VERSION "xyz"

NS_ :

BS_:

BU_: CabDisplay2 SafetyRestraintSystem AftertreatmentSystemGasOutlet AftertreatmentSystemGasIntake Turbocharger OnBoardDataLogger OffBoardDiagnosticTool2 OffBoardDiagnosticTool1 FileServer ParkingBrakeController SeatControl2 FanDriveController SteeringColumnUnit CommunicationUnitRadio CommunicationUnitSatellite CommunicationUnitCellular PropulsionBatteryCharger ChassisController2 ChassisController1 EngineValveControl AuxiliaryHeater2 AuxiliaryHeater1 ClutchUnit RampControl InformationSystem1 SuspensionSystemController2 OilSensor VehicleDynamicStability ExhaustEmissionController TransmissionDisplay2 TransmissionDisplay1 ClimateControl2 WaterPumpController RearAxleSteeringController LightingOperatorControl SeatController1 IgnitionController2 IgnitionController1 TirePressureController CabController2 CabController1 PneumaticSystemController SuspensionSystemController1 HydraulicPumpController EnduranceBrakingSystem RetarderExhaustEngine2 OnBoardDiagnosticUnit HeadwayController RetarderExhaustEngine1 CabDisplay1 ManagementComputer VirtualTerminal OffVehicleGateway PowerTakeOffFront HitchControl AuxiliaryValveControl BodyController TractorTrailerBridge1 StarterSystem ElectricalSystem VehicleSecurity VehicleNavigation AerodynamicControl ElectricalChargingSystem ClimateControl1 TripRecorder InstrumentCluster SuspensionDriveAxle2 SuspensionDriveAxle1 SuspensionSteerAxle SteeringController FuelSystem CruiseControl RetarderDriveline RetarderEngine BrakesDriveAxle2 BrakesDriveAxle1 BrakesSystemController BrakesSteerAxle AxleDrive2 AxleDrive1 AxleSteering PowerTakeOff ShiftConsoleSecondary ShiftConsolePrimary Transmission2 Transmission1 Engine2 Engine1

BO_ 2563833598 CL: 8 Vector__XXX
 SG_ IlluminationBrightnessPercent : 0|8@1+ (0.4,0) [0|100] "%" Vector__XXX

BO_ 2566843390 CI: 8 Vector__XXX

BO_ 2566844926 CCVS: 8 Vector__XXX
 SG_ ParkBrakeReleaseInhibitRq : 6|2@1+ (1,0) [0|3] "" Vector__XXX
 SG_ EngShutdownOverrideSwitch : 62|2@1+ (1,0) [0|3] "" Vector__XXX
 SG_ EngTestModeSwitch : 60|2@1+ (1,0) [0|3] "" Vector__XXX
 SG_ EngIdleDecrementSwitch : 58|2@1+ (1,0) [0|3] "" Vector__XXX
 SG_ EngIdleIncrementSwitch : 56|2@1+ (1,0) [0|3] "" Vector__XXX
 SG_ CruiseCtrlStates : 53|3@1+ (1,0) [0|7] "" Vector__XXX
 SG_ PTOState : 48|5@1+ (1,0) [0|31] "" Vector__XXX
 SG_ CruiseCtrlSetSpeed : 40|8@1+ (1,0) [0|250] "km/h" Vector__XXX
 SG_ CruiseCtrlAccelerateSwitch : 38|2@1+ (1,0) [0|3] "" Vector__XXX
 SG_ CruiseCtrlResumeSwitch : 36|2@1+ (1,0) [0|3] "" Vector__XXX
 SG_ CruiseCtrlCoastSwitch : 34|2@1+ (1,0) [0|3] "" Vector__XXX
 SG_ CruiseCtrlSetSwitch : 32|2@1+ (1,0) [0|3] "" Vector__XXX
 SG_ ClutchSwitch : 30|2@1+ (1,0) [0|3] "" Vector__XXX
 SG_ BrakeSwitch : 28|2@1+ (1,0) [0|3] "" Vector__XXX
 SG_ CruiseCtrlEnableSwitch : 26|2@1+ (1,0) [0|3] "" Vector__XXX
 SG_ CruiseCtrlActive : 24|2@1+ (1,0) [0|3] "" Vector__XXX
 SG_ WheelBasedVehicleSpeed : 8|16@1+ (0.00390625,0) [0|250.996] "km/h" Vector__XXX
 SG_ CruiseCtrlPauseSwitch : 4|2@1+ (1,0) [0|3] "" Vector__XXX
 SG_ ParkingBrakeSwitch : 2|2@1+ (1,0) [0|3] "" Vector__XXX
 SG_ TwoSpeedAxleSwitch : 0|2@1+ (1,0) [0|3] "" Vector__XXX

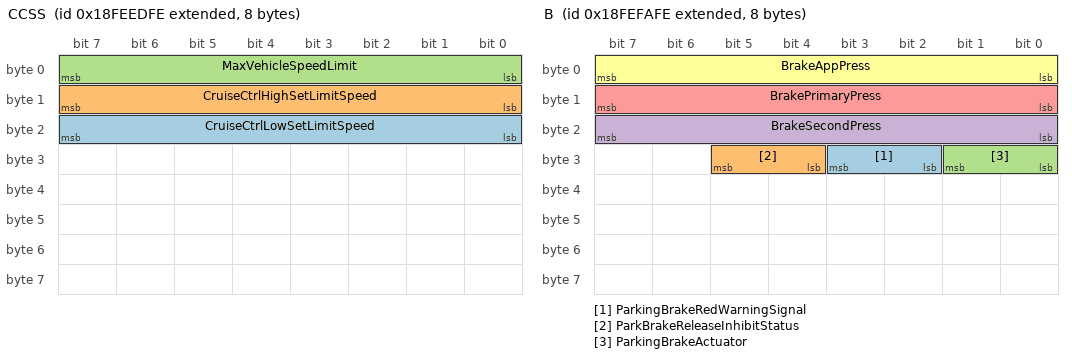
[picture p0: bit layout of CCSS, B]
BO_ 2566843902 CCSS: 8 Vector__XXX
 SG_ CruiseCtrlLowSetLimitSpeed : 16|8@1+ (1,0) [0|250] "km/h" Vector__XXX
 SG_ CruiseCtrlHighSetLimitSpeed : 8|8@1+ (1,0) [0|250] "km/h" Vector__XXX
 SG_ MaxVehicleSpeedLimit : 0|8@1+ (1,0) [0|250] "km/h" Vector__XXX

BO_ 2566809598 CCC: 8 Vector__XXX
 SG_ AuxHeaterMaxOutputPower : 0|16@1+ (2,0) [0|128510] "W" Vector__XXX

BO_ 2633940222 CBI: 16 Vector__XXX
 SG_ TripServiceBrakeApps : 96|32@1+ (1,0) [0|4227858431] "" Vector__XXX
 SG_ TripServiceBrakeDistance : 64|32@1+ (0.125,0) [0|526385151.9] "km" Vector__XXX
 SG_ TripCompressionBrakeDistance : 32|32@1+ (0.125,0) [0|526385151.9] "km" Vector__XXX
 SG_ TotalCompressionBrakeDistance : 0|32@1+ (0.125,0) [0|526385151.9] "km" Vector__XXX

BO_ 2566775294 CACI: 8 Vector__XXX
 SG_ CbA_CRfrgrntCmprssorOutletPress : 0|8@1+ (16,0) [0|4000] "kPa" Vector__XXX

BO_ 2566803710 BT1: 8 Vector__XXX
 SG_ Battery2Temp : 8|8@1+ (1,-40) [-40|210] "deg" Vector__XXX
 SG_ Battery1Temp : 0|8@1+ (1,-40) [-40|210] "deg" Vector__XXX

BO_ 2566809342 BM: 8 Vector__XXX
 SG_ BatteryMainSwitchHoldState : 0|2@1+ (1,0) [0|3] "" Vector__XXX

BO_ 2365446910 BJM3: 8 Vector__XXX
 SG_ Joystick3XAxisDetentPosStatus : 38|2@1+ (1,0) [0|3] "" Vector__XXX
 SG_ Joystick3Button9PressedStatus : 62|2@1+ (1,0) [0|3] "" Vector__XXX
 SG_ Joystick3Button10PressedStatus : 60|2@1+ (1,0) [0|3] "" Vector__XXX
 SG_ Joystick3Button11PressedStatus : 58|2@1+ (1,0) [0|3] "" Vector__XXX
 SG_ Joystick3Button12PressedStatus : 56|2@1+ (1,0) [0|3] "" Vector__XXX
 SG_ Joystick3YAxisDetentPosStatus : 36|2@1+ (1,0) [0|3] "" Vector__XXX
 SG_ Joystick3YAxisPos : 22|10@1+ (0.1,0) [0|102] "%" Vector__XXX
 SG_ Jystck3YAxsLvrFrwrdPstvPsStatus : 20|2@1+ (1,0) [0|3] "" Vector__XXX
 SG_ Jystck3YAxsLvrBckNgtvePosStatus : 18|2@1+ (1,0) [0|3] "" Vector__XXX
 SG_ Joystick3YAxisNeutralPosStatus : 16|2@1+ (1,0) [0|3] "" Vector__XXX
 SG_ Joystick3XAxisPos : 6|10@1+ (0.1,0) [0|102] "%" Vector__XXX
 SG_ Jystck3XAxsLvrRghtPstvPosStatus : 4|2@1+ (1,0) [0|3] "" Vector__XXX
 SG_ Jystck3XAxsLvrLftNgtvePosStatus : 2|2@1+ (1,0) [0|3] "" Vector__XXX
 SG_ Joystick3XAxisNeutralPosStatus : 0|2@1+ (1,0) [0|3] "" Vector__XXX
 SG_ Joystick3Button5PressedStatus : 54|2@1+ (1,0) [0|3] "" Vector__XXX
 SG_ Joystick3Button6PressedStatus : 52|2@1+ (1,0) [0|3] "" Vector__XXX
 SG_ Joystick3Button7PressedStatus : 50|2@1+ (1,0) [0|3] "" Vector__XXX
 SG_ Joystick3Button8PressedStatus : 48|2@1+ (1,0) [0|3] "" Vector__XXX
 SG_ Joystick3Button1PressedStatus : 46|2@1+ (1,0) [0|3] "" Vector__XXX
 SG_ Joystick3Button2PressedStatus : 44|2@1+ (1,0) [0|3] "" Vector__XXX
 SG_ Joystick3Button3PressedStatus : 42|2@1+ (1,0) [0|3] "" Vector__XXX
 SG_ Joystick3Button4PressedStatus : 40|2@1+ (1,0) [0|3] "" Vector__XXX

BO_ 2365446398 BJM2: 8 Vector__XXX
 SG_ Joystick2XAxisDetentPosStatus : 38|2@1+ (1,0) [0|3] "" Vector__XXX
 SG_ Joystick2YAxisDetentPosStatus : 36|2@1+ (1,0) [0|3] "" Vector__XXX
 SG_ Joystick2YAxisPos : 22|10@1+ (0.1,0) [0|102] "%" Vector__XXX
 SG_ Jystck2YAxsLvrFrwrdPstvPsStatus : 20|2@1+ (1,0) [0|3] "" Vector__XXX
 SG_ Jystck2YAxsLvrBckNgtvePosStatus : 18|2@1+ (1,0) [0|3] "" Vector__XXX
 SG_ Joystick2YAxisNeutralPosStatus : 16|2@1+ (1,0) [0|3] "" Vector__XXX
 SG_ Joystick2XAxisPos : 6|10@1+ (0.1,0) [0|102] "%" Vector__XXX
 SG_ Jystck2XAxsLvrRghtPstvPosStatus : 4|2@1+ (1,0) [0|3] "" Vector__XXX
 SG_ Jystck2XAxsLvrLftNgtvePosStatus : 2|2@1+ (1,0) [0|3] "" Vector__XXX
 SG_ Joystick2XAxisNeutralPosStatus : 0|2@1+ (1,0) [0|3] "" Vector__XXX
 SG_ Joystick2Button9PressedStatus : 62|2@1+ (1,0) [0|3] "" Vector__XXX
 SG_ Joystick2Button10PressedStatus : 60|2@1+ (1,0) [0|3] "" Vector__XXX
 SG_ Joystick2Button11PressedStatus : 58|2@1+ (1,0) [0|3] "" Vector__XXX
 SG_ Joystick2Button12PressedStatus : 56|2@1+ (1,0) [0|3] "" Vector__XXX
 SG_ Joystick2Button5PressedStatus : 54|2@1+ (1,0) [0|3] "" Vector__XXX
 SG_ Joystick2Button6PressedStatus : 52|2@1+ (1,0) [0|3] "" Vector__XXX
 SG_ Joystick2Button7PressedStatus : 50|2@1+ (1,0) [0|3] "" Vector__XXX
 SG_ Joystick2Button8PressedStatus : 48|2@1+ (1,0) [0|3] "" Vector__XXX
 SG_ Joystick2Button1PressedStatus : 46|2@1+ (1,0) [0|3] "" Vector__XXX
 SG_ Joystick2Button2PressedStatus : 44|2@1+ (1,0) [0|3] "" Vector__XXX
 SG_ Joystick2Button3PressedStatus : 42|2@1+ (1,0) [0|3] "" Vector__XXX
 SG_ Joystick2Button4PressedStatus : 40|2@1+ (1,0) [0|3] "" Vector__XXX

BO_ 2365445886 BJM1: 8 Vector__XXX
 SG_ Joystick1XAxisDetentPosStatus : 38|2@1+ (1,0) [0|3] "" Vector__XXX
 SG_ Joystick1YAxisDetentPosStatus : 36|2@1+ (1,0) [0|3] "" Vector__XXX
 SG_ Joystick1YAxisPos : 22|10@1+ (0.1,0) [0|102] "%" Vector__XXX
 SG_ Jystck1YAxsLvrFrwrdPstvPsStatus : 20|2@1+ (1,0) [0|3] "" Vector__XXX
 SG_ Jystck1YAxsLvrBckNgtvePosStatus : 18|2@1+ (1,0) [0|3] "" Vector__XXX
 SG_ Joystick1YAxisNeutralPosStatus : 16|2@1+ (1,0) [0|3] "" Vector__XXX
 SG_ Joystick1XAxisPos : 6|10@1+ (0.1,0) [0|102] "%" Vector__XXX
 SG_ Joystick1Button9PressedStatus : 62|2@1+ (1,0) [0|3] "" Vector__XXX
 SG_ Joystick1Button10PressedStatus : 60|2@1+ (1,0) [0|3] "" Vector__XXX
 SG_ Joystick1Button11PressedStatus : 58|2@1+ (1,0) [0|3] "" Vector__XXX
 SG_ Joystick1Button12PressedStatus : 56|2@1+ (1,0) [0|3] "" Vector__XXX
 SG_ Joystick1Button5PressedStatus : 54|2@1+ (1,0) [0|3] "" Vector__XXX
 SG_ Joystick1Button6PressedStatus : 52|2@1+ (1,0) [0|3] "" Vector__XXX
 SG_ Joystick1Button7PressedStatus : 50|2@1+ (1,0) [0|3] "" Vector__XXX
 SG_ Joystick1Button8PressedStatus : 48|2@1+ (1,0) [0|3] "" Vector__XXX
 SG_ Joystick1Button1PressedStatus : 46|2@1+ (1,0) [0|3] "" Vector__XXX
 SG_ Joystick1Button2PressedStatus : 44|2@1+ (1,0) [0|3] "" Vector__XXX
 SG_ Joystick1Button3PressedStatus : 42|2@1+ (1,0) [0|3] "" Vector__XXX
 SG_ Joystick1Button4PressedStatus : 40|2@1+ (1,0) [0|3] "" Vector__XXX
 SG_ Jystck1XAxsLvrRghtPstvPosStatus : 4|2@1+ (1,0) [0|3] "" Vector__XXX
 SG_ Jystck1XAxsLvrLftNgtvePosStatus : 2|2@1+ (1,0) [0|3] "" Vector__XXX
 SG_ Joystick1XAxisNeutralPosStatus : 0|2@1+ (1,0) [0|3] "" Vector__XXX

BO_ 2566847230 B: 8 Vector__XXX
 SG_ ParkingBrakeRedWarningSignal : 26|2@1+ (1,0) [0|3] "" Vector__XXX
 SG_ ParkBrakeReleaseInhibitStatus : 28|2@1+ (1,0) [0|3] "" Vector__XXX
 SG_ ParkingBrakeActuator : 24|2@1+ (1,0) [0|3] "" Vector__XXX
 SG_ BrakeSecondPress : 16|8@1+ (4,0) [0|1000] "kPa" Vector__XXX
 SG_ BrakePrimaryPress : 8|8@1+ (4,0) [0|1000] "kPa" Vector__XXX
 SG_ BrakeAppPress : 0|8@1+ (4,0) [0|1000] "kPa" Vector__XXX

BO_ 2566848254 AWPP: 8 Vector__XXX
 SG_ AuxPumpPress : 0|8@1+ (16,0) [0|4000] "kPa" Vector__XXX

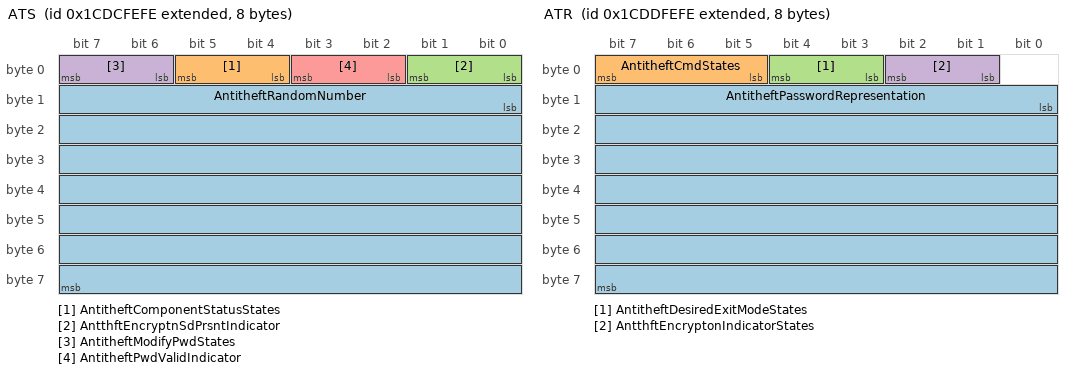
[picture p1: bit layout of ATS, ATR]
BO_ 2631728894 ATS: 8 Vector__XXX
 SG_ AntitheftRandomNumber : 8|56@1+ (1,0) [0|255] "" Vector__XXX
 SG_ AntitheftComponentStatusStates : 4|2@1+ (1,0) [0|3] "" Vector__XXX
 SG_ AntthftEncryptnSdPrsntIndicator : 0|2@1+ (1,0) [0|3] "" Vector__XXX
 SG_ AntitheftModifyPwdStates : 6|2@1+ (1,0) [0|3] "" Vector__XXX
 SG_ AntitheftPwdValidIndicator : 2|2@1+ (1,0) [0|3] "" Vector__XXX

BO_ 2631794430 ATR: 8 Vector__XXX
 SG_ AntitheftPasswordRepresentation : 8|56@1+ (1,0) [0|255] "" Vector__XXX
 SG_ AntitheftCmdStates : 5|3@1+ (1,0) [0|7] "" Vector__XXX
 SG_ AntitheftDesiredExitModeStates : 3|2@1+ (1,0) [0|3] "" Vector__XXX
 SG_ AntthftEncryptonIndicatorStates : 1|2@1+ (1,0) [0|3] "" Vector__XXX

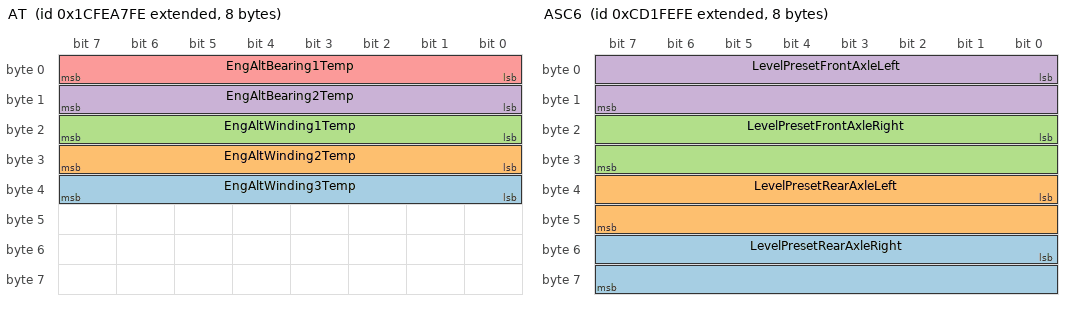
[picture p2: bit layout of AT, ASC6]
BO_ 2633934846 AT: 8 Vector__XXX
 SG_ EngAltWinding3Temp : 32|8@1+ (1,-40) [-40|210] "deg" Vector__XXX
 SG_ EngAltWinding2Temp : 24|8@1+ (1,-40) [-40|210] "deg" Vector__XXX
 SG_ EngAltWinding1Temp : 16|8@1+ (1,-40) [-40|210] "deg" Vector__XXX
 SG_ EngAltBearing2Temp : 8|8@1+ (1,-40) [-40|210] "deg" Vector__XXX
 SG_ EngAltBearing1Temp : 0|8@1+ (1,-40) [-40|210] "deg" Vector__XXX

BO_ 2362572542 ASC6: 8 Vector__XXX
 SG_ LevelPresetRearAxleRight : 48|16@1+ (0.1,-3200) [-3200|3225.5] "mm" Vector__XXX
 SG_ LevelPresetRearAxleLeft : 32|16@1+ (0.1,-3200) [-3200|3225.5] "mm" Vector__XXX
 SG_ LevelPresetFrontAxleRight : 16|16@1+ (0.1,-3200) [-3200|3225.5] "mm" Vector__XXX
 SG_ LevelPresetFrontAxleLeft : 0|16@1+ (0.1,-3200) [-3200|3225.5] "mm" Vector__XXX

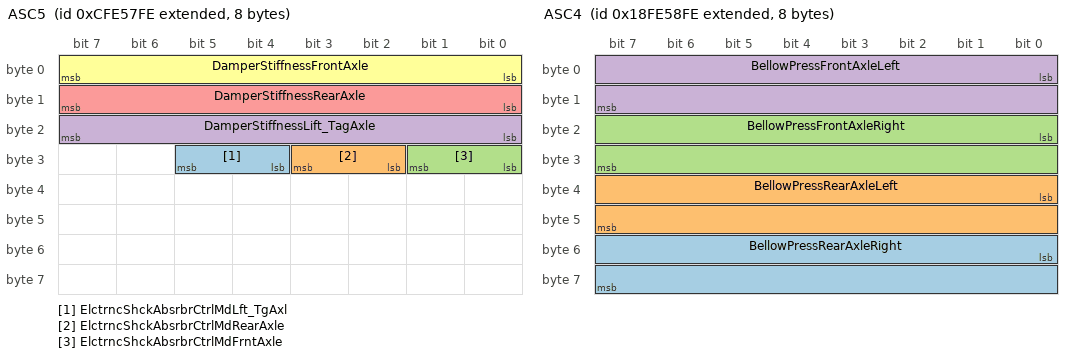
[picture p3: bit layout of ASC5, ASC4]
BO_ 2365478910 ASC5: 8 Vector__XXX
 SG_ ElctrncShckAbsrbrCtrlMdLft_TgAxl : 28|2@1+ (1,0) [0|3] "" Vector__XXX
 SG_ ElctrncShckAbsrbrCtrlMdRearAxle : 26|2@1+ (1,0) [0|3] "" Vector__XXX
 SG_ ElctrncShckAbsrbrCtrlMdFrntAxle : 24|2@1+ (1,0) [0|3] "" Vector__XXX
 SG_ DamperStiffnessLift_TagAxle : 16|8@1+ (0.4,0) [0|100] "%" Vector__XXX
 SG_ DamperStiffnessRearAxle : 8|8@1+ (0.4,0) [0|100] "%" Vector__XXX
 SG_ DamperStiffnessFrontAxle : 0|8@1+ (0.4,0) [0|100] "%" Vector__XXX

BO_ 2566805758 ASC4: 8 Vector__XXX
 SG_ BellowPressRearAxleRight : 48|16@1+ (0.1,0) [0|6425.5] "kPa" Vector__XXX
 SG_ BellowPressRearAxleLeft : 32|16@1+ (0.1,0) [0|6425.5] "kPa" Vector__XXX
 SG_ BellowPressFrontAxleRight : 16|16@1+ (0.1,0) [0|6425.5] "kPa" Vector__XXX
 SG_ BellowPressFrontAxleLeft : 0|16@1+ (0.1,0) [0|6425.5] "kPa" Vector__XXX

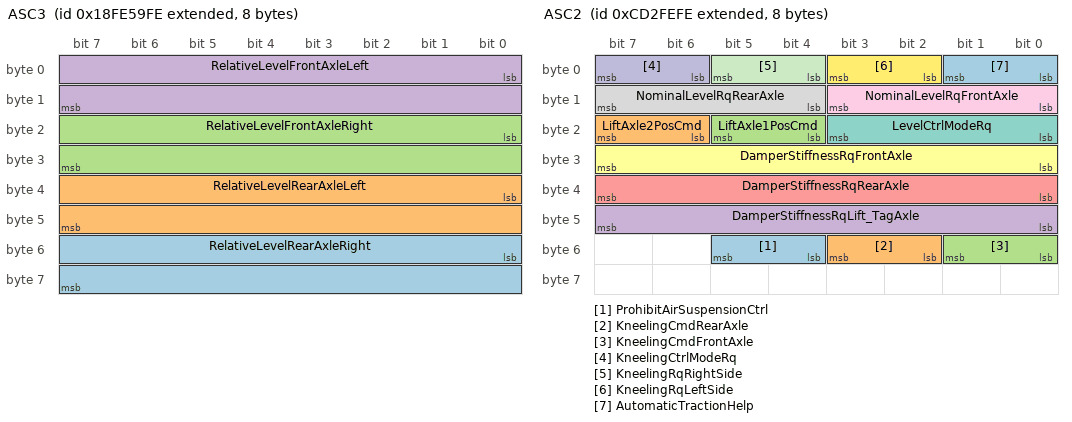
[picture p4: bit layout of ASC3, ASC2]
BO_ 2566806014 ASC3: 8 Vector__XXX
 SG_ RelativeLevelRearAxleRight : 48|16@1+ (0.1,-3200) [-3200|3225.5] "mm" Vector__XXX
 SG_ RelativeLevelRearAxleLeft : 32|16@1+ (0.1,-3200) [-3200|3225.5] "mm" Vector__XXX
 SG_ RelativeLevelFrontAxleRight : 16|16@1+ (0.1,-3200) [-3200|3225.5] "mm" Vector__XXX
 SG_ RelativeLevelFrontAxleLeft : 0|16@1+ (0.1,-3200) [-3200|3225.5] "mm" Vector__XXX

BO_ 2362638078 ASC2: 8 Vector__XXX
 SG_ ProhibitAirSuspensionCtrl : 52|2@1+ (1,0) [0|3] "" Vector__XXX
 SG_ KneelingCmdRearAxle : 50|2@1+ (1,0) [0|3] "" Vector__XXX
 SG_ KneelingCmdFrontAxle : 48|2@1+ (1,0) [0|3] "" Vector__XXX
 SG_ DamperStiffnessRqLift_TagAxle : 40|8@1+ (0.4,0) [0|100] "%" Vector__XXX
 SG_ DamperStiffnessRqRearAxle : 32|8@1+ (0.4,0) [0|100] "%" Vector__XXX
 SG_ DamperStiffnessRqFrontAxle : 24|8@1+ (0.4,0) [0|100] "%" Vector__XXX
 SG_ LevelCtrlModeRq : 16|4@1+ (1,0) [0|15] "" Vector__XXX
 SG_ NominalLevelRqRearAxle : 12|4@1+ (1,0) [0|15] "" Vector__XXX
 SG_ NominalLevelRqFrontAxle : 8|4@1+ (1,0) [0|15] "" Vector__XXX
 SG_ KneelingCtrlModeRq : 6|2@1+ (1,0) [0|3] "" Vector__XXX
 SG_ KneelingRqRightSide : 4|2@1+ (1,0) [0|3] "" Vector__XXX
 SG_ KneelingRqLeftSide : 2|2@1+ (1,0) [0|3] "" Vector__XXX
 SG_ AutomaticTractionHelp : 0|2@1+ (1,0) [0|3] "" Vector__XXX
 SG_ LiftAxle2PosCmd : 22|2@1+ (1,0) [0|3] "" Vector__XXX
 SG_ LiftAxle1PosCmd : 20|2@1+ (1,0) [0|3] "" Vector__XXX

BO_ 2365479678 ASC1: 8 Vector__XXX
 SG_ SspensionCtrlRefusalInformation : 56|4@1+ (1,0) [0|15] "" Vector__XXX
 SG_ SuspensionRemoteCtrl2 : 50|2@1+ (1,0) [0|3] "" Vector__XXX
 SG_ SuspensionRemoteCtrl1 : 48|2@1+ (1,0) [0|3] "" Vector__XXX
 SG_ RearAxleInBumperRange : 42|2@1+ (1,0) [0|3] "" Vector__XXX
 SG_ FrontAxleInBumperRange : 40|2@1+ (1,0) [0|3] "" Vector__XXX
 SG_ DoorRelease : 36|2@1+ (1,0) [0|3] "" Vector__XXX
 SG_ VehicleMotionInhibit : 34|2@1+ (1,0) [0|3] "" Vector__XXX
 SG_ SecurityDevice : 32|2@1+ (1,0) [0|3] "" Vector__XXX
 SG_ LevelCtrlMode : 28|4@1+ (1,0) [0|15] "" Vector__XXX
 SG_ KneelingInformation : 24|4@1+ (1,0) [0|15] "" Vector__XXX
 SG_ LiftingCtrlModeRearAxle : 22|2@1+ (1,0) [0|3] "" Vector__XXX
 SG_ LiftingCtrlModeFrontAxle : 20|2@1+ (1,0) [0|3] "" Vector__XXX
 SG_ LoweringCtrlModeRearAxle : 18|2@1+ (1,0) [0|3] "" Vector__XXX
 SG_ LoweringCtrlModeFrontAxle : 16|2@1+ (1,0) [0|3] "" Vector__XXX
 SG_ AboveNominalLevelRearAxle : 14|2@1+ (1,0) [0|3] "" Vector__XXX
 SG_ AboveNominalLevelFrontAxle : 12|2@1+ (1,0) [0|3] "" Vector__XXX
 SG_ BelowNominalLevelRearAxle : 10|2@1+ (1,0) [0|3] "" Vector__XXX
 SG_ BelowNominalLevelFrontAxle : 8|2@1+ (1,0) [0|3] "" Vector__XXX
 SG_ NominalLevelRearAxle : 4|4@1+ (1,0) [0|15] "" Vector__XXX
 SG_ NominalLevelFrontAxle : 0|4@1+ (1,0) [0|15] "" Vector__XXX
 SG_ LiftAxle2Pos : 46|2@1+ (1,0) [0|3] "" Vector__XXX
 SG_ LiftAxle1Pos : 38|2@1+ (1,0) [0|3] "" Vector__XXX

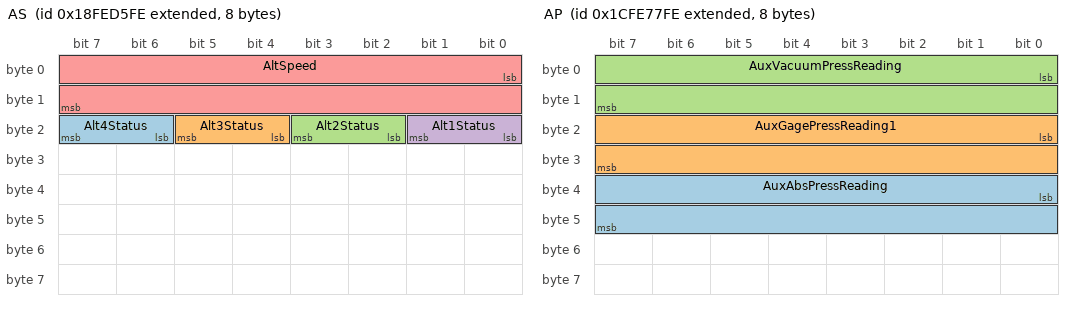
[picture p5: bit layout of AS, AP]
BO_ 2566837758 AS: 8 Vector__XXX
 SG_ Alt4Status : 22|2@1+ (1,0) [0|3] "" Vector__XXX
 SG_ Alt3Status : 20|2@1+ (1,0) [0|3] "" Vector__XXX
 SG_ Alt2Status : 18|2@1+ (1,0) [0|3] "" Vector__XXX
 SG_ Alt1Status : 16|2@1+ (1,0) [0|3] "" Vector__XXX
 SG_ AltSpeed : 0|16@1+ (0.5,0) [0|32127.5] "rpm" Vector__XXX

BO_ 2633922558 AP: 8 Vector__XXX
 SG_ AuxAbsPressReading : 32|16@1+ (0.5,0) [0|32127.5] "kPa" Vector__XXX
 SG_ AuxGagePressReading1 : 16|16@1+ (0.5,0) [0|32127.5] "kPa" Vector__XXX
 SG_ AuxVacuumPressReading : 0|16@1+ (0.5,0) [0|32127.5] "kPa" Vector__XXX

BO_ 2566775038 AMB2: 8 Vector__XXX
 SG_ SolarSensorMax : 8|8@1+ (0.4,0) [0|100] "mW/cm�" Vector__XXX
 SG_ SolarIntensityPercent : 0|8@1+ (0.4,0) [0|100] "%" Vector__XXX

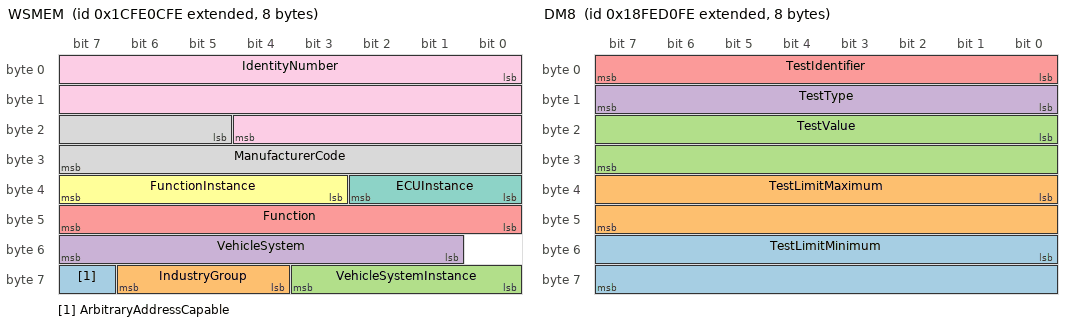
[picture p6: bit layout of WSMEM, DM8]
BO_ 2633895166 WSMEM: 8 Vector__XXX
 SG_ ArbitraryAddressCapable : 63|1@1+ (1,0) [0|1] "" Vector__XXX
 SG_ IndustryGroup : 60|3@1+ (1,0) [0|7] "" Vector__XXX
 SG_ VehicleSystemInstance : 56|4@1+ (1,0) [0|15] "" Vector__XXX
 SG_ VehicleSystem : 49|7@1+ (1,0) [0|127] "" Vector__XXX
 SG_ Function : 40|8@1+ (1,0) [0|255] "" Vector__XXX
 SG_ FunctionInstance : 35|5@1+ (1,0) [0|31] "" Vector__XXX
 SG_ ECUInstance : 32|3@1+ (1,0) [0|7] "" Vector__XXX
 SG_ ManufacturerCode : 21|11@1+ (1,0) [0|2047] "" Vector__XXX
 SG_ IdentityNumber : 0|21@1+ (1,0) [0|2097152] "" Vector__XXX

BO_ 2566836478 DM8: 8 Vector__XXX
 SG_ TestLimitMinimum : 48|16@1+ (1,0) [0|64255] "" Vector__XXX
 SG_ TestLimitMaximum : 32|16@1+ (1,0) [0|64255] "" Vector__XXX
 SG_ TestValue : 16|16@1+ (1,0) [0|64255] "" Vector__XXX
 SG_ TestType : 8|8@1+ (1,0) [1|64] "" Vector__XXX
 SG_ TestIdentifier : 0|8@1+ (1,0) [1|64] "" Vector__XXX

BO_ 2565078782 DM7: 8 Vector__XXX
 SG_ TestIdentifier : 0|8@1+ (1,0) [1|64] "" Vector__XXX

BO_ 2566836222 DM6: 22 Vector__XXX
 SG_ SPN5 : 144|16@1+ (1,0) [0|65536] "" Vector__XXX
 SG_ SPN4 : 112|16@1+ (1,0) [0|65536] "" Vector__XXX
 SG_ SPN3 : 80|16@1+ (1,0) [0|65536] "" Vector__XXX
 SG_ SPN2 : 48|16@1+ (1,0) [0|65536] "" Vector__XXX
 SG_ FailureModeIdentifier5 : 160|5@1+ (1,0) [0|0] "" Vector__XXX
 SG_ FailureModeIdentifier4 : 128|5@1+ (1,0) [0|0] "" Vector__XXX
 SG_ FlashRedStopLamp : 12|2@1+ (1,0) [0|3] "" Vector__XXX
 SG_ FlashProtectLamp : 8|2@1+ (1,0) [0|3] "" Vector__XXX
 SG_ FlashMalfuncIndicatorLamp : 14|2@1+ (1,0) [0|3] "" Vector__XXX
 SG_ FlashAmberWarningLamp : 10|2@1+ (1,0) [0|3] "" Vector__XXX
 SG_ FailureModeIdentifier3 : 96|5@1+ (1,0) [0|0] "" Vector__XXX
 SG_ FailureModeIdentifier2 : 64|5@1+ (1,0) [0|0] "" Vector__XXX
 SG_ SPNConversionMethod5 : 175|1@1+ (1,0) [0|1] "" Vector__XXX
 SG_ SPNConversionMethod4 : 143|1@1+ (1,0) [0|1] "" Vector__XXX
 SG_ SPNConversionMethod3 : 111|1@1+ (1,0) [0|1] "" Vector__XXX
 SG_ SPNConversionMethod2 : 79|1@1+ (1,0) [0|1] "" Vector__XXX
 SG_ OccurenceCount5 : 168|7@1+ (1,0) [0|126] "" Vector__XXX
 SG_ OccurenceCount4 : 136|7@1+ (1,0) [0|126] "" Vector__XXX
 SG_ OccurenceCount3 : 104|7@1+ (1,0) [0|126] "" Vector__XXX
 SG_ OccurenceCount2 : 72|7@1+ (1,0) [0|126] "" Vector__XXX
 SG_ OccurenceCount1 : 40|7@1+ (1,0) [0|126] "" Vector__XXX
 SG_ SPNConversionMethod1 : 47|1@1+ (1,0) [0|1] "" Vector__XXX
 SG_ FailureModeIdentifier1 : 32|5@1+ (1,0) [0|0] "" Vector__XXX
 SG_ SPN1 : 16|16@1+ (1,0) [0|65536] "" Vector__XXX
 SG_ MalfunctionIndicatorLampStatus : 6|2@1+ (1,0) [0|3] "" Vector__XXX
 SG_ RedStopLampState : 4|2@1+ (1,0) [0|3] "" Vector__XXX
 SG_ AmberWarningLampStatus : 2|2@1+ (1,0) [0|3] "" Vector__XXX
 SG_ ProtectLampStatus : 0|2@1+ (1,0) [0|3] "" Vector__XXX
 SG_ SPN5High : 165|3@1+ (1,0) [0|7] "" Vector__XXX
 SG_ SPN4High : 133|3@1+ (1,0) [0|7] "" Vector__XXX
 SG_ SPN3High : 101|3@1+ (1,0) [0|7] "" Vector__XXX
 SG_ SPN2High : 69|3@1+ (1,0) [0|7] "" Vector__XXX
 SG_ SPN1High : 37|3@1+ (1,0) [0|7] "" Vector__XXX

BO_ 2566835966 DM5: 8 Vector__XXX
 SG_ MisfireMonitoringSupport : 24|1@1+ (1,0) [0|0] "" Vector__XXX
 SG_ OBDCompliance : 16|8@1+ (1,0) [0|240] "" Vector__XXX
 SG_ PreviouslyActiveTroubleCodes : 8|8@1+ (1,0) [0|240] "" Vector__XXX
 SG_ ActiveTroubleCodes : 0|8@1+ (1,0) [0|240] "" Vector__XXX
 SG_ SecondAirSystemMonStatus : 51|1@1+ (1,0) [0|1] "" Vector__XXX
 SG_ EvaporativeSystemMonStatus : 50|1@1+ (1,0) [0|1] "" Vector__XXX
 SG_ ACSystemRefrigerantMonStatus : 52|1@1+ (1,0) [0|1] "" Vector__XXX
 SG_ OxygenSensorHeaterMonStatus : 54|1@1+ (1,0) [0|1] "" Vector__XXX
 SG_ OxygenSensorMonStatus : 53|1@1+ (1,0) [0|1] "" Vector__XXX
 SG_ EGRSystemMonitoringStatus : 55|1@1+ (1,0) [0|1] "" Vector__XXX
 SG_ CatalystMonStatus : 48|1@1+ (1,0) [0|1] "" Vector__XXX
 SG_ ColdStartAidSystemMonStatus : 56|1@1+ (1,0) [0|1] "" Vector__XXX
 SG_ HeatedCatalystMonStatus : 49|1@1+ (1,0) [0|0] "" Vector__XXX
 SG_ CatalystMonSupp : 32|1@1+ (1,0) [0|1] "" Vector__XXX
 SG_ ColdStartAidSystemMonSupp : 40|1@1+ (1,0) [0|1] "" Vector__XXX
 SG_ HeatedCatalystMonSupp : 33|1@1+ (1,0) [0|0] "" Vector__XXX
 SG_ EvaporativeSystemMonSupp : 34|1@1+ (1,0) [0|1] "" Vector__XXX
 SG_ SecondAirSystemMonSupp : 35|1@1+ (1,0) [0|1] "" Vector__XXX
 SG_ ACSystemRefrigerantMonSupp : 36|1@1+ (1,0) [0|1] "" Vector__XXX
 SG_ OxygenSensorMonSupp : 37|1@1+ (1,0) [0|1] "" Vector__XXX
 SG_ OxygenSensorHeaterMonSupp : 38|1@1+ (1,0) [0|1] "" Vector__XXX
 SG_ EGRSystemMonitoringSupp : 39|1@1+ (1,0) [0|1] "" Vector__XXX
 SG_ MisfireMonitoringStatus : 28|1@1+ (1,0) [0|0] "" Vector__XXX
 SG_ ComprehensiveCompMonStatus : 30|1@1+ (1,0) [0|1] "" Vector__XXX
 SG_ FuelSystemMonitoringStatus : 29|1@1+ (1,0) [0|1] "" Vector__XXX
 SG_ ComprehensiveComponentMonSupp : 26|1@1+ (1,0) [0|0] "" Vector__XXX
 SG_ FuelSystemMonitoringSupport : 25|1@1+ (1,0) [0|1] "" Vector__XXX

BO_ 2566835710 DM4: 13 Vector__XXX
 SG_ OccurenceCount1 : 32|7@1+ (1,0) [0|126] "" Vector__XXX
 SG_ SPNConversionMethod1 : 39|1@1+ (1,0) [0|1] "" Vector__XXX
 SG_ FailureModeIdentifier1 : 24|5@1+ (1,0) [0|0] "" Vector__XXX
 SG_ SPN1 : 8|16@1+ (1,0) [0|65536] "" Vector__XXX
 SG_ FreezeFrameLength : 0|8@1+ (1,0) [0|255] "byte" Vector__XXX
 SG_ EngSpeed : 56|16@1+ (0.125,0) [0|8031.875] "rpm" Vector__XXX
 SG_ EngTorqueMode : 40|4@1+ (1,0) [0|15] "" Vector__XXX
 SG_ EngTurboBoostPress : 48|8@1+ (2,0) [0|500] "kPa" Vector__XXX
 SG_ WheelBasedVehicleSpeed : 88|16@1+ (0.00390625,0) [0|250.996] "km/h" Vector__XXX
 SG_ EngPercentLoadAtCurrentSpeed : 72|8@1+ (1,0) [0|250] "%" Vector__XXX
 SG_ EngineCoolantTemperature : 80|8@1+ (1,-40) [-40|210] "�C" Vector__XXX
 SG_ SPN1High : 29|3@1+ (1,0) [0|7] "" Vector__XXX

BO_ 2566835454 DM3: 0 Vector__XXX

BO_ 2566764542 DM25: 13 Vector__XXX
 SG_ OccurenceCount1 : 32|7@1+ (1,0) [0|126] "" Vector__XXX
 SG_ SPNConversionMethod1 : 39|1@1+ (1,0) [0|1] "" Vector__XXX
 SG_ FailureModeIdentifier1 : 24|5@1+ (1,0) [0|0] "" Vector__XXX
 SG_ SPN1 : 8|16@1+ (1,0) [0|65536] "" Vector__XXX
 SG_ ExpandedFreezeFrameLength : 0|8@1+ (1,0) [0|255] "byte" Vector__XXX
 SG_ SPN1High : 29|3@1+ (1,0) [0|7] "" Vector__XXX

BO_ 2566764286 DM24: 12 Vector__XXX
 SG_ SPNSupported1High : 21|3@1+ (1,0) [0|7] "" Vector__XXX
 SG_ SPNSupportTypeSTR3 : 82|1@1+ (1,0) [0|1] "" Vector__XXX
 SG_ SPNSupportTypeSTR2 : 81|1@1+ (1,0) [0|1] "" Vector__XXX
 SG_ SPNSupportTypeEFF3 : 80|1@1+ (1,0) [0|1] "" Vector__XXX
 SG_ SPNSupportTypeEFF2 : 48|1@1+ (1,0) [0|1] "" Vector__XXX
 SG_ SPNSupportTypeDS3 : 50|1@1+ (1,0) [0|1] "" Vector__XXX
 SG_ SPNSupportTypeDS2 : 49|1@1+ (1,0) [0|1] "" Vector__XXX
 SG_ SPNSupported3High : 85|3@1+ (1,0) [0|7] "" Vector__XXX
 SG_ SPNSupported2High : 53|3@1+ (1,0) [0|7] "" Vector__XXX
 SG_ SPNSupported3 : 64|16@1+ (1,0) [0|65535] "" Vector__XXX
 SG_ SPNSupported2 : 32|16@1+ (1,0) [0|65535] "" Vector__XXX
 SG_ SPNDataLength3 : 88|8@1+ (1,0) [0|240] "" Vector__XXX
 SG_ SPNSupportTypeSTR1 : 18|1@1+ (1,0) [0|1] "" Vector__XXX
 SG_ SPNSupportTypeDS1 : 17|1@1+ (1,0) [0|1] "" Vector__XXX
 SG_ SPNSupportTypeEFF1 : 16|1@1+ (1,0) [0|1] "" Vector__XXX
 SG_ SPNDataLength2 : 56|8@1+ (1,0) [0|240] "" Vector__XXX
 SG_ SPNDataLength1 : 24|8@1+ (1,0) [0|240] "" Vector__XXX
 SG_ SPNSupported1 : 0|16@1+ (1,0) [0|65535] "" Vector__XXX

BO_ 2555576062 DM23: 22 Vector__XXX
 SG_ FlashRedStopLamp : 12|2@1+ (1,0) [0|3] "" Vector__XXX
 SG_ FlashProtectLamp : 8|2@1+ (1,0) [0|3] "" Vector__XXX
 SG_ FlashMalfuncIndicatorLamp : 14|2@1+ (1,0) [0|3] "" Vector__XXX
 SG_ SPN5 : 144|16@1+ (1,0) [0|65536] "" Vector__XXX
 SG_ SPN4 : 112|16@1+ (1,0) [0|65536] "" Vector__XXX
 SG_ SPN3 : 80|16@1+ (1,0) [0|65536] "" Vector__XXX
 SG_ SPN2 : 48|16@1+ (1,0) [0|65536] "" Vector__XXX
 SG_ FlashAmberWarningLamp : 10|2@1+ (1,0) [0|3] "" Vector__XXX
 SG_ FailureModeIdentifier5 : 160|5@1+ (1,0) [0|0] "" Vector__XXX
 SG_ FailureModeIdentifier4 : 128|5@1+ (1,0) [0|0] "" Vector__XXX
 SG_ OccurenceCount1 : 40|7@1+ (1,0) [0|126] "" Vector__XXX
 SG_ SPNConversionMethod1 : 47|1@1+ (1,0) [0|1] "" Vector__XXX
 SG_ FailureModeIdentifier1 : 32|5@1+ (1,0) [0|0] "" Vector__XXX
 SG_ SPN1 : 16|16@1+ (1,0) [0|65536] "" Vector__XXX
 SG_ MalfunctionIndicatorLampStatus : 6|2@1+ (1,0) [0|3] "" Vector__XXX
 SG_ RedStopLampState : 4|2@1+ (1,0) [0|3] "" Vector__XXX
 SG_ AmberWarningLampStatus : 2|2@1+ (1,0) [0|3] "" Vector__XXX
 SG_ ProtectLampStatus : 0|2@1+ (1,0) [0|3] "" Vector__XXX
 SG_ FailureModeIdentifier3 : 96|5@1+ (1,0) [0|0] "" Vector__XXX
 SG_ FailureModeIdentifier2 : 64|5@1+ (1,0) [0|0] "" Vector__XXX
 SG_ SPNConversionMethod5 : 175|1@1+ (1,0) [0|1] "" Vector__XXX
 SG_ SPNConversionMethod4 : 143|1@1+ (1,0) [0|1] "" Vector__XXX
 SG_ SPNConversionMethod3 : 111|1@1+ (1,0) [0|1] "" Vector__XXX
 SG_ SPNConversionMethod2 : 79|1@1+ (1,0) [0|1] "" Vector__XXX
 SG_ OccurenceCount5 : 168|7@1+ (1,0) [0|126] "" Vector__XXX
 SG_ OccurenceCount4 : 136|7@1+ (1,0) [0|126] "" Vector__XXX
 SG_ OccurenceCount3 : 104|7@1+ (1,0) [0|126] "" Vector__XXX
 SG_ OccurenceCount2 : 72|7@1+ (1,0) [0|126] "" Vector__XXX
 SG_ SPN5High : 165|3@1+ (1,0) [0|7] "" Vector__XXX
 SG_ SPN4High : 133|3@1+ (1,0) [0|7] "" Vector__XXX
 SG_ SPN3High : 101|3@1+ (1,0) [0|7] "" Vector__XXX
 SG_ SPN2High : 69|3@1+ (1,0) [0|7] "" Vector__XXX
 SG_ SPN1High : 37|3@1+ (1,0) [0|7] "" Vector__XXX

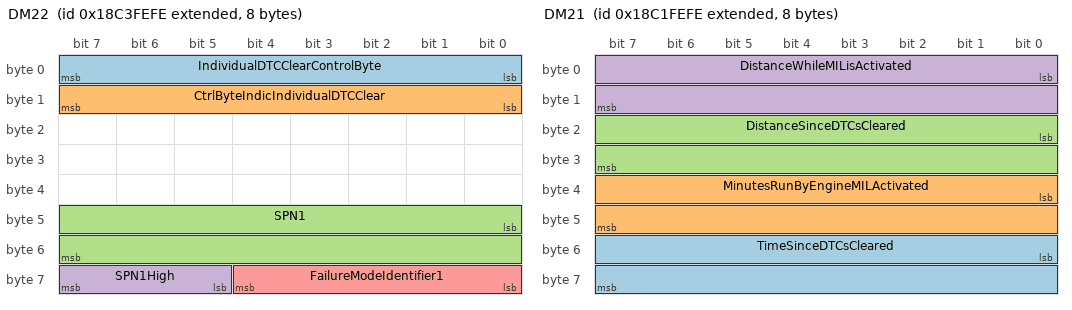
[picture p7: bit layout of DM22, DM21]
BO_ 2562981630 DM22: 8 Vector__XXX
 SG_ IndividualDTCClearControlByte : 0|8@1+ (1,0) [0|255] "" Vector__XXX
 SG_ CtrlByteIndicIndividualDTCClear : 8|8@1+ (1,0) [0|255] "" Vector__XXX
 SG_ SPN1 : 40|16@1+ (1,0) [0|65536] "" Vector__XXX
 SG_ SPN1High : 61|3@1+ (1,0) [0|7] "" Vector__XXX
 SG_ FailureModeIdentifier1 : 56|5@1+ (1,0) [0|0] "" Vector__XXX

BO_ 2562850558 DM21: 8 Vector__XXX
 SG_ TimeSinceDTCsCleared : 48|16@1+ (1,0) [0|64255] "min" Vector__XXX
 SG_ MinutesRunByEngineMILActivated : 32|16@1+ (1,0) [0|64255] "min" Vector__XXX
 SG_ DistanceSinceDTCsCleared : 16|16@1+ (1,0) [0|64255] "km" Vector__XXX
 SG_ DistanceWhileMILisActivated : 0|16@1+ (1,0) [0|64255] "km" Vector__XXX

BO_ 2562916094 DM20: 11 Vector__XXX
 SG_ ApplSysMonitorDenominator : 72|16@1+ (1,0) [0|65535] "" Vector__XXX
 SG_ ApplSysMonitorNumerator : 56|16@1+ (1,0) [0|65535] "" Vector__XXX
 SG_ SPNofApplSysMonitor : 32|24@1+ (1,0) [0|524287] "" Vector__XXX
 SG_ OBDMonitoringCondEncountered : 16|16@1+ (1,0) [0|65535] "" Vector__XXX
 SG_ IgnitionCycleCounter : 0|16@1+ (1,0) [0|65535] "" Vector__XXX

BO_ 2566835198 DM2: 22 Vector__XXX
 SG_ SPN5 : 144|16@1+ (1,0) [0|65536] "" Vector__XXX
 SG_ SPN4 : 112|16@1+ (1,0) [0|65536] "" Vector__XXX
 SG_ SPN3 : 80|16@1+ (1,0) [0|65536] "" Vector__XXX
 SG_ SPN2 : 48|16@1+ (1,0) [0|65536] "" Vector__XXX
 SG_ FailureModeIdentifier5 : 160|5@1+ (1,0) [0|0] "" Vector__XXX
 SG_ FailureModeIdentifier4 : 128|5@1+ (1,0) [0|0] "" Vector__XXX
 SG_ OccurenceCount1 : 40|7@1+ (1,0) [0|126] "" Vector__XXX
 SG_ SPNConversionMethod1 : 47|1@1+ (1,0) [0|1] "" Vector__XXX
 SG_ FailureModeIdentifier1 : 32|5@1+ (1,0) [0|0] "" Vector__XXX
 SG_ SPN1 : 16|16@1+ (1,0) [0|65536] "" Vector__XXX
 SG_ MalfunctionIndicatorLampStatus : 6|2@1+ (1,0) [0|3] "" Vector__XXX
 SG_ RedStopLampState : 4|2@1+ (1,0) [0|3] "" Vector__XXX
 SG_ AmberWarningLampStatus : 2|2@1+ (1,0) [0|3] "" Vector__XXX
 SG_ ProtectLampStatus : 0|2@1+ (1,0) [0|3] "" Vector__XXX
 SG_ FailureModeIdentifier3 : 96|5@1+ (1,0) [0|0] "" Vector__XXX
 SG_ FlashRedStopLamp : 12|2@1+ (1,0) [0|3] "" Vector__XXX
 SG_ FlashProtectLamp : 8|2@1+ (1,0) [0|3] "" Vector__XXX
 SG_ FlashMalfuncIndicatorLamp : 14|2@1+ (1,0) [0|3] "" Vector__XXX
 SG_ FlashAmberWarningLamp : 10|2@1+ (1,0) [0|3] "" Vector__XXX
 SG_ FailureModeIdentifier2 : 64|5@1+ (1,0) [0|0] "" Vector__XXX
 SG_ SPNConversionMethod5 : 175|1@1+ (1,0) [0|1] "" Vector__XXX
 SG_ SPNConversionMethod4 : 143|1@1+ (1,0) [0|1] "" Vector__XXX
 SG_ SPNConversionMethod3 : 111|1@1+ (1,0) [0|1] "" Vector__XXX
 SG_ SPNConversionMethod2 : 79|1@1+ (1,0) [0|1] "" Vector__XXX
 SG_ OccurenceCount5 : 168|7@1+ (1,0) [0|126] "" Vector__XXX
 SG_ OccurenceCount4 : 136|7@1+ (1,0) [0|126] "" Vector__XXX
 SG_ OccurenceCount3 : 104|7@1+ (1,0) [0|126] "" Vector__XXX
 SG_ OccurenceCount2 : 72|7@1+ (1,0) [0|126] "" Vector__XXX
 SG_ SPN5High : 165|3@1+ (1,0) [0|7] "" Vector__XXX
 SG_ SPN4High : 133|3@1+ (1,0) [0|7] "" Vector__XXX
 SG_ SPN3High : 101|3@1+ (1,0) [0|7] "" Vector__XXX
 SG_ SPN2High : 69|3@1+ (1,0) [0|7] "" Vector__XXX
 SG_ SPN1High : 37|3@1+ (1,0) [0|7] "" Vector__XXX

BO_ 2564030206 DM19: 20 Vector__XXX
 SG_ CalibrationID4 : 128|32@1+ (1,0) [0|4294967295] "" Vector__XXX
 SG_ CalibrationID3 : 96|32@1+ (1,0) [0|4294967295] "" Vector__XXX
 SG_ CalibrationID2 : 64|32@1+ (1,0) [0|4294967295] "" Vector__XXX
 SG_ CalibrationID1 : 32|32@1+ (1,0) [0|4294967295] "" Vector__XXX
 SG_ CalibrationVerificationNumber : 0|32@1+ (1,0) [0|4294967295] "" Vector__XXX

BO_ 2564226814 DM17: 8 Vector__XXX

BO_ 2564292350 DM16: 8 Vector__XXX
 SG_ NumberOfOccurance : 0|8@1+ (1,0) [0|0] "" Vector__XXX

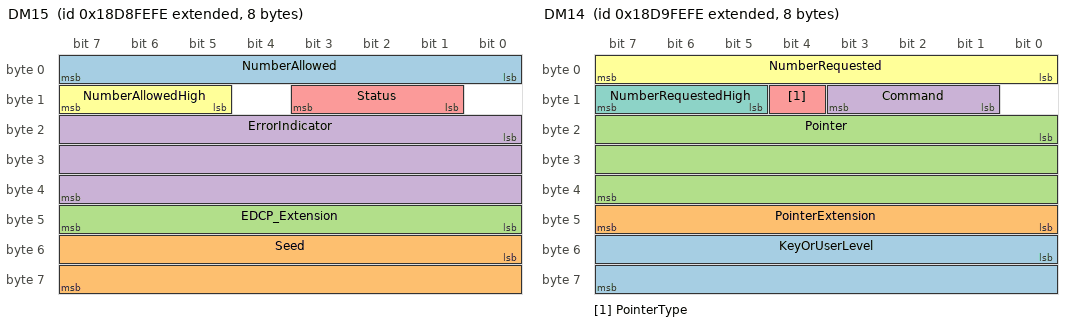
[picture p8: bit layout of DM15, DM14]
BO_ 2564357886 DM15: 8 Vector__XXX
 SG_ NumberAllowed : 0|8@1+ (1,0) [0|2047] "" Vector__XXX
 SG_ Seed : 48|16@1+ (1,0) [0|65535] "" Vector__XXX
 SG_ EDCP_Extension : 40|8@1+ (1,0) [0|255] "" Vector__XXX
 SG_ ErrorIndicator : 16|24@1+ (1,0) [0|16777215] "" Vector__XXX
 SG_ Status : 9|3@1+ (1,0) [0|7] "" Vector__XXX
 SG_ NumberAllowedHigh : 13|3@1+ (1,0) [0|7] "" Vector__XXX

BO_ 2564423422 DM14: 8 Vector__XXX
 SG_ KeyOrUserLevel : 48|16@1+ (1,0) [0|65535] "" Vector__XXX
 SG_ PointerExtension : 40|8@1+ (1,0) [0|255] "" Vector__XXX
 SG_ Pointer : 16|24@1+ (1,0) [0|16777215] "" Vector__XXX
 SG_ Command : 9|3@1+ (1,0) [0|7] "" Vector__XXX
 SG_ PointerType : 12|1@1+ (1,0) [0|1] "" Vector__XXX
 SG_ NumberRequested : 0|8@1+ (1,0) [0|2047] "" Vector__XXX
 SG_ NumberRequestedHigh : 13|3@1+ (1,0) [0|7] "" Vector__XXX

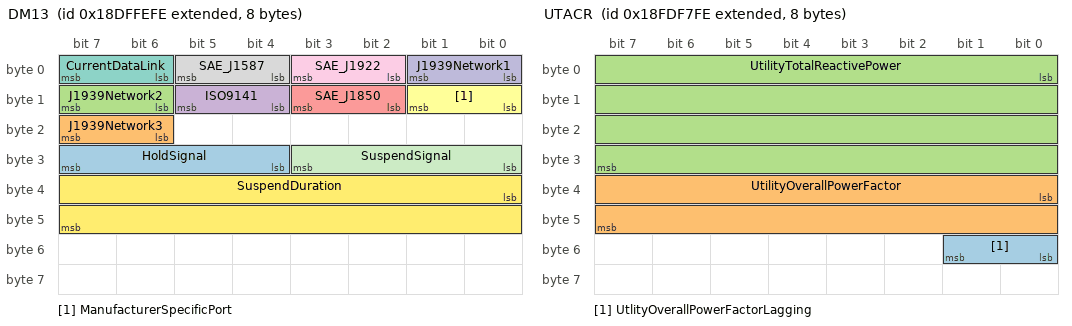
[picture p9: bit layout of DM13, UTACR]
BO_ 2564816638 DM13: 8 Vector__XXX
 SG_ HoldSignal : 28|4@1+ (1,0) [0|15] "" Vector__XXX
 SG_ J1939Network3 : 22|2@1+ (1,0) [0|3] "" Vector__XXX
 SG_ J1939Network2 : 14|2@1+ (1,0) [0|3] "" Vector__XXX
 SG_ ISO9141 : 12|2@1+ (1,0) [0|3] "" Vector__XXX
 SG_ SAE_J1850 : 10|2@1+ (1,0) [0|3] "" Vector__XXX
 SG_ ManufacturerSpecificPort : 8|2@1+ (1,0) [0|3] "" Vector__XXX
 SG_ CurrentDataLink : 6|2@1+ (1,0) [0|3] "" Vector__XXX
 SG_ SAE_J1587 : 4|2@1+ (1,0) [0|3] "" Vector__XXX
 SG_ SAE_J1922 : 2|2@1+ (1,0) [0|3] "" Vector__XXX
 SG_ J1939Network1 : 0|2@1+ (1,0) [0|3] "" Vector__XXX
 SG_ SuspendSignal : 24|4@1+ (1,0) [0|15] "" Vector__XXX
 SG_ SuspendDuration : 32|16@1+ (1,0) [0|64255] "seconds" Vector__XXX

BO_ 2566837502 DM12: 22 Vector__XXX
 SG_ SPN5 : 144|16@1+ (1,0) [0|65536] "" Vector__XXX
 SG_ SPN4 : 112|16@1+ (1,0) [0|65536] "" Vector__XXX
 SG_ SPN3 : 80|16@1+ (1,0) [0|65536] "" Vector__XXX
 SG_ SPN2 : 48|16@1+ (1,0) [0|65536] "" Vector__XXX
 SG_ FlashRedStopLamp : 12|2@1+ (1,0) [0|3] "" Vector__XXX
 SG_ FlashProtectLamp : 8|2@1+ (1,0) [0|3] "" Vector__XXX
 SG_ FailureModeIdentifier5 : 160|5@1+ (1,0) [0|0] "" Vector__XXX
 SG_ FailureModeIdentifier4 : 128|5@1+ (1,0) [0|0] "" Vector__XXX
 SG_ FailureModeIdentifier3 : 96|5@1+ (1,0) [0|0] "" Vector__XXX
 SG_ OccurenceCount1 : 40|7@1+ (1,0) [0|126] "" Vector__XXX
 SG_ SPNConversionMethod1 : 47|1@1+ (1,0) [0|1] "" Vector__XXX
 SG_ FailureModeIdentifier1 : 32|5@1+ (1,0) [0|0] "" Vector__XXX
 SG_ SPN1 : 16|16@1+ (1,0) [0|65536] "" Vector__XXX
 SG_ MalfunctionIndicatorLampStatus : 6|2@1+ (1,0) [0|3] "" Vector__XXX
 SG_ RedStopLampState : 4|2@1+ (1,0) [0|3] "" Vector__XXX
 SG_ AmberWarningLampStatus : 2|2@1+ (1,0) [0|3] "" Vector__XXX
 SG_ ProtectLampStatus : 0|2@1+ (1,0) [0|3] "" Vector__XXX
 SG_ FlashMalfuncIndicatorLamp : 14|2@1+ (1,0) [0|3] "" Vector__XXX
 SG_ FlashAmberWarningLamp : 10|2@1+ (1,0) [0|3] "" Vector__XXX
 SG_ FailureModeIdentifier2 : 64|5@1+ (1,0) [0|0] "" Vector__XXX
 SG_ SPNConversionMethod5 : 175|1@1+ (1,0) [0|1] "" Vector__XXX
 SG_ SPNConversionMethod4 : 143|1@1+ (1,0) [0|1] "" Vector__XXX
 SG_ SPNConversionMethod3 : 111|1@1+ (1,0) [0|1] "" Vector__XXX
 SG_ SPNConversionMethod2 : 79|1@1+ (1,0) [0|1] "" Vector__XXX
 SG_ OccurenceCount5 : 168|7@1+ (1,0) [0|126] "" Vector__XXX
 SG_ OccurenceCount4 : 136|7@1+ (1,0) [0|126] "" Vector__XXX
 SG_ OccurenceCount3 : 104|7@1+ (1,0) [0|126] "" Vector__XXX
 SG_ OccurenceCount2 : 72|7@1+ (1,0) [0|126] "" Vector__XXX
 SG_ SPN5High : 165|3@1+ (1,0) [0|7] "" Vector__XXX
 SG_ SPN4High : 133|3@1+ (1,0) [0|7] "" Vector__XXX
 SG_ SPN3High : 101|3@1+ (1,0) [0|7] "" Vector__XXX
 SG_ SPN2High : 69|3@1+ (1,0) [0|7] "" Vector__XXX
 SG_ SPN1High : 37|3@1+ (1,0) [0|7] "" Vector__XXX

BO_ 2566837246 DM11: 0 Vector__XXX

BO_ 2566836990 DM10: 8 Vector__XXX
 SG_ TestIdentifierSupported : 0|64@1+ (1,0) [1|1.8446744074E+019] "" Vector__XXX

BO_ 2566834942 DM1: 22 Vector__XXX
 SG_ SPN5 : 144|16@1+ (1,0) [0|65536] "" Vector__XXX
 SG_ SPN4 : 112|16@1+ (1,0) [0|65536] "" Vector__XXX
 SG_ SPN3 : 80|16@1+ (1,0) [0|65536] "" Vector__XXX
 SG_ SPN2 : 48|16@1+ (1,0) [0|65536] "" Vector__XXX
 SG_ FailureModeIdentifier5 : 160|5@1+ (1,0) [0|0] "" Vector__XXX
 SG_ FailureModeIdentifier4 : 128|5@1+ (1,0) [0|0] "" Vector__XXX
 SG_ FailureModeIdentifier3 : 96|5@1+ (1,0) [0|0] "" Vector__XXX
 SG_ FlashRedStopLamp : 12|2@1+ (1,0) [0|3] "" Vector__XXX
 SG_ FlashProtectLamp : 8|2@1+ (1,0) [0|3] "" Vector__XXX
 SG_ FlashMalfuncIndicatorLamp : 14|2@1+ (1,0) [0|3] "" Vector__XXX
 SG_ FlashAmberWarningLamp : 10|2@1+ (1,0) [0|3] "" Vector__XXX
 SG_ MalfunctionIndicatorLampStatus : 6|2@1+ (1,0) [0|3] "" Vector__XXX
 SG_ AmberWarningLampStatus : 2|2@1+ (1,0) [0|3] "" Vector__XXX
 SG_ OccurenceCount1 : 40|7@1+ (1,0) [0|126] "" Vector__XXX
 SG_ SPNConversionMethod1 : 47|1@1+ (1,0) [0|1] "" Vector__XXX
 SG_ FailureModeIdentifier1 : 32|5@1+ (1,0) [0|0] "" Vector__XXX
 SG_ SPN1 : 16|16@1+ (1,0) [0|65536] "" Vector__XXX
 SG_ RedStopLampState : 4|2@1+ (1,0) [0|3] "" Vector__XXX
 SG_ ProtectLampStatus : 0|2@1+ (1,0) [0|3] "" Vector__XXX
 SG_ FailureModeIdentifier2 : 64|5@1+ (1,0) [0|0] "" Vector__XXX
 SG_ SPNConversionMethod5 : 175|1@1+ (1,0) [0|1] "" Vector__XXX
 SG_ SPNConversionMethod4 : 143|1@1+ (1,0) [0|1] "" Vector__XXX
 SG_ SPNConversionMethod3 : 111|1@1+ (1,0) [0|1] "" Vector__XXX
 SG_ SPNConversionMethod2 : 79|1@1+ (1,0) [0|1] "" Vector__XXX
 SG_ OccurenceCount5 : 168|7@1+ (1,0) [0|126] "" Vector__XXX
 SG_ OccurenceCount4 : 136|7@1+ (1,0) [0|126] "" Vector__XXX
 SG_ OccurenceCount3 : 104|7@1+ (1,0) [0|126] "" Vector__XXX
 SG_ OccurenceCount2 : 72|7@1+ (1,0) [0|126] "" Vector__XXX
 SG_ SPN5High : 165|3@1+ (1,0) [0|7] "" Vector__XXX
 SG_ SPN4High : 133|3@1+ (1,0) [0|7] "" Vector__XXX
 SG_ SPN3High : 101|3@1+ (1,0) [0|7] "" Vector__XXX
 SG_ SPN2High : 69|3@1+ (1,0) [0|7] "" Vector__XXX
 SG_ SPN1High : 37|3@1+ (1,0) [0|7] "" Vector__XXX

BO_ 2566780926 UTACR: 8 Vector__XXX
 SG_ UtlityOverallPowerFactorLagging : 48|2@1+ (1,0) [0|3] "" Vector__XXX
 SG_ UtilityOverallPowerFactor : 32|16@1+ (1,-1) [-1|2.92181] "" Vector__XXX
 SG_ UtilityTotalReactivePower : 0|32@1+ (1,-2000000000) [-2000000000|2211081215] "VA" Vector__XXX

BO_ 2566781182 UTACP: 8 Vector__XXX
 SG_ UtilityTotalApparentPower : 32|32@1+ (1,-2000000000) [-2000000000|2211081215] "VA" Vector__XXX
 SG_ UtilityTotalRealPower : 0|32@1+ (1,-2000000000) [-2000000000|2211081215] "VA" Vector__XXX

BO_ 2566778366 UTACE: 8 Vector__XXX
 SG_ UtilityTotalKWHoursImport : 32|32@1+ (1,0) [0|4211081215] "kWh" Vector__XXX
 SG_ UtilityTotalKWHoursExport : 0|32@1+ (1,0) [0|4211081215] "kWh" Vector__XXX

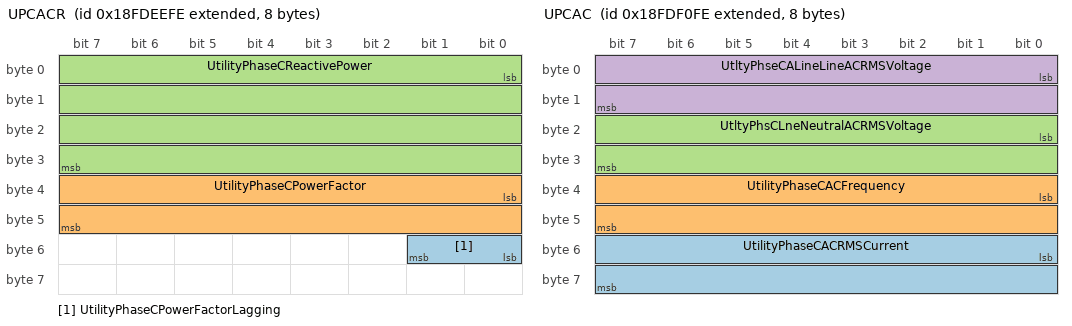
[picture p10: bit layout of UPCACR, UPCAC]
BO_ 2566778622 UPCACR: 8 Vector__XXX
 SG_ UtilityPhaseCPowerFactorLagging : 48|2@1+ (1,0) [0|3] "" Vector__XXX
 SG_ UtilityPhaseCPowerFactor : 32|16@1+ (1,-1) [-1|2.92181] "" Vector__XXX
 SG_ UtilityPhaseCReactivePower : 0|32@1+ (1,-2000000000) [-2000000000|2211081215] "VA" Vector__XXX

BO_ 2566778878 UPCACP: 8 Vector__XXX
 SG_ UtilityPhaseCApparentPower : 32|32@1+ (1,-2000000000) [-2000000000|2211081215] "VA" Vector__XXX
 SG_ UtilityPhaseCRealPower : 0|32@1+ (1,-2000000000) [-2000000000|2211081215] "VA" Vector__XXX

BO_ 2566779134 UPCAC: 8 Vector__XXX
 SG_ UtilityPhaseCACRMSCurrent : 48|16@1+ (1,0) [0|64255] "A" Vector__XXX
 SG_ UtilityPhaseCACFrequency : 32|16@1+ (1,0) [0|501.9921875] "Hz" Vector__XXX
 SG_ UtltyPhsCLneNeutralACRMSVoltage : 16|16@1+ (1,0) [0|64255] "V" Vector__XXX
 SG_ UtltyPhseCALineLineACRMSVoltage : 0|16@1+ (1,0) [0|64255] "V" Vector__XXX

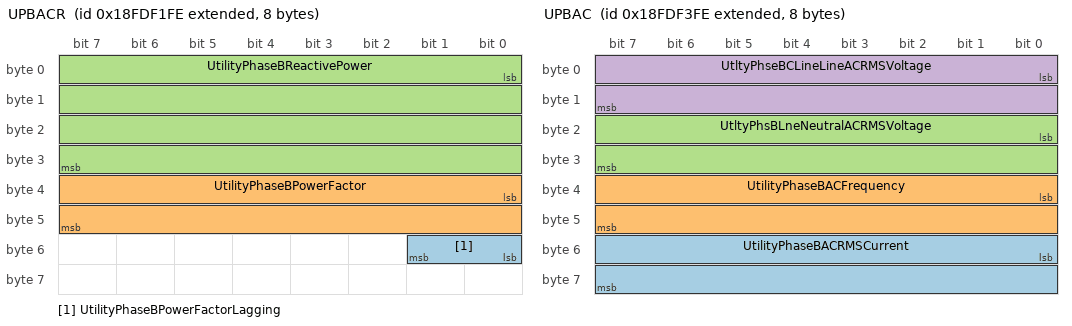
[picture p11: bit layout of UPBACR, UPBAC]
BO_ 2566779390 UPBACR: 8 Vector__XXX
 SG_ UtilityPhaseBPowerFactorLagging : 48|2@1+ (1,0) [0|3] "" Vector__XXX
 SG_ UtilityPhaseBPowerFactor : 32|16@1+ (1,-1) [-1|2.92181] "" Vector__XXX
 SG_ UtilityPhaseBReactivePower : 0|32@1+ (1,-2000000000) [-2000000000|2211081215] "VA" Vector__XXX

BO_ 2566779646 UPBACP: 8 Vector__XXX
 SG_ UtilityPhaseBApparentPower : 32|32@1+ (1,-2000000000) [-2000000000|2211081215] "VA" Vector__XXX
 SG_ UtilityPhaseBRealPower : 0|32@1+ (1,-2000000000) [-2000000000|2211081215] "VA" Vector__XXX

BO_ 2566779902 UPBAC: 8 Vector__XXX
 SG_ UtilityPhaseBACRMSCurrent : 48|16@1+ (1,0) [0|64255] "A" Vector__XXX
 SG_ UtilityPhaseBACFrequency : 32|16@1+ (1,0) [0|501.9921875] "Hz" Vector__XXX
 SG_ UtltyPhsBLneNeutralACRMSVoltage : 16|16@1+ (1,0) [0|64255] "V" Vector__XXX
 SG_ UtltyPhseBCLineLineACRMSVoltage : 0|16@1+ (1,0) [0|64255] "V" Vector__XXX

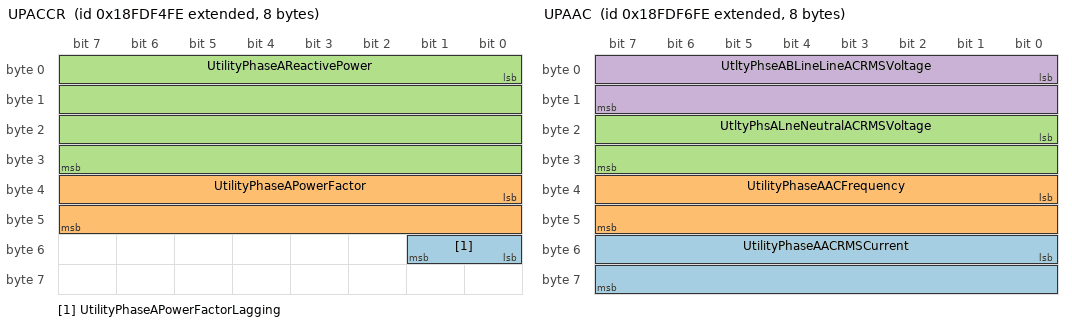
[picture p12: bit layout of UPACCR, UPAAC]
BO_ 2566780158 UPACCR: 8 Vector__XXX
 SG_ UtilityPhaseAPowerFactorLagging : 48|2@1+ (1,0) [0|3] "" Vector__XXX
 SG_ UtilityPhaseAPowerFactor : 32|16@1+ (1,-1) [-1|2.92181] "" Vector__XXX
 SG_ UtilityPhaseAReactivePower : 0|32@1+ (1,-2000000000) [-2000000000|2211081215] "VA" Vector__XXX

BO_ 2566780414 UPAACP: 8 Vector__XXX
 SG_ UtilityPhaseAApparentPower : 32|32@1+ (1,-2000000000) [-2000000000|2211081215] "VA" Vector__XXX
 SG_ UtilityPhaseARealPower : 0|32@1+ (1,-2000000000) [-2000000000|2211081215] "VA" Vector__XXX

BO_ 2566780670 UPAAC: 8 Vector__XXX
 SG_ UtilityPhaseAACRMSCurrent : 48|16@1+ (1,0) [0|64255] "A" Vector__XXX
 SG_ UtilityPhaseAACFrequency : 32|16@1+ (1,0) [0|501.9921875] "Hz" Vector__XXX
 SG_ UtltyPhsALneNeutralACRMSVoltage : 16|16@1+ (1,0) [0|64255] "V" Vector__XXX
 SG_ UtltyPhseABLineLineACRMSVoltage : 0|16@1+ (1,0) [0|64255] "V" Vector__XXX

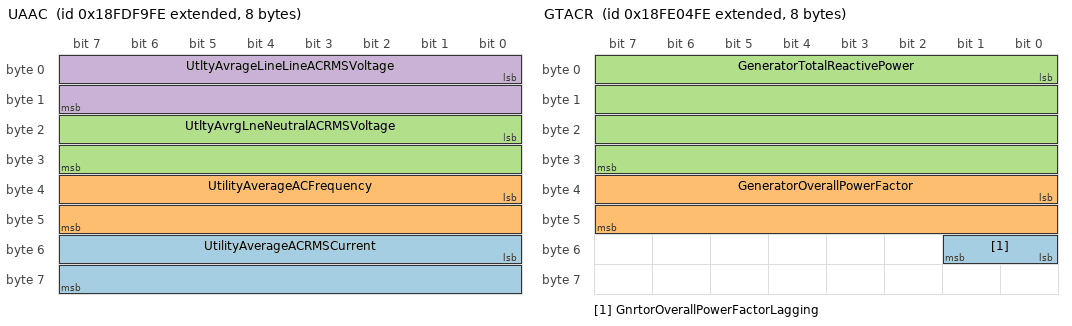
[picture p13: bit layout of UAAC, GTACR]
BO_ 2566781438 UAAC: 8 Vector__XXX
 SG_ UtilityAverageACRMSCurrent : 48|16@1+ (1,0) [0|64255] "A" Vector__XXX
 SG_ UtilityAverageACFrequency : 32|16@1+ (1,0) [0|501.9921875] "Hz" Vector__XXX
 SG_ UtltyAvrgLneNeutralACRMSVoltage : 16|16@1+ (1,0) [0|64255] "V" Vector__XXX
 SG_ UtltyAvrageLineLineACRMSVoltage : 0|16@1+ (1,0) [0|64255] "V" Vector__XXX

BO_ 2566784254 GTACR: 8 Vector__XXX
 SG_ GnrtorOverallPowerFactorLagging : 48|2@1+ (1,0) [0|3] "" Vector__XXX
 SG_ GeneratorOverallPowerFactor : 32|16@1+ (1,-1) [-1|2.92181] "" Vector__XXX
 SG_ GeneratorTotalReactivePower : 0|32@1+ (1,-2000000000) [-2000000000|2211081215] "VA" Vector__XXX

BO_ 2566784510 GTACP: 8 Vector__XXX
 SG_ GeneratorTotalApparentPower : 32|32@1+ (1,-2000000000) [-2000000000|2211081215] "VA" Vector__XXX
 SG_ GeneratorTotalRealPower : 0|32@1+ (1,-2000000000) [-2000000000|2211081215] "VA" Vector__XXX

CM_ BO_ 2563833598 "Cab Illumination Message";
CM_ BO_ 2566843390 "Component Identification";
CM_ BO_ 2566844926 "Cruise Control/Vehicle Speed";
CM_ SG_ 2566844926 EngShutdownOverrideSwitch "Switch signal which indicates the position of the engine shutdown override switch.";
CM_ SG_ 2566844926 EngTestModeSwitch "Switch signal which indicates the position of the engine test mode switch.";
CM_ SG_ 2566844926 EngIdleDecrementSwitch "Switch signal which indicates the position of the idle decrement switch.";
CM_ SG_ 2566844926 EngIdleIncrementSwitch "Switch signal which indicates the position of the idle increment switch.";
CM_ SG_ 2566844926 CruiseCtrlStates "This parameter is used to indicate the current state, or mode, of operation by the cruise control device.";
CM_ SG_ 2566844926 PTOState "This parameter is used to indicate the current state or mode of operation by the power takeoff (PTO) device.";
CM_ SG_ 2566844926 CruiseCtrlSetSpeed "Value of set (chosen) velocity of velocity control system.";
CM_ SG_ 2566844926 CruiseCtrlAccelerateSwitch "Switch signal of the cruise control activator which indicates that the activator is in the position �accelerate.";
CM_ SG_ 2566844926 CruiseCtrlResumeSwitch "Switch signal of the cruise control activator which indicates that the activator is in the position �resume.";
CM_ SG_ 2566844926 CruiseCtrlCoastSwitch "Switch signal of the cruise control activator which indicates that the activator is in the position �coast (decelerate).";
CM_ SG_ 2566844926 CruiseCtrlSetSwitch "Switch signal of the cruise control activator which indicates that the activator is in the position �set.";
CM_ SG_ 2566844926 ClutchSwitch "Switch signal which indicates that the clutch pedal is being pressed.";
CM_ SG_ 2566844926 BrakeSwitch "Switch signal which indicates that the driver operated brake foot pedal is being pressed.";
CM_ SG_ 2566844926 CruiseCtrlEnableSwitch "Switch signal which indicates that it is possible to manage the cruise control function.";
CM_ SG_ 2566844926 CruiseCtrlActive "Cruise control is switched on.";
CM_ SG_ 2566844926 WheelBasedVehicleSpeed "Speed of the vehicle as calculated from wheel or tailshaft speed.";
CM_ SG_ 2566844926 CruiseCtrlPauseSwitch "Switch signal which indicates the position of the Cruise Control Pause Switch used on Remote Cruise Control applications.";
CM_ SG_ 2566844926 ParkingBrakeSwitch "Switch signal which indicates when the parking brake is set.";
CM_ SG_ 2566844926 TwoSpeedAxleSwitch "Switch signal which indicates the current axle range.";
CM_ BO_ 2566843902 "Cruise Control/Vehicle Speed Setup";
CM_ SG_ 2566843902 CruiseCtrlHighSetLimitSpeed "Maximum vehicle velocity at which cruise can be set.";
CM_ SG_ 2566843902 MaxVehicleSpeedLimit "Maximum vehicle velocity allowed.";
CM_ BO_ 2566809598 "Climate Control Configuration";
CM_ SG_ 2566809598 AuxHeaterMaxOutputPower "The maximum output power of the auxiliary heater.";
CM_ BO_ 2633940222 "Compression/Service Brake Information";
CM_ SG_ 2633940222 TripServiceBrakeApps "Total number of times the service brakes have been activated since the last trip reset.";
CM_ SG_ 2633940222 TripServiceBrakeDistance "Total distance over which the service brakes have been active since the last trip reset.";
CM_ SG_ 2633940222 TripCompressionBrakeDistance "Total distance over which the compression brakes have been active since the last trip reset.";
CM_ SG_ 2633940222 TotalCompressionBrakeDistance "Total distance over which the compression brakes have been active for the life of the engine.";
CM_ BO_ 2566775294 "Cab A/C Climate System Information";
CM_ SG_ 2566775294 CbA_CRfrgrntCmprssorOutletPress "This is the gage pressure at the compressor outlet in the cab air conditioning system.";
CM_ BO_ 2566803710 "Battery Temperature";
CM_ SG_ 2566803710 Battery2Temp "Temperature of the battery 2.";
CM_ SG_ 2566803710 Battery1Temp "Temperature of the battery 1.";
CM_ BO_ 2566809342 "Battery Main Switch Information";
CM_ SG_ 2566809342 BatteryMainSwitchHoldState "Parameter indicating whether the battery main switch is held due to an external request or not.";
CM_ BO_ 2365446910 "Basic Joystick Message 3";
CM_ SG_ 2365446910 Joystick3XAxisDetentPosStatus "Reports when the current joystick position is in the detent position for that axis of travel.";
CM_ SG_ 2365446910 Joystick3Button9PressedStatus "Reports when the joystick button has been pressed.";
CM_ SG_ 2365446910 Joystick3Button10PressedStatus "Reports when the joystick button has been pressed.";
CM_ SG_ 2365446910 Joystick3Button11PressedStatus "Reports when the joystick button has been pressed.";
CM_ SG_ 2365446910 Joystick3Button12PressedStatus "Reports when the joystick button has been pressed.";
CM_ SG_ 2365446910 Joystick3YAxisDetentPosStatus "Reports when the current joystick position is in the detent position for that axis of travel.";
CM_ SG_ 2365446910 Joystick3YAxisPos "The position of the joystick in the relative motion of travel from the neutral position.";
CM_ SG_ 2365446910 Joystick3YAxisNeutralPosStatus "Reports when the current joystick position is in the neutral position for that axis of travel.";
CM_ SG_ 2365446910 Joystick3XAxisPos "The position of the joystick in the relative motion of travel from the neutral position.";
CM_ SG_ 2365446910 Joystick3XAxisNeutralPosStatus "Reports when the current joystick position is in the neutral position for that axis of travel.";
CM_ SG_ 2365446910 Joystick3Button5PressedStatus "Reports when the joystick button has been pressed.";
CM_ SG_ 2365446910 Joystick3Button6PressedStatus "Reports when the joystick button has been pressed.";
CM_ SG_ 2365446910 Joystick3Button7PressedStatus "Reports when the joystick button has been pressed.";
CM_ SG_ 2365446910 Joystick3Button8PressedStatus "Reports when the joystick button has been pressed.";
CM_ SG_ 2365446910 Joystick3Button1PressedStatus "Reports when the joystick button has been pressed.";
CM_ SG_ 2365446910 Joystick3Button2PressedStatus "Reports when the joystick button has been pressed.";
CM_ SG_ 2365446910 Joystick3Button3PressedStatus "Reports when the joystick button has been pressed.";
CM_ SG_ 2365446910 Joystick3Button4PressedStatus "Reports when the joystick button has been pressed.";
CM_ BO_ 2365446398 "Basic Joystick Message 2";
CM_ SG_ 2365446398 Joystick2XAxisDetentPosStatus "Reports when the current joystick position is in the detent position for that axis of travel.";
CM_ SG_ 2365446398 Joystick2YAxisDetentPosStatus "Reports when the current joystick position is in the detent position for that axis of travel.";
CM_ SG_ 2365446398 Joystick2YAxisPos "The position of the joystick in the relative motion of travel from the neutral position.";
CM_ SG_ 2365446398 Joystick2YAxisNeutralPosStatus "Reports when the current joystick position is in the neutral position for that axis of travel.";
CM_ SG_ 2365446398 Joystick2XAxisPos "The position of the joystick in the relative motion of travel from the neutral position.";
CM_ SG_ 2365446398 Joystick2XAxisNeutralPosStatus "Reports when the current joystick position is in the neutral position for that axis of travel.";
CM_ SG_ 2365446398 Joystick2Button9PressedStatus "Reports when the joystick button has been pressed.";
CM_ SG_ 2365446398 Joystick2Button10PressedStatus "Reports when the joystick button has been pressed.";
CM_ SG_ 2365446398 Joystick2Button11PressedStatus "Reports when the joystick button has been pressed.";
CM_ SG_ 2365446398 Joystick2Button12PressedStatus "Reports when the joystick button has been pressed.";
CM_ SG_ 2365446398 Joystick2Button5PressedStatus "Reports when the joystick button has been pressed.";
CM_ SG_ 2365446398 Joystick2Button6PressedStatus "Reports when the joystick button has been pressed.";
CM_ SG_ 2365446398 Joystick2Button7PressedStatus "Reports when the joystick button has been pressed.";
CM_ SG_ 2365446398 Joystick2Button8PressedStatus "Reports when the joystick button has been pressed.";
CM_ SG_ 2365446398 Joystick2Button1PressedStatus "Reports when the joystick button has been pressed.";
CM_ SG_ 2365446398 Joystick2Button2PressedStatus "Reports when the joystick button has been pressed.";
CM_ SG_ 2365446398 Joystick2Button3PressedStatus "Reports when the joystick button has been pressed.";
CM_ SG_ 2365446398 Joystick2Button4PressedStatus "Reports when the joystick button has been pressed.";
CM_ BO_ 2365445886 "Basic Joystick Message 1";
CM_ SG_ 2365445886 Joystick1XAxisDetentPosStatus "Reports when the current joystick position is in the detent position for that axis of travel.";
CM_ SG_ 2365445886 Joystick1YAxisDetentPosStatus "Reports when the current joystick position is in the detent position for that axis of travel.";
CM_ SG_ 2365445886 Joystick1YAxisPos "The position of the joystick in the relative motion of travel from the neutral position.";
CM_ SG_ 2365445886 Joystick1YAxisNeutralPosStatus "Reports when the current joystick position is in the neutral position for that axis of travel.";
CM_ SG_ 2365445886 Joystick1XAxisPos "The position of the joystick in the relative motion of travel from the neutral position.";
CM_ SG_ 2365445886 Joystick1Button9PressedStatus "Reports when the joystick button has been pressed.";
CM_ SG_ 2365445886 Joystick1Button10PressedStatus "Reports when the joystick button has been pressed.";
CM_ SG_ 2365445886 Joystick1Button11PressedStatus "Reports when the joystick button has been pressed.";
CM_ SG_ 2365445886 Joystick1Button12PressedStatus "Reports when the joystick button has been pressed.";
CM_ SG_ 2365445886 Joystick1Button5PressedStatus "Reports when the joystick button has been pressed.";
CM_ SG_ 2365445886 Joystick1Button6PressedStatus "Reports when the joystick button has been pressed.";
CM_ SG_ 2365445886 Joystick1Button7PressedStatus "Reports when the joystick button has been pressed.";
CM_ SG_ 2365445886 Joystick1Button8PressedStatus "Reports when the joystick button has been pressed.";
CM_ SG_ 2365445886 Joystick1Button1PressedStatus "Reports when the joystick button has been pressed.";
CM_ SG_ 2365445886 Joystick1Button2PressedStatus "Reports when the joystick button has been pressed.";
CM_ SG_ 2365445886 Joystick1Button3PressedStatus "Reports when the joystick button has been pressed.";
CM_ SG_ 2365445886 Joystick1Button4PressedStatus "Reports when the joystick button has been pressed.";
CM_ SG_ 2365445886 Joystick1XAxisNeutralPosStatus "Reports when the current joystick position is in the neutral position for that axis of travel.";
CM_ BO_ 2566847230 "Brakes";
CM_ SG_ 2566847230 ParkingBrakeRedWarningSignal "This parameter commands the Parking Brake red optical warning signal.";
CM_ SG_ 2566847230 ParkBrakeReleaseInhibitStatus "This parameter provides reports on the status of the Park Brake Release Inhibit function.";
CM_ SG_ 2566847230 ParkingBrakeActuator "Signal which indicates the current state of the actuator(s) that control the parking brake (see also SPN 70).";
CM_ SG_ 2566847230 BrakeSecondPress "Gage pressure of air in the secondary, or service side, of the air brake system.";
CM_ SG_ 2566847230 BrakePrimaryPress "Gage pressure of air in the primary, or supply side, of the air brake system.";
CM_ BO_ 2566848254 "Auxiliary Water Pump Pressure";
CM_ SG_ 2566848254 AuxPumpPress "Gage pressure of auxiliary water pump driven as a PTO device.";
CM_ BO_ 2631728894 "Anti-theft Status";
CM_ SG_ 2631728894 AntitheftRandomNumber "A seven byte random numeric code provided by the component in response to an anti-theft request.";
CM_ SG_ 2631728894 AntitheftComponentStatusStates "Indicates whether or not the component can be started.";
CM_ SG_ 2631728894 AntthftEncryptnSdPrsntIndicator "Indicates the presence of the encryption seed random number.";
CM_ SG_ 2631728894 AntitheftPwdValidIndicator "Indicates the presence of a validated password.";
CM_ BO_ 2631794430 "Anti-theft Request";
CM_ SG_ 2631794430 AntitheftPasswordRepresentation "This parameter is the seven byte numeric code (i.";
CM_ SG_ 2631794430 AntitheftCmdStates "This parameter is used to identify the specific requests being sent to the component.";
CM_ BO_ 2633934846 "Alternator Temperature";
CM_ SG_ 2633934846 EngAltWinding3Temp "Temperature of the windings inside the alternator.";
CM_ SG_ 2633934846 EngAltWinding2Temp "Temperature of the windings inside the alternator.";
CM_ SG_ 2633934846 EngAltWinding1Temp "Temperature of the windings inside the alternator.";
CM_ SG_ 2633934846 EngAltBearing2Temp "Temperature of the bearing inside the alternator.";
CM_ SG_ 2633934846 EngAltBearing1Temp "Temperature of the bearing inside the alternator.";
CM_ BO_ 2362572542 "Air Suspension Control 6";
CM_ SG_ 2362572542 LevelPresetRearAxleRight "Set value for nominal level 'preset level' at the right side of the rear axle.";
CM_ SG_ 2362572542 LevelPresetRearAxleLeft "Set value for nominal level 'preset level' at the left side of the rear axle.";
CM_ SG_ 2362572542 LevelPresetFrontAxleRight "Set value for nominal level 'preset level' at the right side of the front axle.";
CM_ SG_ 2362572542 LevelPresetFrontAxleLeft "Set value for nominal level 'preset level' at the left side of the front axle.";
CM_ BO_ 2365478910 "Air Suspension Control 5";
CM_ SG_ 2365478910 ElctrncShckAbsrbrCtrlMdLft_TgAxl "Signal which indicates the current mode of operation of the electronic shock absorber control at the lift/tag axle.";
CM_ SG_ 2365478910 ElctrncShckAbsrbrCtrlMdRearAxle "Signal which indicates the current mode of operation of the electronic shock absorber control at the rear axle.";
CM_ SG_ 2365478910 ElctrncShckAbsrbrCtrlMdFrntAxle "Signal which indicates the current mode of operation of the electronic shock absorber control at the front axle.";
CM_ BO_ 2566805758 "Air Suspension Control 4";
CM_ BO_ 2566806014 "Air Suspension Control 3";
CM_ SG_ 2566806014 RelativeLevelRearAxleRight "Information of the height at the left side of the rear axle referred to normal level 1.";
CM_ SG_ 2566806014 RelativeLevelRearAxleLeft "Information of the height at the left side of the rear axle referred to normal level 1.";
CM_ SG_ 2566806014 RelativeLevelFrontAxleRight "Information of the height at the right side of the front axle referred to normal level 1.";
CM_ SG_ 2566806014 RelativeLevelFrontAxleLeft "Information of the height at the left side of the front axle referred to normal level 1.";
CM_ BO_ 2362638078 "Air Suspension Control 2";
CM_ SG_ 2362638078 ProhibitAirSuspensionCtrl "This parameter contains an external request to prohibit all air suspension control.";
CM_ SG_ 2362638078 KneelingCmdRearAxle "Command signal to activate the kneeling functionality at the rear axle of the vehicle.";
CM_ SG_ 2362638078 DamperStiffnessRqRearAxle "Demand value for the shock absorber control at the rear axle.";
CM_ SG_ 2362638078 DamperStiffnessRqFrontAxle "Demand value for the shock absorber control at the front axle.";
CM_ SG_ 2362638078 NominalLevelRqRearAxle "Command signal to activate a level of the rear axle programmed and/or memorised in the ECU.";
CM_ SG_ 2362638078 LiftAxle2PosCmd "Signal to command the position / load condition of lift / tag axle #2.";
CM_ SG_ 2362638078 LiftAxle1PosCmd "Signal to command the position/load condition of lift/tag axle #1.";
CM_ BO_ 2365479678 "Air Suspension Control 1";
CM_ SG_ 2365479678 SspensionCtrlRefusalInformation "Signal which indicates that the air suspension control cannot perform a request due to the operating conditions.";
CM_ SG_ 2365479678 SuspensionRemoteCtrl2 "Signal which indicates that the suspension system is controlled by remote control #2.";
CM_ SG_ 2365479678 SuspensionRemoteCtrl1 "Signal which indicates that the suspension system is controlled by remote control #1.";
CM_ SG_ 2365479678 RearAxleInBumperRange "Signal which indicates that the vehicle height at the rear axle (SPNs 1723 and 1724) is within the bumper range.";
CM_ SG_ 2365479678 FrontAxleInBumperRange "Signal which indicates that the vehicle height at the front axle (SPNs 1721 and 1722) is within the bumper range.";
CM_ SG_ 2365479678 DoorRelease "Signal which indicates that the doors may be opened.";
CM_ SG_ 2365479678 VehicleMotionInhibit "Signal which indicates whether vehicle motion is inhibited.";
CM_ SG_ 2365479678 SecurityDevice "The signal which indicates the status of the security device.";
CM_ SG_ 2365479678 AboveNominalLevelRearAxle "Signal which indicates whether the actual height of the rear axle is above the nominal (desired) level of the rear axle.";
CM_ SG_ 2365479678 AboveNominalLevelFrontAxle "Signal which indicates whether the actual height of the front axle is above the nominal (desired) level of the front axle.";
CM_ SG_ 2365479678 BelowNominalLevelRearAxle "Signal which indicates whether the actual height of the rear axle is below the nominal (desired) level for the rear axle.";
CM_ SG_ 2365479678 BelowNominalLevelFrontAxle "Signal which indicates whether the actual height of the front axle is below the nominal (desired) level for the front axle.";
CM_ SG_ 2365479678 NominalLevelRearAxle "Signal which indicates the nominal (desired) height of the rear axle to be controlled by the suspension system.";
CM_ SG_ 2365479678 NominalLevelFrontAxle "Signal which indicates the nominal (desired) height of the front axle to be controlled by the suspension system.";
CM_ SG_ 2365479678 LiftAxle2Pos "Signal which indicates the position / load condition of lift axle / tag axle #2.";
CM_ SG_ 2365479678 LiftAxle1Pos "Signal which indicates the position / load condition of lift axle / tag axle #1.";
CM_ BO_ 2566837758 "Alternator Information";
CM_ SG_ 2566837758 Alt4Status "Alternator 4 operating status.";
CM_ SG_ 2566837758 Alt3Status "Alternator 3 operating status.";
CM_ SG_ 2566837758 Alt2Status "Alternator 2 operating status.";
CM_ SG_ 2566837758 Alt1Status "Alternator 1 operating status.";
CM_ SG_ 2566837758 AltSpeed "Actual rotation speed of the alternator.";
CM_ BO_ 2633922558 "Auxiliary Pressures";
CM_ SG_ 2633922558 AuxAbsPressReading "Identifies the current absolute pressure (relative to 0 pressure) that is configured uniquely per application.";
CM_ SG_ 2633922558 AuxGagePressReading1 "Identifies the current gage pressure (relative to atmosphere) that is configured uniquely per application.";
CM_ SG_ 2633922558 AuxVacuumPressReading "Identifies the current vacuum pressure (relative to atmosphere) that is configured uniquely per application.";
CM_ BO_ 2566775038 "Ambient Conditions 2";
CM_ SG_ 2566775038 SolarSensorMax "This is the maximum value which can be reported by the sensor for the solar intensity.";
CM_ SG_ 2566775038 SolarIntensityPercent "This is the solar radiation (power density) falling on the vehicle in percent of the maximum sensor value (SPN 2611).";
CM_ BO_ 2633895166 "Working Set Member";
CM_ SG_ 2633895166 IndustryGroup "0 = Global; 
   1  = On-Highway; 
   2  = Agricultural and Forestry; 
   3  = Construction; 
   4  = Marine;
   5  = Industrial - Process
          Control - Stationary (Gen-Sets)
   6  = Reserve for SAE
   7  = Reserve for SAE";
CM_ SG_ 2633895166 ManufacturerCode "Assigned by NMEA 2000 Committee";
CM_ BO_ 2566836478 "Test results for non-continously monitored systems.";
CM_ SG_ 2566836478 TestLimitMinimum "The threshold which the test value must be above to pass the test.";
CM_ SG_ 2566836478 TestLimitMaximum "The threshold which the test value must be below to pass the test.";
CM_ SG_ 2566836478 TestValue "The test value collected during the test.";
CM_ SG_ 2566836478 TestType "Identifies the non-continously monitored component identifier that was tested.";
CM_ SG_ 2566836478 TestIdentifier "Designates the test to be run.";
CM_ BO_ 2565078782 "Command non-continously monitored test";
CM_ SG_ 2565078782 TestIdentifier "Designates the test to be run.";
CM_ BO_ 2566836222 "Pending DTCs";
CM_ SG_ 2566836222 SPN5 "SPN #5 (Conversion Version 4)";
CM_ SG_ 2566836222 SPN4 "SPN #4 (Conversion Version 4)";
CM_ SG_ 2566836222 SPN3 "SPN #3 (Conversion Version 4)";
CM_ SG_ 2566836222 SPN2 "SPN #2 (Conversion Version 4)";
CM_ SG_ 2566836222 FailureModeIdentifier5 "The FMI defines the type of failure detected in the subsystem identified by an SPN.";
CM_ SG_ 2566836222 FailureModeIdentifier4 "The FMI defines the type of failure detected in the subsystem identified by an SPN.";
CM_ SG_ 2566836222 FlashRedStopLamp "This parameter provides the capability to flash the RSL (SPN 3039).";
CM_ SG_ 2566836222 FlashProtectLamp "This parameter provides the capability to flash the engine protect lamp (SPN 3041).";
CM_ SG_ 2566836222 FlashMalfuncIndicatorLamp "This parameter provides the capability to flash the MIL (SPN 3038).";
CM_ SG_ 2566836222 FlashAmberWarningLamp "This parameter provides the capability to flash the AWL (SPN 3040). ";
CM_ SG_ 2566836222 FailureModeIdentifier3 "The FMI defines the type of failure detected in the subsystem identified by an SPN.";
CM_ SG_ 2566836222 FailureModeIdentifier2 "The FMI defines the type of failure detected in the subsystem identified by an SPN.";
CM_ SG_ 2566836222 OccurenceCount5 "The 7 bit occurence count field contains the number of times a fault has gone from active to previously active.";
CM_ SG_ 2566836222 OccurenceCount4 "The 7 bit occurence count field contains the number of times a fault has gone from active to previously active.";
CM_ SG_ 2566836222 OccurenceCount3 "The 7 bit occurence count field contains the number of times a fault has gone from active to previously active.";
CM_ SG_ 2566836222 OccurenceCount2 "The 7 bit occurence count field contains the number of times a fault has gone from active to previously active.";
CM_ SG_ 2566836222 OccurenceCount1 "The 7 bit occurence count field contains the number of times a fault has gone from active to previously active.";
CM_ SG_ 2566836222 FailureModeIdentifier1 "The FMI defines the type of failure detected in the subsystem identified by an SPN.";
CM_ SG_ 2566836222 SPN1 "SPN #1 (Conversion Version 4)";
CM_ SG_ 2566836222 MalfunctionIndicatorLampStatus "A lamp used to relay only emissions-related trouble code information.";
CM_ SG_ 2566836222 RedStopLampState "This lamp is uesed to relay trouble code information that is of a severe enought condition that it warrants stopping the vehicle.";
CM_ SG_ 2566836222 AmberWarningLampStatus "This lamp is used to relay trouble code information that is reporting a problem with the vehicle system but the vehicle need
not be immediately stopped.";
CM_ SG_ 2566836222 ProtectLampStatus "This lamp is used to relay trouble code informatio that is reporting a problem with a vehicle system that is most
probably not electronic subsystem related.";
CM_ SG_ 2566836222 SPN5High "SPN #5 (Conversion Version 4)";
CM_ SG_ 2566836222 SPN4High "SPN #4 (Conversion Version 4)";
CM_ SG_ 2566836222 SPN3High "SPN #3 (Conversion Version 4)";
CM_ SG_ 2566836222 SPN2High "SPN #2 (Conversion Version 4)";
CM_ SG_ 2566836222 SPN1High "SPN #1 (Conversion Version 4)";
CM_ BO_ 2566835966 "Diagnostic readiness 1";
CM_ SG_ 2566835966 OBDCompliance "Identifies the OBD compliance capabilityof the responding controller.";
CM_ SG_ 2566835966 PreviouslyActiveTroubleCodes "Identifies the number of previously active trouble codes that are present in a specific controller.";
CM_ SG_ 2566835966 ActiveTroubleCodes "Identifies the number of active trouble codes that are present in a specific controller.";
CM_ BO_ 2566835710 "Freeze frame parameters";
CM_ SG_ 2566835710 OccurenceCount1 "The 7 bit occurence count field contains the number of times a fault has gone from active to previously active.";
CM_ SG_ 2566835710 FailureModeIdentifier1 "The FMI defines the type of failure detected in the subsystem identified by an SPN.";
CM_ SG_ 2566835710 SPN1 "SPN #1 (Conversion Version 4)";
CM_ SG_ 2566835710 FreezeFrameLength "The freeze frame length shall be equal to the number of bytes in the required parameters plus the number of bytes in the
manufacturer specific parameters.";
CM_ SG_ 2566835710 EngSpeed "Actual engine speed which is calculated over a minimum crankshaft angle of 720 degrees divided by the number of cylinders.";
CM_ SG_ 2566835710 EngTorqueMode "State signal which indicates which engine torque mode is currently generating, limiting, or controlling the torque.";
CM_ SG_ 2566835710 EngTurboBoostPress "Gage pressure of air measured downstream on the compressor discharge side of the turbocharger.";
CM_ SG_ 2566835710 WheelBasedVehicleSpeed "Speed of the vehicle as calculated from wheel or tailshaft speed.";
CM_ SG_ 2566835710 SPN1High "SPN #1 (Conversion Version 4)";
CM_ BO_ 2566835454 "Diagnostic data clear/reset of previously active DTCs.";
CM_ BO_ 2566764542 "Expanded freeze frame.";
CM_ SG_ 2566764542 OccurenceCount1 "The 7 bit occurence count field contains the number of times a fault has gone from active to previously active.";
CM_ SG_ 2566764542 FailureModeIdentifier1 "The FMI defines the type of failure detected in the subsystem identified by an SPN.";
CM_ SG_ 2566764542 SPN1 "SPN #1 (Conversion Version 4)";
CM_ SG_ 2566764542 ExpandedFreezeFrameLength "The freeze frame length shall be equal to the number of bytes in the required parameters plus the number of bytes in the
manufacturer specific parameters.";
CM_ SG_ 2566764542 SPN1High "SPN #1 (Conversion Version 4)";
CM_ BO_ 2566764286 "SPN Support. This message is used to identify those SPNs supported by the product for freeze frames and data stream messages.";
CM_ SG_ 2566764286 SPNSupported1High "This parameter defines the SPN(s) that is/are supported for the freeze frame and/or data stream information.";
CM_ SG_ 2566764286 SPNSupportTypeSTR3 "This parameter defines whether the applicable parameter (that is the SPN) is supported in the freeze frame, the data stream or both the freeze frame and data stream.";
CM_ SG_ 2566764286 SPNSupportTypeSTR2 "This parameter defines whether the applicable parameter (that is the SPN) is supported in the freeze frame, the data stream or both the freeze frame and data stream.";
CM_ SG_ 2566764286 SPNSupportTypeEFF3 "This parameter defines whether the applicable parameter (that is the SPN) is supported in the freeze frame, the data stream or both the freeze frame and data stream.";
CM_ SG_ 2566764286 SPNSupportTypeEFF2 "This parameter defines whether the applicable parameter (that is the SPN) is supported in the freeze frame, the data stream or both the freeze frame and data stream.";
CM_ SG_ 2566764286 SPNSupportTypeDS3 "This parameter defines whether the applicable parameter (that is the SPN) is supported in the freeze frame, the data stream or both the freeze frame and data stream.";
CM_ SG_ 2566764286 SPNSupportTypeDS2 "This parameter defines whether the applicable parameter (that is the SPN) is supported in the freeze frame, the data stream or both the freeze frame and data stream.";
CM_ SG_ 2566764286 SPNSupported3High "This parameter defines the SPN(s) that is/are supported for the freeze frame and/or data stream information.";
CM_ SG_ 2566764286 SPNSupported2High "This parameter defines the SPN(s) that is/are supported for the freeze frame and/or data stream information.";
CM_ SG_ 2566764286 SPNSupported3 "This parameter defines the SPN(s) that is/are supported for the freeze frame and/or data stream information.";
CM_ SG_ 2566764286 SPNSupported2 "This parameter defines the SPN(s) that is/are supported for the freeze frame and/or data stream information.";
CM_ SG_ 2566764286 SPNDataLength3 "The number of data bytes associated with the SPN in the Freeze Frame.";
CM_ SG_ 2566764286 SPNSupportTypeSTR1 "This parameter defines whether the applicable parameter (that is the SPN) is supported in the freeze frame, the data stream or both the freeze frame and data stream.";
CM_ SG_ 2566764286 SPNSupportTypeDS1 "This parameter defines whether the applicable parameter (that is the SPN) is supported in the freeze frame, the data stream or both the freeze frame and data stream.";
CM_ SG_ 2566764286 SPNSupportTypeEFF1 "This parameter defines whether the applicable parameter (that is the SPN) is supported in the freeze frame, the data stream or both the freeze frame and data stream.";
CM_ SG_ 2566764286 SPNDataLength2 "The number of data bytes associated with the SPN in the Freeze Frame.";
CM_ SG_ 2566764286 SPNDataLength1 "The number of data bytes associated with the SPN in the Freeze Frame.";
CM_ SG_ 2566764286 SPNSupported1 "This parameter defines the SPN(s) that is/are supported for the freeze frame and/or data stream information.";
CM_ BO_ 2555576062 "Previously active emission related faults.";
CM_ SG_ 2555576062 FlashRedStopLamp "This parameter provides the capability to flash the RSL (SPN 3039).";
CM_ SG_ 2555576062 FlashProtectLamp "This parameter provides the capability to flash the engine protect lamp (SPN 3041).";
CM_ SG_ 2555576062 FlashMalfuncIndicatorLamp "This parameter provides the capability to flash the MIL (SPN 3038).";
CM_ SG_ 2555576062 SPN5 "SPN #5 (Conversion Version 4)";
CM_ SG_ 2555576062 SPN4 "SPN #4 (Conversion Version 4)";
CM_ SG_ 2555576062 SPN3 "SPN #3 (Conversion Version 4)";
CM_ SG_ 2555576062 SPN2 "SPN #2 (Conversion Version 4)";
CM_ SG_ 2555576062 FlashAmberWarningLamp "This parameter provides the capability to flash the AWL (SPN 3040). ";
CM_ SG_ 2555576062 FailureModeIdentifier5 "The FMI defines the type of failure detected in the subsystem identified by an SPN.";
CM_ SG_ 2555576062 FailureModeIdentifier4 "The FMI defines the type of failure detected in the subsystem identified by an SPN.";
CM_ SG_ 2555576062 OccurenceCount1 "The 7 bit occurence count field contains the number of times a fault has gone from active to previously active.";
CM_ SG_ 2555576062 FailureModeIdentifier1 "The FMI defines the type of failure detected in the subsystem identified by an SPN.";
CM_ SG_ 2555576062 SPN1 "SPN #1 (Conversion Version 4)";
CM_ SG_ 2555576062 MalfunctionIndicatorLampStatus "A lamp used to relay only emissions-related trouble code information.";
CM_ SG_ 2555576062 RedStopLampState "This lamp is uesed to relay trouble code information that is of a severe enought condition that it warrants stopping the vehicle.";
CM_ SG_ 2555576062 AmberWarningLampStatus "This lamp is used to relay trouble code information that is reporting a problem with the vehicle system but the vehicle need
not be immediately stopped.";
CM_ SG_ 2555576062 ProtectLampStatus "This lamp is used to relay trouble code informatio that is reporting a problem with a vehicle system that is most
probably not electronic subsystem related.";
CM_ SG_ 2555576062 FailureModeIdentifier3 "The FMI defines the type of failure detected in the subsystem identified by an SPN.";
CM_ SG_ 2555576062 FailureModeIdentifier2 "The FMI defines the type of failure detected in the subsystem identified by an SPN.";
CM_ SG_ 2555576062 OccurenceCount5 "The 7 bit occurence count field contains the number of times a fault has gone from active to previously active.";
CM_ SG_ 2555576062 OccurenceCount4 "The 7 bit occurence count field contains the number of times a fault has gone from active to previously active.";
CM_ SG_ 2555576062 OccurenceCount3 "The 7 bit occurence count field contains the number of times a fault has gone from active to previously active.";
CM_ SG_ 2555576062 OccurenceCount2 "The 7 bit occurence count field contains the number of times a fault has gone from active to previously active.";
CM_ SG_ 2555576062 SPN5High "SPN #5 (Conversion Version 4)";
CM_ SG_ 2555576062 SPN4High "SPN #4 (Conversion Version 4)";
CM_ SG_ 2555576062 SPN3High "SPN #3 (Conversion Version 4)";
CM_ SG_ 2555576062 SPN2High "SPN #2 (Conversion Version 4)";
CM_ SG_ 2555576062 SPN1High "SPN #1 (Conversion Version 4)";
CM_ BO_ 2562981630 "Individual Clear/Reset of active and previously active DTC.";
CM_ SG_ 2562981630 SPN1 "SPN #1 (Conversion Version 4)";
CM_ SG_ 2562981630 SPN1High "SPN #1 (Conversion Version 4)";
CM_ SG_ 2562981630 FailureModeIdentifier1 "The FMI defines the type of failure detected in the subsystem identified by an SPN.";
CM_ BO_ 2562850558 "Diagnostic readiness 2";
CM_ SG_ 2562850558 TimeSinceDTCsCleared "Time accumulated since DTCs were cleared (via an external test equipment or possibly, a battery disconnect) (SPN=?).";
CM_ SG_ 2562850558 MinutesRunByEngineMILActivated "Accumulated count (in minutes) while the MIL is activated (on) (SPN=?).";
CM_ SG_ 2562850558 DistanceSinceDTCsCleared "Distance accumulated since DTCs were cleared (SPN=?).";
CM_ SG_ 2562850558 DistanceWhileMILisActivated "The kilometers accumulated while the MIL is activated (SPN 3060).";
CM_ BO_ 2562916094 "Monitor Performance Ratio";
CM_ SG_ 2562916094 ApplSysMonitorDenominator "The number of times a vehicle has been operated that constitutes a driving cycle where this Applicable System Monitor could be operated per regulatory requirements (SPN 3068).";
CM_ SG_ 2562916094 ApplSysMonitorNumerator "The number of times a vehicle has been operated such that all conditions necessary for the Applicable System Monitor to detect a malfunction have been encountered (SPN 3067).";
CM_ SG_ 2562916094 SPNofApplSysMonitor "Contain the SPN of the system monitor for which Monitor ratio is being reported (SPN 3066).";
CM_ SG_ 2562916094 OBDMonitoringCondEncountered "Displays the number of times that the vehicle has been operated in the specified OBD monitoring conditions (SPN 3049).";
CM_ SG_ 2562916094 IgnitionCycleCounter "A single counter that defines the number of ignition cycles (SPN 3048).";
CM_ BO_ 2566835198 "Previously active diagnostic trouble codes";
CM_ SG_ 2566835198 SPN5 "SPN #5 (Conversion Version 4)";
CM_ SG_ 2566835198 SPN4 "SPN #4 (Conversion Version 4)";
CM_ SG_ 2566835198 SPN3 "SPN #3 (Conversion Version 4)";
CM_ SG_ 2566835198 SPN2 "SPN #2 (Conversion Version 4)";
CM_ SG_ 2566835198 FailureModeIdentifier5 "The FMI defines the type of failure detected in the subsystem identified by an SPN.";
CM_ SG_ 2566835198 FailureModeIdentifier4 "The FMI defines the type of failure detected in the subsystem identified by an SPN.";
CM_ SG_ 2566835198 OccurenceCount1 "The 7 bit occurence count field contains the number of times a fault has gone from active to previously active.";
CM_ SG_ 2566835198 FailureModeIdentifier1 "The FMI defines the type of failure detected in the subsystem identified by an SPN.";
CM_ SG_ 2566835198 SPN1 "SPN #1 (Conversion Version 4)";
CM_ SG_ 2566835198 MalfunctionIndicatorLampStatus "A lamp used to relay only emissions-related trouble code information.";
CM_ SG_ 2566835198 RedStopLampState "This lamp is uesed to relay trouble code information that is of a severe enought condition that it warrants stopping the vehicle.";
CM_ SG_ 2566835198 AmberWarningLampStatus "This lamp is used to relay trouble code information that is reporting a problem with the vehicle system but the vehicle need
not be immediately stopped.";
CM_ SG_ 2566835198 ProtectLampStatus "This lamp is used to relay trouble code informatio that is reporting a problem with a vehicle system that is most
probably not electronic subsystem related.";
CM_ SG_ 2566835198 FailureModeIdentifier3 "The FMI defines the type of failure detected in the subsystem identified by an SPN.";
CM_ SG_ 2566835198 FlashRedStopLamp "This parameter provides the capability to flash the RSL (SPN 3039).";
CM_ SG_ 2566835198 FlashProtectLamp "This parameter provides the capability to flash the engine protect lamp (SPN 3041).";
CM_ SG_ 2566835198 FlashMalfuncIndicatorLamp "This parameter provides the capability to flash the MIL (SPN 3038).";
CM_ SG_ 2566835198 FlashAmberWarningLamp "This parameter provides the capability to flash the AWL (SPN 3040). ";
CM_ SG_ 2566835198 FailureModeIdentifier2 "The FMI defines the type of failure detected in the subsystem identified by an SPN.";
CM_ SG_ 2566835198 OccurenceCount5 "The 7 bit occurence count field contains the number of times a fault has gone from active to previously active.";
CM_ SG_ 2566835198 OccurenceCount4 "The 7 bit occurence count field contains the number of times a fault has gone from active to previously active.";
CM_ SG_ 2566835198 OccurenceCount3 "The 7 bit occurence count field contains the number of times a fault has gone from active to previously active.";
CM_ SG_ 2566835198 OccurenceCount2 "The 7 bit occurence count field contains the number of times a fault has gone from active to previously active.";
CM_ SG_ 2566835198 SPN5High "SPN #5 (Conversion Version 4)";
CM_ SG_ 2566835198 SPN4High "SPN #4 (Conversion Version 4)";
CM_ SG_ 2566835198 SPN3High "SPN #3 (Conversion Version 4)";
CM_ SG_ 2566835198 SPN2High "SPN #2 (Conversion Version 4)";
CM_ SG_ 2566835198 SPN1High "SPN #1 (Conversion Version 4)";
CM_ BO_ 2564030206 "Calibration Information";
CM_ BO_ 2564226814 "Boot Load Data";
CM_ BO_ 2564292350 "Binary Data Transfer";
CM_ SG_ 2564292350 NumberOfOccurance "Number of occurance of raw binary data";
CM_ BO_ 2564357886 "Memory Access Response";
CM_ SG_ 2564357886 ErrorIndicator "Error Indicator/EDC Parameter";
CM_ BO_ 2564423422 "Memory Access Request";
CM_ SG_ 2564423422 KeyOrUserLevel "Key/User Level";
CM_ SG_ 2564423422 NumberRequested "Length/Number Requested";
CM_ SG_ 2564423422 NumberRequestedHigh "Length/Number Requested";
CM_ BO_ 2564816638 "Stop start broadcast";
CM_ SG_ 2564816638 HoldSignal "Indicator to all nodes that the communication ports that have been acted upon by the 'Stop start broadcast'
PGN are remaining in the modified state.";
CM_ SG_ 2564816638 J1939Network3 "Identifies the action to be performed on the SAE J1939 Network #3.";
CM_ SG_ 2564816638 J1939Network2 "Identifies the action to be performed on the SAE J1939 Network #2.";
CM_ SG_ 2564816638 ISO9141 "Identifies the action to be performed on the ISO9141 communications port.";
CM_ SG_ 2564816638 SAE_J1850 "Identifies the action to be performed on the SAE J1850 communications port.";
CM_ SG_ 2564816638 ManufacturerSpecificPort "Identifies the action to be performed on 'Other, manufacturer specific port' communications port.";
CM_ SG_ 2564816638 CurrentDataLink "Identifies the action to be performed on the communications port that this parameter was received.";
CM_ SG_ 2564816638 SAE_J1587 "Identifies the action to be performed on the SAE J1587 communications port.";
CM_ SG_ 2564816638 SAE_J1922 "Identifies the action to be performed on the SAE J1922 communications port.";
CM_ SG_ 2564816638 J1939Network1 "Identifies the action to be performed on the SAE J1939 Network #1, Primary vehicle communications port.";
CM_ BO_ 2566837502 "Emissions-related active diagnostic trouble codes.";
CM_ SG_ 2566837502 SPN5 "SPN #5 (Conversion Version 4)";
CM_ SG_ 2566837502 SPN4 "SPN #4 (Conversion Version 4)";
CM_ SG_ 2566837502 SPN3 "SPN #3 (Conversion Version 4)";
CM_ SG_ 2566837502 SPN2 "SPN #2 (Conversion Version 4)";
CM_ SG_ 2566837502 FlashRedStopLamp "This parameter provides the capability to flash the RSL (SPN 3039).";
CM_ SG_ 2566837502 FlashProtectLamp "This parameter provides the capability to flash the engine protect lamp (SPN 3041).";
CM_ SG_ 2566837502 FailureModeIdentifier5 "The FMI defines the type of failure detected in the subsystem identified by an SPN.";
CM_ SG_ 2566837502 FailureModeIdentifier4 "The FMI defines the type of failure detected in the subsystem identified by an SPN.";
CM_ SG_ 2566837502 FailureModeIdentifier3 "The FMI defines the type of failure detected in the subsystem identified by an SPN.";
CM_ SG_ 2566837502 OccurenceCount1 "The 7 bit occurence count field contains the number of times a fault has gone from active to previously active.";
CM_ SG_ 2566837502 FailureModeIdentifier1 "The FMI defines the type of failure detected in the subsystem identified by an SPN.";
CM_ SG_ 2566837502 SPN1 "SPN #1 (Conversion Version 4)";
CM_ SG_ 2566837502 MalfunctionIndicatorLampStatus "A lamp used to relay only emissions-related trouble code information.";
CM_ SG_ 2566837502 RedStopLampState "This lamp is uesed to relay trouble code information that is of a severe enought condition that it warrants stopping the vehicle.";
CM_ SG_ 2566837502 AmberWarningLampStatus "This lamp is used to relay trouble code information that is reporting a problem with the vehicle system but the vehicle need
not be immediately stopped.";
CM_ SG_ 2566837502 ProtectLampStatus "This lamp is used to relay trouble code informatio that is reporting a problem with a vehicle system that is most
probably not electronic subsystem related.";
CM_ SG_ 2566837502 FlashMalfuncIndicatorLamp "This parameter provides the capability to flash the MIL (SPN 3038).";
CM_ SG_ 2566837502 FlashAmberWarningLamp "This parameter provides the capability to flash the AWL (SPN 3040). ";
CM_ SG_ 2566837502 FailureModeIdentifier2 "The FMI defines the type of failure detected in the subsystem identified by an SPN.";
CM_ SG_ 2566837502 OccurenceCount5 "The 7 bit occurence count field contains the number of times a fault has gone from active to previously active.";
CM_ SG_ 2566837502 OccurenceCount4 "The 7 bit occurence count field contains the number of times a fault has gone from active to previously active.";
CM_ SG_ 2566837502 OccurenceCount3 "The 7 bit occurence count field contains the number of times a fault has gone from active to previously active.";
CM_ SG_ 2566837502 OccurenceCount2 "The 7 bit occurence count field contains the number of times a fault has gone from active to previously active.";
CM_ SG_ 2566837502 SPN5High "SPN #5 (Conversion Version 4)";
CM_ SG_ 2566837502 SPN4High "SPN #4 (Conversion Version 4)";
CM_ SG_ 2566837502 SPN3High "SPN #3 (Conversion Version 4)";
CM_ SG_ 2566837502 SPN2High "SPN #2 (Conversion Version 4)";
CM_ SG_ 2566837502 SPN1High "SPN #1 (Conversion Version 4)";
CM_ BO_ 2566837246 "Diagnostic data clear/Reset for active DTCs";
CM_ BO_ 2566836990 "Non-continously monitored systems test identifiers support";
CM_ SG_ 2566836990 TestIdentifierSupported "Indicates the test identifiers that the controller supports.";
CM_ BO_ 2566834942 "Active diagnostic trouble codes";
CM_ SG_ 2566834942 SPN5 "SPN #5 (Conversion Version 4)";
CM_ SG_ 2566834942 SPN4 "SPN #4 (Conversion Version 4)";
CM_ SG_ 2566834942 SPN3 "SPN #3 (Conversion Version 4)";
CM_ SG_ 2566834942 SPN2 "SPN #2 (Conversion Version 4)";
CM_ SG_ 2566834942 FailureModeIdentifier5 "The FMI defines the type of failure detected in the subsystem identified by an SPN.";
CM_ SG_ 2566834942 FailureModeIdentifier4 "The FMI defines the type of failure detected in the subsystem identified by an SPN.";
CM_ SG_ 2566834942 FailureModeIdentifier3 "The FMI defines the type of failure detected in the subsystem identified by an SPN.";
CM_ SG_ 2566834942 FlashRedStopLamp "This parameter provides the capability to flash the RSL (SPN 3039).";
CM_ SG_ 2566834942 FlashProtectLamp "This parameter provides the capability to flash the engine protect lamp (SPN 3041).";
CM_ SG_ 2566834942 FlashMalfuncIndicatorLamp "This parameter provides the capability to flash the MIL (SPN 3038).";
CM_ SG_ 2566834942 FlashAmberWarningLamp "This parameter provides the capability to flash the AWL (SPN 3040). ";
CM_ SG_ 2566834942 MalfunctionIndicatorLampStatus "A lamp used to relay only emissions-related trouble code information.";
CM_ SG_ 2566834942 AmberWarningLampStatus "This lamp is used to relay trouble code information that is reporting a problem with the vehicle system but the vehicle need
not be immediately stopped.";
CM_ SG_ 2566834942 OccurenceCount1 "The 7 bit occurence count field contains the number of times a fault has gone from active to previously active.";
CM_ SG_ 2566834942 FailureModeIdentifier1 "The FMI defines the type of failure detected in the subsystem identified by an SPN.";
CM_ SG_ 2566834942 SPN1 "SPN #1 (Conversion Version 4)";
CM_ SG_ 2566834942 RedStopLampState "This lamp is uesed to relay trouble code information that is of a severe enought condition that it warrants stopping the vehicle.";
CM_ SG_ 2566834942 ProtectLampStatus "This lamp is used to relay trouble code informatio that is reporting a problem with a vehicle system that is most
probably not electronic subsystem related.";
CM_ SG_ 2566834942 FailureModeIdentifier2 "The FMI defines the type of failure detected in the subsystem identified by an SPN.";
CM_ SG_ 2566834942 OccurenceCount5 "The 7 bit occurence count field contains the number of times a fault has gone from active to previously active.";
CM_ SG_ 2566834942 OccurenceCount4 "The 7 bit occurence count field contains the number of times a fault has gone from active to previously active.";
CM_ SG_ 2566834942 OccurenceCount3 "The 7 bit occurence count field contains the number of times a fault has gone from active to previously active.";
CM_ SG_ 2566834942 OccurenceCount2 "The 7 bit occurence count field contains the number of times a fault has gone from active to previously active.";
CM_ SG_ 2566834942 SPN5High "SPN #5 (Conversion Version 4)";
CM_ SG_ 2566834942 SPN4High "SPN #4 (Conversion Version 4)";
CM_ SG_ 2566834942 SPN3High "SPN #3 (Conversion Version 4)";
CM_ SG_ 2566834942 SPN2High "SPN #2 (Conversion Version 4)";
CM_ SG_ 2566834942 SPN1High "SPN #1 (Conversion Version 4)";
CM_ BO_ 2566780926 "Utility Total AC Reactive Power";
CM_ SG_ 2566780926 UtlityOverallPowerFactorLagging "Lead/lag status for utility incomer average power factor.";
CM_ SG_ 2566780926 UtilityOverallPowerFactor "The average power factor of the utility incomer.";
CM_ SG_ 2566780926 UtilityTotalReactivePower "The total reactive power delivered by the utility incomer";
CM_ BO_ 2566781182 "Utility Total AC Power";
CM_ SG_ 2566781182 UtilityTotalApparentPower "The total apparent power delivered by the utility incomer.";
CM_ SG_ 2566781182 UtilityTotalRealPower "Total real power delivered by the utility incomer.";
CM_ BO_ 2566778366 "Utility Total AC Energy";
CM_ SG_ 2566778366 UtilityTotalKWHoursImport "The total kilowatt-hours that have been imported by the utility incomer.";
CM_ SG_ 2566778366 UtilityTotalKWHoursExport "The total kilowatt-hours that have been exported by the utility incomer.";
CM_ BO_ 2566778622 "Utility Phase C AC Reactive Power";
CM_ SG_ 2566778622 UtilityPhaseCPowerFactorLagging "Lead/lag status for utility incomer phase C power factor.";
CM_ SG_ 2566778622 UtilityPhaseCPowerFactor "The power factor of phases C of the utility incomer.";
CM_ SG_ 2566778622 UtilityPhaseCReactivePower "The reactive power delivered by phase C of the utility incomer";
CM_ BO_ 2566778878 "Utility Phase C AC Power";
CM_ SG_ 2566778878 UtilityPhaseCApparentPower "The apparent power delivered by phase C of the utility incomer.";
CM_ SG_ 2566778878 UtilityPhaseCRealPower "The real power delivered by phase C of the utility incomer.";
CM_ BO_ 2566779134 "Utility Phase C AC Basic Quantities";
CM_ SG_ 2566779134 UtilityPhaseCACRMSCurrent "RMS current measured at the utility incomer phase C.";
CM_ SG_ 2566779134 UtilityPhaseCACFrequency "AC frequency measured at the utility incomer phase C.";
CM_ SG_ 2566779134 UtltyPhsCLneNeutralACRMSVoltage "Line to Neutral RMS voltage measured at the utility incomer phase C.";
CM_ SG_ 2566779134 UtltyPhseCALineLineACRMSVoltage "Line to Line RMS voltage measured at the utility incomer phase CA.";
CM_ BO_ 2566779390 "Utility Phase B AC Reactive Power";
CM_ SG_ 2566779390 UtilityPhaseBPowerFactorLagging "Lead/lag status for utility incomer phase B power factor.";
CM_ SG_ 2566779390 UtilityPhaseBPowerFactor "The power factor of phases B of the utility incomer.";
CM_ SG_ 2566779390 UtilityPhaseBReactivePower "The reactive power delivered by phase B of the utility incomer";
CM_ BO_ 2566779646 "Utility Phase B AC Power";
CM_ SG_ 2566779646 UtilityPhaseBApparentPower "The apparent power delivered by phase B of the utility incomer.";
CM_ SG_ 2566779646 UtilityPhaseBRealPower "The real power delivered by phase B of the utility incomer.";
CM_ BO_ 2566779902 "Utility Phase B AC Basic Quantities";
CM_ SG_ 2566779902 UtilityPhaseBACRMSCurrent "RMS current measured at the utility incomer phase B.";
CM_ SG_ 2566779902 UtilityPhaseBACFrequency "AC frequency measured at the utility incomer phase B.";
CM_ SG_ 2566779902 UtltyPhsBLneNeutralACRMSVoltage "Line to Neutral RMS voltage measured at the utility incomer phase B.";
CM_ SG_ 2566779902 UtltyPhseBCLineLineACRMSVoltage "Line to Line RMS voltage measured at the utility incomer phase BC.";
CM_ BO_ 2566780158 "Utility Phase A  AC Reactive Power";
CM_ SG_ 2566780158 UtilityPhaseAPowerFactorLagging "Lead/lag status for utility incomer phase A power factor.";
CM_ SG_ 2566780158 UtilityPhaseAPowerFactor "The power factor of phase A of the utility incomer.";
CM_ SG_ 2566780158 UtilityPhaseAReactivePower "The reactive power delivered by phase A of the utility incomer";
CM_ BO_ 2566780414 "Utility Phase A  AC Power";
CM_ SG_ 2566780414 UtilityPhaseAApparentPower "The apparent power delivered by phase A of the utility incomer.";
CM_ SG_ 2566780414 UtilityPhaseARealPower "The real power delivered by phase A of the utility incomer.";
CM_ BO_ 2566780670 "Utility Phase A Basic AC Quantities";
CM_ SG_ 2566780670 UtilityPhaseAACRMSCurrent "RMS current measured at the utility incomer phase A.";
CM_ SG_ 2566780670 UtilityPhaseAACFrequency "AC frequency measured at the utility incomer phase A.";
CM_ SG_ 2566780670 UtltyPhsALneNeutralACRMSVoltage "Line to Neutral RMS voltage measured at the utility incomer phase A.";
CM_ SG_ 2566780670 UtltyPhseABLineLineACRMSVoltage "Line to Line RMS voltage measured at the utility incomer phase AB.";
CM_ BO_ 2566781438 "Utility Average Basic AC Quantities";
CM_ SG_ 2566781438 UtilityAverageACRMSCurrent "Average RMS current measured at the utility incomer.";
CM_ SG_ 2566781438 UtilityAverageACFrequency "Average AC frequency measured at the utility incomer.";
CM_ SG_ 2566781438 UtltyAvrgLneNeutralACRMSVoltage "The average Line to Neutral AC RMS voltage measured at the utility incomer .";
CM_ SG_ 2566781438 UtltyAvrageLineLineACRMSVoltage "Average Line to Line RMS voltage measured at the utility incomer .";
CM_ BO_ 2566784254 "Generator Total AC Reactive Power";
CM_ SG_ 2566784254 GnrtorOverallPowerFactorLagging "Lead/lag status for generator average power factor.";
CM_ SG_ 2566784254 GeneratorOverallPowerFactor "The average power factor of the generator.";
CM_ SG_ 2566784254 GeneratorTotalReactivePower "The total reactive power delivered by the generator";
CM_ BO_ 2566784510 "Generator Total AC Power";
CM_ SG_ 2566784510 GeneratorTotalApparentPower "The total apparent power delivered by the generator.";
CM_ SG_ 2566784510 GeneratorTotalRealPower "Total real power delivered by the generator.";
BA_DEF_ SG_  "GenSigSendType" ENUM  "Cyclic","OnWrite","reserved","OnChange","reserved","reserved","reserved","NoSigSendType";
BA_DEF_ SG_  "GenSigILSupport" ENUM  "Yes","No";
BA_DEF_ SG_  "GenSigEVName" STRING ;
BA_DEF_ SG_  "SigType" STRING ;
BA_DEF_ SG_  "SPN" INT 0 524287;
BA_DEF_ BO_  "GenMsgILSupport" ENUM  "Yes","No";
BA_DEF_ BO_  "GenMsgRequestable" INT 0 1;
BA_DEF_ BO_  "GenMsgSendType" ENUM  "cyclic","reserved","cyclicIfActive","reserved","reserved","reserved","reserved","reserved","noMsgSendType";
BA_DEF_ BO_  "VFrameFormat" ENUM  "StandardCAN","ExtendedCAN","reserved","J1939PG";
BA_DEF_ BO_  "SingleFrame" INT 0 1;
BA_DEF_ BO_  "GenMsgCycleTime" INT 0 3600000;
BA_DEF_DEF_  "GenSigSendType" "NoSigSendType";
BA_DEF_DEF_  "GenSigILSupport" "Yes";
BA_DEF_DEF_  "GenSigEVName" "Env@Nodename_@Signame";
BA_DEF_DEF_  "SigType" "";
BA_DEF_DEF_  "SPN" 0;
BA_DEF_DEF_  "GenMsgILSupport" "Yes";
BA_DEF_DEF_  "GenMsgRequestable" 1;
BA_DEF_DEF_  "GenMsgSendType" "noMsgSendType";
BA_DEF_DEF_  "VFrameFormat" "J1939PG";
BA_DEF_DEF_  "SingleFrame" 1;
BA_DEF_DEF_  "GenMsgCycleTime" 0;
BA_ "GenMsgCycleTime" BO_ 2566844926 100;
BA_ "GenMsgSendType" BO_ 2566844926 0;
BA_ "GenMsgCycleTime" BO_ 2566775294 1000;
BA_ "GenMsgSendType" BO_ 2566775294 0;
BA_ "GenMsgCycleTime" BO_ 2566803710 1000;
BA_ "GenMsgSendType" BO_ 2566803710 0;
BA_ "GenMsgCycleTime" BO_ 2566809342 1000;
BA_ "GenMsgSendType" BO_ 2566809342 0;
BA_ "GenMsgCycleTime" BO_ 2365446910 100;
BA_ "GenMsgSendType" BO_ 2365446910 0;
BA_ "GenMsgCycleTime" BO_ 2365446398 100;
BA_ "GenMsgSendType" BO_ 2365446398 0;
BA_ "GenMsgCycleTime" BO_ 2365445886 100;
BA_ "GenMsgSendType" BO_ 2365445886 0;
BA_ "GenMsgCycleTime" BO_ 2566847230 1000;
BA_ "GenMsgSendType" BO_ 2566847230 0;
BA_ "GenMsgCycleTime" BO_ 2566848254 1000;
BA_ "GenMsgSendType" BO_ 2566848254 0;
BA_ "GenMsgCycleTime" BO_ 2633934846 1000;
BA_ "GenMsgSendType" BO_ 2633934846 0;
BA_ "GenMsgCycleTime" BO_ 2362572542 100;
BA_ "GenMsgSendType" BO_ 2362572542 2;
BA_ "GenMsgCycleTime" BO_ 2365478910 100;
BA_ "GenMsgSendType" BO_ 2365478910 0;
BA_ "GenMsgCycleTime" BO_ 2566805758 100;
BA_ "GenMsgSendType" BO_ 2566805758 0;
BA_ "GenMsgCycleTime" BO_ 2566806014 100;
BA_ "GenMsgSendType" BO_ 2566806014 0;
BA_ "GenMsgCycleTime" BO_ 2362638078 100;
BA_ "GenMsgSendType" BO_ 2362638078 0;
BA_ "GenMsgCycleTime" BO_ 2365479678 100;
BA_ "GenMsgSendType" BO_ 2365479678 0;
BA_ "GenMsgCycleTime" BO_ 2566837758 1000;
BA_ "GenMsgSendType" BO_ 2566837758 0;
BA_ "GenMsgCycleTime" BO_ 2566775038 1000;
BA_ "GenMsgSendType" BO_ 2566775038 0;
BA_ "SPN" SG_ 2563833598 IlluminationBrightnessPercent 1487;
BA_ "SigType" SG_ 2563833598 IlluminationBrightnessPercent "RANGE";
BA_ "SPN" SG_ 2566844926 ParkBrakeReleaseInhibitRq 3807;
BA_ "SigType" SG_ 2566844926 ParkBrakeReleaseInhibitRq "DISCRETE";
BA_ "SPN" SG_ 2566844926 EngShutdownOverrideSwitch 1237;
BA_ "SigType" SG_ 2566844926 EngShutdownOverrideSwitch "DISCRETE";
BA_ "SPN" SG_ 2566844926 EngTestModeSwitch 966;
BA_ "SigType" SG_ 2566844926 EngTestModeSwitch "DISCRETE";
BA_ "SPN" SG_ 2566844926 EngIdleDecrementSwitch 967;
BA_ "SigType" SG_ 2566844926 EngIdleDecrementSwitch "DISCRETE";
BA_ "SPN" SG_ 2566844926 EngIdleIncrementSwitch 968;
BA_ "SigType" SG_ 2566844926 EngIdleIncrementSwitch "DISCRETE";
BA_ "SPN" SG_ 2566844926 CruiseCtrlStates 527;
BA_ "SigType" SG_ 2566844926 CruiseCtrlStates "DISCRETE";
BA_ "SPN" SG_ 2566844926 PTOState 976;
BA_ "SigType" SG_ 2566844926 PTOState "DISCRETE";
BA_ "SPN" SG_ 2566844926 CruiseCtrlSetSpeed 86;
BA_ "SigType" SG_ 2566844926 CruiseCtrlSetSpeed "RANGE";
BA_ "SPN" SG_ 2566844926 CruiseCtrlAccelerateSwitch 602;
BA_ "SigType" SG_ 2566844926 CruiseCtrlAccelerateSwitch "DISCRETE";
BA_ "SPN" SG_ 2566844926 CruiseCtrlResumeSwitch 601;
BA_ "SigType" SG_ 2566844926 CruiseCtrlResumeSwitch "DISCRETE";
BA_ "SPN" SG_ 2566844926 CruiseCtrlCoastSwitch 600;
BA_ "SigType" SG_ 2566844926 CruiseCtrlCoastSwitch "DISCRETE";
BA_ "SPN" SG_ 2566844926 CruiseCtrlSetSwitch 599;
BA_ "SigType" SG_ 2566844926 CruiseCtrlSetSwitch "DISCRETE";
BA_ "SPN" SG_ 2566844926 ClutchSwitch 598;
BA_ "SigType" SG_ 2566844926 ClutchSwitch "DISCRETE";
BA_ "SPN" SG_ 2566844926 BrakeSwitch 597;
BA_ "SigType" SG_ 2566844926 BrakeSwitch "DISCRETE";
BA_ "SPN" SG_ 2566844926 CruiseCtrlEnableSwitch 596;
BA_ "SigType" SG_ 2566844926 CruiseCtrlEnableSwitch "DISCRETE";
BA_ "SPN" SG_ 2566844926 CruiseCtrlActive 595;
BA_ "SigType" SG_ 2566844926 CruiseCtrlActive "DISCRETE";
BA_ "SPN" SG_ 2566844926 WheelBasedVehicleSpeed 84;
BA_ "SigType" SG_ 2566844926 WheelBasedVehicleSpeed "RANGE";
BA_ "SPN" SG_ 2566844926 CruiseCtrlPauseSwitch 1633;
BA_ "SigType" SG_ 2566844926 CruiseCtrlPauseSwitch "DISCRETE";
BA_ "SPN" SG_ 2566844926 ParkingBrakeSwitch 70;
BA_ "SigType" SG_ 2566844926 ParkingBrakeSwitch "DISCRETE";
BA_ "SPN" SG_ 2566844926 TwoSpeedAxleSwitch 69;
BA_ "SigType" SG_ 2566844926 TwoSpeedAxleSwitch "DISCRETE";
BA_ "SPN" SG_ 2566843902 CruiseCtrlLowSetLimitSpeed 88;
BA_ "SigType" SG_ 2566843902 CruiseCtrlLowSetLimitSpeed "RANGE";
BA_ "SPN" SG_ 2566843902 CruiseCtrlHighSetLimitSpeed 87;
BA_ "SigType" SG_ 2566843902 CruiseCtrlHighSetLimitSpeed "RANGE";
BA_ "SPN" SG_ 2566843902 MaxVehicleSpeedLimit 74;
BA_ "SigType" SG_ 2566843902 MaxVehicleSpeedLimit "RANGE";
BA_ "SPN" SG_ 2566809598 AuxHeaterMaxOutputPower 1690;
BA_ "SigType" SG_ 2566809598 AuxHeaterMaxOutputPower "RANGE";
BA_ "SPN" SG_ 2633940222 TripServiceBrakeApps 993;
BA_ "SigType" SG_ 2633940222 TripServiceBrakeApps "RANGE";
BA_ "SPN" SG_ 2633940222 TripServiceBrakeDistance 992;
BA_ "SigType" SG_ 2633940222 TripServiceBrakeDistance "RANGE";
BA_ "SPN" SG_ 2633940222 TripCompressionBrakeDistance 991;
BA_ "SigType" SG_ 2633940222 TripCompressionBrakeDistance "RANGE";
BA_ "SPN" SG_ 2633940222 TotalCompressionBrakeDistance 990;
BA_ "SigType" SG_ 2633940222 TotalCompressionBrakeDistance "RANGE";
BA_ "SPN" SG_ 2566775294 CbA_CRfrgrntCmprssorOutletPress 2609;
BA_ "SigType" SG_ 2566775294 CbA_CRfrgrntCmprssorOutletPress "RANGE";
BA_ "SPN" SG_ 2566803710 Battery2Temp 1801;
BA_ "SigType" SG_ 2566803710 Battery2Temp "RANGE";
BA_ "SPN" SG_ 2566803710 Battery1Temp 1800;
BA_ "SigType" SG_ 2566803710 Battery1Temp "RANGE";
BA_ "SPN" SG_ 2566809342 BatteryMainSwitchHoldState 1681;
BA_ "SigType" SG_ 2566809342 BatteryMainSwitchHoldState "DISCRETE";
BA_ "SPN" SG_ 2365446910 Joystick3XAxisDetentPosStatus 2754;
BA_ "SigType" SG_ 2365446910 Joystick3XAxisDetentPosStatus "DISCRETE";
BA_ "SPN" SG_ 2365446910 Joystick3Button9PressedStatus 2767;
BA_ "SigType" SG_ 2365446910 Joystick3Button9PressedStatus "DISCRETE";
BA_ "SPN" SG_ 2365446910 Joystick3Button10PressedStatus 2768;
BA_ "SigType" SG_ 2365446910 Joystick3Button10PressedStatus "DISCRETE";
BA_ "SPN" SG_ 2365446910 Joystick3Button11PressedStatus 2769;
BA_ "SigType" SG_ 2365446910 Joystick3Button11PressedStatus "DISCRETE";
BA_ "SPN" SG_ 2365446910 Joystick3Button12PressedStatus 2770;
BA_ "SigType" SG_ 2365446910 Joystick3Button12PressedStatus "DISCRETE";
BA_ "SPN" SG_ 2365446910 Joystick3YAxisDetentPosStatus 2755;
BA_ "SigType" SG_ 2365446910 Joystick3YAxisDetentPosStatus "DISCRETE";
BA_ "SPN" SG_ 2365446910 Joystick3YAxisPos 2735;
BA_ "SigType" SG_ 2365446910 Joystick3YAxisPos "RANGE";
BA_ "SPN" SG_ 2365446910 Jystck3YAxsLvrFrwrdPstvPsStatus 2740;
BA_ "SigType" SG_ 2365446910 Jystck3YAxsLvrFrwrdPstvPsStatus "DISCRETE";
BA_ "SPN" SG_ 2365446910 Jystck3YAxsLvrBckNgtvePosStatus 2745;
BA_ "SigType" SG_ 2365446910 Jystck3YAxsLvrBckNgtvePosStatus "DISCRETE";
BA_ "SPN" SG_ 2365446910 Joystick3YAxisNeutralPosStatus 2750;
BA_ "SigType" SG_ 2365446910 Joystick3YAxisNeutralPosStatus "DISCRETE";
BA_ "SPN" SG_ 2365446910 Joystick3XAxisPos 2734;
BA_ "SigType" SG_ 2365446910 Joystick3XAxisPos "RANGE";
BA_ "SPN" SG_ 2365446910 Jystck3XAxsLvrRghtPstvPosStatus 2739;
BA_ "SigType" SG_ 2365446910 Jystck3XAxsLvrRghtPstvPosStatus "DISCRETE";
BA_ "SPN" SG_ 2365446910 Jystck3XAxsLvrLftNgtvePosStatus 2744;
BA_ "SigType" SG_ 2365446910 Jystck3XAxsLvrLftNgtvePosStatus "DISCRETE";
BA_ "SPN" SG_ 2365446910 Joystick3XAxisNeutralPosStatus 2749;
BA_ "SigType" SG_ 2365446910 Joystick3XAxisNeutralPosStatus "DISCRETE";
BA_ "SPN" SG_ 2365446910 Joystick3Button5PressedStatus 2763;
BA_ "SigType" SG_ 2365446910 Joystick3Button5PressedStatus "DISCRETE";
BA_ "SPN" SG_ 2365446910 Joystick3Button6PressedStatus 2764;
BA_ "SigType" SG_ 2365446910 Joystick3Button6PressedStatus "DISCRETE";
BA_ "SPN" SG_ 2365446910 Joystick3Button7PressedStatus 2765;
BA_ "SigType" SG_ 2365446910 Joystick3Button7PressedStatus "DISCRETE";
BA_ "SPN" SG_ 2365446910 Joystick3Button8PressedStatus 2766;
BA_ "SigType" SG_ 2365446910 Joystick3Button8PressedStatus "DISCRETE";
BA_ "SPN" SG_ 2365446910 Joystick3Button1PressedStatus 2759;
BA_ "SigType" SG_ 2365446910 Joystick3Button1PressedStatus "DISCRETE";
BA_ "SPN" SG_ 2365446910 Joystick3Button2PressedStatus 2760;
BA_ "SigType" SG_ 2365446910 Joystick3Button2PressedStatus "DISCRETE";
BA_ "SPN" SG_ 2365446910 Joystick3Button3PressedStatus 2761;
BA_ "SigType" SG_ 2365446910 Joystick3Button3PressedStatus "DISCRETE";
BA_ "SPN" SG_ 2365446910 Joystick3Button4PressedStatus 2762;
BA_ "SigType" SG_ 2365446910 Joystick3Button4PressedStatus "DISCRETE";
BA_ "SPN" SG_ 2365446398 Joystick2XAxisDetentPosStatus 2717;
BA_ "SigType" SG_ 2365446398 Joystick2XAxisDetentPosStatus "DISCRETE";
BA_ "SPN" SG_ 2365446398 Joystick2YAxisDetentPosStatus 2718;
BA_ "SigType" SG_ 2365446398 Joystick2YAxisDetentPosStatus "DISCRETE";
BA_ "SPN" SG_ 2365446398 Joystick2YAxisPos 2698;
BA_ "SigType" SG_ 2365446398 Joystick2YAxisPos "RANGE";
BA_ "SPN" SG_ 2365446398 Jystck2YAxsLvrFrwrdPstvPsStatus 2703;
BA_ "SigType" SG_ 2365446398 Jystck2YAxsLvrFrwrdPstvPsStatus "DISCRETE";
BA_ "SPN" SG_ 2365446398 Jystck2YAxsLvrBckNgtvePosStatus 2708;
BA_ "SigType" SG_ 2365446398 Jystck2YAxsLvrBckNgtvePosStatus "DISCRETE";
BA_ "SPN" SG_ 2365446398 Joystick2YAxisNeutralPosStatus 2713;
BA_ "SigType" SG_ 2365446398 Joystick2YAxisNeutralPosStatus "DISCRETE";
BA_ "SPN" SG_ 2365446398 Joystick2XAxisPos 2697;
BA_ "SigType" SG_ 2365446398 Joystick2XAxisPos "RANGE";
BA_ "SPN" SG_ 2365446398 Jystck2XAxsLvrRghtPstvPosStatus 2702;
BA_ "SigType" SG_ 2365446398 Jystck2XAxsLvrRghtPstvPosStatus "DISCRETE";
BA_ "SPN" SG_ 2365446398 Jystck2XAxsLvrLftNgtvePosStatus 2707;
BA_ "SigType" SG_ 2365446398 Jystck2XAxsLvrLftNgtvePosStatus "DISCRETE";
BA_ "SPN" SG_ 2365446398 Joystick2XAxisNeutralPosStatus 2712;
BA_ "SigType" SG_ 2365446398 Joystick2XAxisNeutralPosStatus "DISCRETE";
BA_ "SPN" SG_ 2365446398 Joystick2Button9PressedStatus 2730;
BA_ "SigType" SG_ 2365446398 Joystick2Button9PressedStatus "DISCRETE";
BA_ "SPN" SG_ 2365446398 Joystick2Button10PressedStatus 2731;
BA_ "SigType" SG_ 2365446398 Joystick2Button10PressedStatus "DISCRETE";
BA_ "SPN" SG_ 2365446398 Joystick2Button11PressedStatus 2732;
BA_ "SigType" SG_ 2365446398 Joystick2Button11PressedStatus "DISCRETE";
BA_ "SPN" SG_ 2365446398 Joystick2Button12PressedStatus 2733;
BA_ "SigType" SG_ 2365446398 Joystick2Button12PressedStatus "DISCRETE";
BA_ "SPN" SG_ 2365446398 Joystick2Button5PressedStatus 2726;
BA_ "SigType" SG_ 2365446398 Joystick2Button5PressedStatus "DISCRETE";
BA_ "SPN" SG_ 2365446398 Joystick2Button6PressedStatus 2727;
BA_ "SigType" SG_ 2365446398 Joystick2Button6PressedStatus "DISCRETE";
BA_ "SPN" SG_ 2365446398 Joystick2Button7PressedStatus 2728;
BA_ "SigType" SG_ 2365446398 Joystick2Button7PressedStatus "DISCRETE";
BA_ "SPN" SG_ 2365446398 Joystick2Button8PressedStatus 2729;
BA_ "SigType" SG_ 2365446398 Joystick2Button8PressedStatus "DISCRETE";
BA_ "SPN" SG_ 2365446398 Joystick2Button1PressedStatus 2722;
BA_ "SigType" SG_ 2365446398 Joystick2Button1PressedStatus "DISCRETE";
BA_ "SPN" SG_ 2365446398 Joystick2Button2PressedStatus 2723;
BA_ "SigType" SG_ 2365446398 Joystick2Button2PressedStatus "DISCRETE";
BA_ "SPN" SG_ 2365446398 Joystick2Button3PressedStatus 2724;
BA_ "SigType" SG_ 2365446398 Joystick2Button3PressedStatus "DISCRETE";
BA_ "SPN" SG_ 2365446398 Joystick2Button4PressedStatus 2725;
BA_ "SigType" SG_ 2365446398 Joystick2Button4PressedStatus "DISCRETE";
BA_ "SPN" SG_ 2365445886 Joystick1XAxisDetentPosStatus 2680;
BA_ "SigType" SG_ 2365445886 Joystick1XAxisDetentPosStatus "DISCRETE";
BA_ "SPN" SG_ 2365445886 Joystick1YAxisDetentPosStatus 2681;
BA_ "SigType" SG_ 2365445886 Joystick1YAxisDetentPosStatus "DISCRETE";
BA_ "SPN" SG_ 2365445886 Joystick1YAxisPos 2661;
BA_ "SigType" SG_ 2365445886 Joystick1YAxisPos "RANGE";
BA_ "SPN" SG_ 2365445886 Jystck1YAxsLvrFrwrdPstvPsStatus 2666;
BA_ "SigType" SG_ 2365445886 Jystck1YAxsLvrFrwrdPstvPsStatus "DISCRETE";
BA_ "SPN" SG_ 2365445886 Jystck1YAxsLvrBckNgtvePosStatus 2671;
BA_ "SigType" SG_ 2365445886 Jystck1YAxsLvrBckNgtvePosStatus "DISCRETE";
BA_ "SPN" SG_ 2365445886 Joystick1YAxisNeutralPosStatus 2676;
BA_ "SigType" SG_ 2365445886 Joystick1YAxisNeutralPosStatus "DISCRETE";
BA_ "SPN" SG_ 2365445886 Joystick1XAxisPos 2660;
BA_ "SigType" SG_ 2365445886 Joystick1XAxisPos "RANGE";
BA_ "SPN" SG_ 2365445886 Joystick1Button9PressedStatus 2693;
BA_ "SigType" SG_ 2365445886 Joystick1Button9PressedStatus "DISCRETE";
BA_ "SPN" SG_ 2365445886 Joystick1Button10PressedStatus 2694;
BA_ "SigType" SG_ 2365445886 Joystick1Button10PressedStatus "DISCRETE";
BA_ "SPN" SG_ 2365445886 Joystick1Button11PressedStatus 2695;
BA_ "SigType" SG_ 2365445886 Joystick1Button11PressedStatus "DISCRETE";
BA_ "SPN" SG_ 2365445886 Joystick1Button12PressedStatus 2696;
BA_ "SigType" SG_ 2365445886 Joystick1Button12PressedStatus "DISCRETE";
BA_ "SPN" SG_ 2365445886 Joystick1Button5PressedStatus 2689;
BA_ "SigType" SG_ 2365445886 Joystick1Button5PressedStatus "DISCRETE";
BA_ "SPN" SG_ 2365445886 Joystick1Button6PressedStatus 2690;
BA_ "SigType" SG_ 2365445886 Joystick1Button6PressedStatus "DISCRETE";
BA_ "SPN" SG_ 2365445886 Joystick1Button7PressedStatus 2691;
BA_ "SigType" SG_ 2365445886 Joystick1Button7PressedStatus "DISCRETE";
BA_ "SPN" SG_ 2365445886 Joystick1Button8PressedStatus 2692;
BA_ "SigType" SG_ 2365445886 Joystick1Button8PressedStatus "DISCRETE";
BA_ "SPN" SG_ 2365445886 Joystick1Button1PressedStatus 2685;
BA_ "SigType" SG_ 2365445886 Joystick1Button1PressedStatus "DISCRETE";
BA_ "SPN" SG_ 2365445886 Joystick1Button2PressedStatus 2686;
BA_ "SigType" SG_ 2365445886 Joystick1Button2PressedStatus "DISCRETE";
BA_ "SPN" SG_ 2365445886 Joystick1Button3PressedStatus 2687;
BA_ "SigType" SG_ 2365445886 Joystick1Button3PressedStatus "DISCRETE";
BA_ "SPN" SG_ 2365445886 Joystick1Button4PressedStatus 2688;
BA_ "SigType" SG_ 2365445886 Joystick1Button4PressedStatus "DISCRETE";
BA_ "SPN" SG_ 2365445886 Jystck1XAxsLvrRghtPstvPosStatus 2665;
BA_ "SigType" SG_ 2365445886 Jystck1XAxsLvrRghtPstvPosStatus "DISCRETE";
BA_ "SPN" SG_ 2365445886 Jystck1XAxsLvrLftNgtvePosStatus 2670;
BA_ "SigType" SG_ 2365445886 Jystck1XAxsLvrLftNgtvePosStatus "DISCRETE";
BA_ "SPN" SG_ 2365445886 Joystick1XAxisNeutralPosStatus 2675;
BA_ "SigType" SG_ 2365445886 Joystick1XAxisNeutralPosStatus "DISCRETE";
BA_ "SPN" SG_ 2566847230 ParkingBrakeRedWarningSignal 3557;
BA_ "SigType" SG_ 2566847230 ParkingBrakeRedWarningSignal "DISCRETE";
BA_ "SPN" SG_ 2566847230 ParkBrakeReleaseInhibitStatus 3808;
BA_ "SigType" SG_ 2566847230 ParkBrakeReleaseInhibitStatus "DISCRETE";
BA_ "SPN" SG_ 2566847230 ParkingBrakeActuator 619;
BA_ "SigType" SG_ 2566847230 ParkingBrakeActuator "DISCRETE";
BA_ "SPN" SG_ 2566847230 BrakeSecondPress 118;
BA_ "SigType" SG_ 2566847230 BrakeSecondPress "RANGE";
BA_ "SPN" SG_ 2566847230 BrakePrimaryPress 117;
BA_ "SigType" SG_ 2566847230 BrakePrimaryPress "RANGE";
BA_ "SPN" SG_ 2566847230 BrakeAppPress 116;
BA_ "SigType" SG_ 2566847230 BrakeAppPress "RANGE";
BA_ "SPN" SG_ 2566848254 AuxPumpPress 73;
BA_ "SigType" SG_ 2566848254 AuxPumpPress "RANGE";
BA_ "SPN" SG_ 2631728894 AntitheftRandomNumber 1198;
BA_ "SigType" SG_ 2631728894 AntitheftRandomNumber "RANGE";
BA_ "SPN" SG_ 2631728894 AntitheftComponentStatusStates 1196;
BA_ "SigType" SG_ 2631728894 AntitheftComponentStatusStates "DISCRETE";
BA_ "SPN" SG_ 2631728894 AntthftEncryptnSdPrsntIndicator 1194;
BA_ "SigType" SG_ 2631728894 AntthftEncryptnSdPrsntIndicator "DISCRETE";
BA_ "SPN" SG_ 2631728894 AntitheftModifyPwdStates 1197;
BA_ "SigType" SG_ 2631728894 AntitheftModifyPwdStates "DISCRETE";
BA_ "SPN" SG_ 2631728894 AntitheftPwdValidIndicator 1195;
BA_ "SigType" SG_ 2631728894 AntitheftPwdValidIndicator "DISCRETE";
BA_ "SPN" SG_ 2631794430 AntitheftPasswordRepresentation 1202;
BA_ "SigType" SG_ 2631794430 AntitheftPasswordRepresentation "RANGE";
BA_ "SPN" SG_ 2631794430 AntitheftCmdStates 1201;
BA_ "SigType" SG_ 2631794430 AntitheftCmdStates "DISCRETE";
BA_ "SPN" SG_ 2631794430 AntitheftDesiredExitModeStates 1200;
BA_ "SigType" SG_ 2631794430 AntitheftDesiredExitModeStates "DISCRETE";
BA_ "SPN" SG_ 2631794430 AntthftEncryptonIndicatorStates 1199;
BA_ "SigType" SG_ 2631794430 AntthftEncryptonIndicatorStates "DISCRETE";
BA_ "SPN" SG_ 2633934846 EngAltWinding3Temp 1126;
BA_ "SigType" SG_ 2633934846 EngAltWinding3Temp "RANGE";
BA_ "SPN" SG_ 2633934846 EngAltWinding2Temp 1125;
BA_ "SigType" SG_ 2633934846 EngAltWinding2Temp "RANGE";
BA_ "SPN" SG_ 2633934846 EngAltWinding1Temp 1124;
BA_ "SigType" SG_ 2633934846 EngAltWinding1Temp "RANGE";
BA_ "SPN" SG_ 2633934846 EngAltBearing2Temp 1123;
BA_ "SigType" SG_ 2633934846 EngAltBearing2Temp "RANGE";
BA_ "SPN" SG_ 2633934846 EngAltBearing1Temp 1122;
BA_ "SigType" SG_ 2633934846 EngAltBearing1Temp "RANGE";
BA_ "SPN" SG_ 2362572542 LevelPresetRearAxleRight 1735;
BA_ "SigType" SG_ 2362572542 LevelPresetRearAxleRight "RANGE";
BA_ "SPN" SG_ 2362572542 LevelPresetRearAxleLeft 1758;
BA_ "SigType" SG_ 2362572542 LevelPresetRearAxleLeft "RANGE";
BA_ "SPN" SG_ 2362572542 LevelPresetFrontAxleRight 1757;
BA_ "SigType" SG_ 2362572542 LevelPresetFrontAxleRight "RANGE";
BA_ "SPN" SG_ 2362572542 LevelPresetFrontAxleLeft 1732;
BA_ "SigType" SG_ 2362572542 LevelPresetFrontAxleLeft "RANGE";
BA_ "SPN" SG_ 2365478910 ElctrncShckAbsrbrCtrlMdLft_TgAxl 1831;
BA_ "SigType" SG_ 2365478910 ElctrncShckAbsrbrCtrlMdLft_TgAxl "DISCRETE";
BA_ "SPN" SG_ 2365478910 ElctrncShckAbsrbrCtrlMdRearAxle 1832;
BA_ "SigType" SG_ 2365478910 ElctrncShckAbsrbrCtrlMdRearAxle "DISCRETE";
BA_ "SPN" SG_ 2365478910 ElctrncShckAbsrbrCtrlMdFrntAxle 1833;
BA_ "SigType" SG_ 2365478910 ElctrncShckAbsrbrCtrlMdFrntAxle "DISCRETE";
BA_ "SPN" SG_ 2365478910 DamperStiffnessLift_TagAxle 1731;
BA_ "SigType" SG_ 2365478910 DamperStiffnessLift_TagAxle "RANGE";
BA_ "SPN" SG_ 2365478910 DamperStiffnessRearAxle 1730;
BA_ "SigType" SG_ 2365478910 DamperStiffnessRearAxle "RANGE";
BA_ "SPN" SG_ 2365478910 DamperStiffnessFrontAxle 1729;
BA_ "SigType" SG_ 2365478910 DamperStiffnessFrontAxle "RANGE";
BA_ "SPN" SG_ 2566805758 BellowPressRearAxleRight 1728;
BA_ "SigType" SG_ 2566805758 BellowPressRearAxleRight "RANGE";
BA_ "SPN" SG_ 2566805758 BellowPressRearAxleLeft 1727;
BA_ "SigType" SG_ 2566805758 BellowPressRearAxleLeft "RANGE";
BA_ "SPN" SG_ 2566805758 BellowPressFrontAxleRight 1726;
BA_ "SigType" SG_ 2566805758 BellowPressFrontAxleRight "RANGE";
BA_ "SPN" SG_ 2566805758 BellowPressFrontAxleLeft 1725;
BA_ "SigType" SG_ 2566805758 BellowPressFrontAxleLeft "RANGE";
BA_ "SPN" SG_ 2566806014 RelativeLevelRearAxleRight 1723;
BA_ "SigType" SG_ 2566806014 RelativeLevelRearAxleRight "RANGE";
BA_ "SPN" SG_ 2566806014 RelativeLevelRearAxleLeft 1724;
BA_ "SigType" SG_ 2566806014 RelativeLevelRearAxleLeft "RANGE";
BA_ "SPN" SG_ 2566806014 RelativeLevelFrontAxleRight 1722;
BA_ "SigType" SG_ 2566806014 RelativeLevelFrontAxleRight "RANGE";
BA_ "SPN" SG_ 2566806014 RelativeLevelFrontAxleLeft 1721;
BA_ "SigType" SG_ 2566806014 RelativeLevelFrontAxleLeft "RANGE";
BA_ "SPN" SG_ 2362638078 ProhibitAirSuspensionCtrl 3215;
BA_ "SigType" SG_ 2362638078 ProhibitAirSuspensionCtrl "DISCRETE";
BA_ "SPN" SG_ 2362638078 KneelingCmdRearAxle 1829;
BA_ "SigType" SG_ 2362638078 KneelingCmdRearAxle "DISCRETE";
BA_ "SPN" SG_ 2362638078 KneelingCmdFrontAxle 1830;
BA_ "SigType" SG_ 2362638078 KneelingCmdFrontAxle "DISCRETE";
BA_ "SPN" SG_ 2362638078 DamperStiffnessRqLift_TagAxle 1720;
BA_ "SigType" SG_ 2362638078 DamperStiffnessRqLift_TagAxle "RANGE";
BA_ "SPN" SG_ 2362638078 DamperStiffnessRqRearAxle 1719;
BA_ "SigType" SG_ 2362638078 DamperStiffnessRqRearAxle "RANGE";
BA_ "SPN" SG_ 2362638078 DamperStiffnessRqFrontAxle 1718;
BA_ "SigType" SG_ 2362638078 DamperStiffnessRqFrontAxle "RANGE";
BA_ "SPN" SG_ 2362638078 LevelCtrlModeRq 1753;
BA_ "SigType" SG_ 2362638078 LevelCtrlModeRq "DISCRETE";
BA_ "SPN" SG_ 2362638078 NominalLevelRqRearAxle 1750;
BA_ "SigType" SG_ 2362638078 NominalLevelRqRearAxle "DISCRETE";
BA_ "SPN" SG_ 2362638078 NominalLevelRqFrontAxle 1751;
BA_ "SigType" SG_ 2362638078 NominalLevelRqFrontAxle "DISCRETE";
BA_ "SPN" SG_ 2362638078 KneelingCtrlModeRq 1747;
BA_ "SigType" SG_ 2362638078 KneelingCtrlModeRq "DISCRETE";
BA_ "SPN" SG_ 2362638078 KneelingRqRightSide 1748;
BA_ "SigType" SG_ 2362638078 KneelingRqRightSide "DISCRETE";
BA_ "SPN" SG_ 2362638078 KneelingRqLeftSide 1749;
BA_ "SigType" SG_ 2362638078 KneelingRqLeftSide "DISCRETE";
BA_ "SPN" SG_ 2362638078 AutomaticTractionHelp 2984;
BA_ "SigType" SG_ 2362638078 AutomaticTractionHelp "DISCRETE";
BA_ "SPN" SG_ 2362638078 LiftAxle2PosCmd 1828;
BA_ "SigType" SG_ 2362638078 LiftAxle2PosCmd "DISCRETE";
BA_ "SPN" SG_ 2362638078 LiftAxle1PosCmd 1752;
BA_ "SigType" SG_ 2362638078 LiftAxle1PosCmd "DISCRETE";
BA_ "SPN" SG_ 2365479678 SspensionCtrlRefusalInformation 1827;
BA_ "SigType" SG_ 2365479678 SspensionCtrlRefusalInformation "DISCRETE";
BA_ "SPN" SG_ 2365479678 SuspensionRemoteCtrl2 1825;
BA_ "SigType" SG_ 2365479678 SuspensionRemoteCtrl2 "DISCRETE";
BA_ "SPN" SG_ 2365479678 SuspensionRemoteCtrl1 1826;
BA_ "SigType" SG_ 2365479678 SuspensionRemoteCtrl1 "DISCRETE";
BA_ "SPN" SG_ 2365479678 RearAxleInBumperRange 1823;
BA_ "SigType" SG_ 2365479678 RearAxleInBumperRange "DISCRETE";
BA_ "SPN" SG_ 2365479678 FrontAxleInBumperRange 1824;
BA_ "SigType" SG_ 2365479678 FrontAxleInBumperRange "DISCRETE";
BA_ "SPN" SG_ 2365479678 DoorRelease 1744;
BA_ "SigType" SG_ 2365479678 DoorRelease "DISCRETE";
BA_ "SPN" SG_ 2365479678 VehicleMotionInhibit 1745;
BA_ "SigType" SG_ 2365479678 VehicleMotionInhibit "DISCRETE";
BA_ "SPN" SG_ 2365479678 SecurityDevice 1746;
BA_ "SigType" SG_ 2365479678 SecurityDevice "DISCRETE";
BA_ "SPN" SG_ 2365479678 LevelCtrlMode 1741;
BA_ "SigType" SG_ 2365479678 LevelCtrlMode "DISCRETE";
BA_ "SPN" SG_ 2365479678 KneelingInformation 1742;
BA_ "SigType" SG_ 2365479678 KneelingInformation "DISCRETE";
BA_ "SPN" SG_ 2365479678 LiftingCtrlModeRearAxle 1756;
BA_ "SigType" SG_ 2365479678 LiftingCtrlModeRearAxle "DISCRETE";
BA_ "SPN" SG_ 2365479678 LiftingCtrlModeFrontAxle 1739;
BA_ "SigType" SG_ 2365479678 LiftingCtrlModeFrontAxle "DISCRETE";
BA_ "SPN" SG_ 2365479678 LoweringCtrlModeRearAxle 1755;
BA_ "SigType" SG_ 2365479678 LoweringCtrlModeRearAxle "DISCRETE";
BA_ "SPN" SG_ 2365479678 LoweringCtrlModeFrontAxle 1740;
BA_ "SigType" SG_ 2365479678 LoweringCtrlModeFrontAxle "DISCRETE";
BA_ "SPN" SG_ 2365479678 AboveNominalLevelRearAxle 1736;
BA_ "SigType" SG_ 2365479678 AboveNominalLevelRearAxle "DISCRETE";
BA_ "SPN" SG_ 2365479678 AboveNominalLevelFrontAxle 1737;
BA_ "SigType" SG_ 2365479678 AboveNominalLevelFrontAxle "DISCRETE";
BA_ "SPN" SG_ 2365479678 BelowNominalLevelRearAxle 1754;
BA_ "SigType" SG_ 2365479678 BelowNominalLevelRearAxle "DISCRETE";
BA_ "SPN" SG_ 2365479678 BelowNominalLevelFrontAxle 1738;
BA_ "SigType" SG_ 2365479678 BelowNominalLevelFrontAxle "DISCRETE";
BA_ "SPN" SG_ 2365479678 NominalLevelRearAxle 1733;
BA_ "SigType" SG_ 2365479678 NominalLevelRearAxle "DISCRETE";
BA_ "SPN" SG_ 2365479678 NominalLevelFrontAxle 1734;
BA_ "SigType" SG_ 2365479678 NominalLevelFrontAxle "DISCRETE";
BA_ "SPN" SG_ 2365479678 LiftAxle2Pos 1822;
BA_ "SigType" SG_ 2365479678 LiftAxle2Pos "DISCRETE";
BA_ "SPN" SG_ 2365479678 LiftAxle1Pos 1743;
BA_ "SigType" SG_ 2365479678 LiftAxle1Pos "DISCRETE";
BA_ "SPN" SG_ 2566837758 Alt4Status 3356;
BA_ "SigType" SG_ 2566837758 Alt4Status "DISCRETE";
BA_ "SPN" SG_ 2566837758 Alt3Status 3355;
BA_ "SigType" SG_ 2566837758 Alt3Status "DISCRETE";
BA_ "SPN" SG_ 2566837758 Alt2Status 3354;
BA_ "SigType" SG_ 2566837758 Alt2Status "DISCRETE";
BA_ "SPN" SG_ 2566837758 Alt1Status 3353;
BA_ "SigType" SG_ 2566837758 Alt1Status "DISCRETE";
BA_ "SPN" SG_ 2566837758 AltSpeed 589;
BA_ "SigType" SG_ 2566837758 AltSpeed "RANGE";
BA_ "SPN" SG_ 2633922558 AuxAbsPressReading 138;
BA_ "SigType" SG_ 2633922558 AuxAbsPressReading "RANGE";
BA_ "SPN" SG_ 2633922558 AuxGagePressReading1 137;
BA_ "SigType" SG_ 2633922558 AuxGagePressReading1 "RANGE";
BA_ "SPN" SG_ 2633922558 AuxVacuumPressReading 136;
BA_ "SigType" SG_ 2633922558 AuxVacuumPressReading "RANGE";
BA_ "SPN" SG_ 2566775038 SolarSensorMax 2611;
BA_ "SigType" SG_ 2566775038 SolarSensorMax "RANGE";
BA_ "SPN" SG_ 2566775038 SolarIntensityPercent 2610;
BA_ "SigType" SG_ 2566775038 SolarIntensityPercent "RANGE";
BA_ "SigType" SG_ 2633895166 IndustryGroup "DISCRETE";
BA_ "SigType" SG_ 2633895166 ManufacturerCode "RANGE";
BA_ "SPN" SG_ 2566836478 TestLimitMinimum 1228;
BA_ "SigType" SG_ 2566836478 TestLimitMinimum "RANGE";
BA_ "SPN" SG_ 2566836478 TestLimitMaximum 1227;
BA_ "SigType" SG_ 2566836478 TestLimitMaximum "RANGE";
BA_ "SPN" SG_ 2566836478 TestValue 1226;
BA_ "SigType" SG_ 2566836478 TestValue "RANGE";
BA_ "SPN" SG_ 2566836478 TestType 1225;
BA_ "SigType" SG_ 2566836478 TestType "RANGE";
BA_ "SPN" SG_ 2566836478 TestIdentifier 1224;
BA_ "SigType" SG_ 2566836478 TestIdentifier "RANGE";
BA_ "SPN" SG_ 2565078782 TestIdentifier 1224;
BA_ "SigType" SG_ 2565078782 TestIdentifier "RANGE";
BA_ "SPN" SG_ 2566836222 FlashRedStopLamp 3039;
BA_ "SPN" SG_ 2566836222 FlashProtectLamp 3041;
BA_ "SPN" SG_ 2566836222 FlashMalfuncIndicatorLamp 3038;
BA_ "SigType" SG_ 2566836222 FlashMalfuncIndicatorLamp "DISCRETE";
BA_ "SPN" SG_ 2566836222 FlashAmberWarningLamp 3040;
BA_ "SigType" SG_ 2566836222 OccurenceCount5 "RANGE";
BA_ "SigType" SG_ 2566836222 OccurenceCount4 "RANGE";
BA_ "SigType" SG_ 2566836222 OccurenceCount3 "RANGE";
BA_ "SigType" SG_ 2566836222 OccurenceCount2 "RANGE";
BA_ "SPN" SG_ 2566836222 OccurenceCount1 1216;
BA_ "SigType" SG_ 2566836222 OccurenceCount1 "RANGE";
BA_ "SPN" SG_ 2566836222 SPNConversionMethod1 1706;
BA_ "SPN" SG_ 2566836222 FailureModeIdentifier1 1215;
BA_ "SPN" SG_ 2566836222 SPN1 1214;
BA_ "SPN" SG_ 2566836222 MalfunctionIndicatorLampStatus 1213;
BA_ "SigType" SG_ 2566836222 MalfunctionIndicatorLampStatus "DISCRETE";
BA_ "SPN" SG_ 2566836222 RedStopLampState 623;
BA_ "SigType" SG_ 2566836222 RedStopLampState "DISCRETE";
BA_ "SPN" SG_ 2566836222 AmberWarningLampStatus 624;
BA_ "SigType" SG_ 2566836222 AmberWarningLampStatus "DISCRETE";
BA_ "SPN" SG_ 2566836222 ProtectLampStatus 987;
BA_ "SigType" SG_ 2566836222 ProtectLampStatus "DISCRETE";
BA_ "SPN" SG_ 2566836222 SPN1High 1214;
BA_ "SPN" SG_ 2566835966 MisfireMonitoringSupport 1221;
BA_ "SPN" SG_ 2566835966 OBDCompliance 1220;
BA_ "SigType" SG_ 2566835966 OBDCompliance "RANGE";
BA_ "SPN" SG_ 2566835966 PreviouslyActiveTroubleCodes 1219;
BA_ "SigType" SG_ 2566835966 PreviouslyActiveTroubleCodes "RANGE";
BA_ "SPN" SG_ 2566835966 ActiveTroubleCodes 1218;
BA_ "SigType" SG_ 2566835966 ActiveTroubleCodes "RANGE";
BA_ "SPN" SG_ 2566835966 SecondAirSystemMonStatus 1223;
BA_ "SPN" SG_ 2566835966 EvaporativeSystemMonStatus 1223;
BA_ "SPN" SG_ 2566835966 ACSystemRefrigerantMonStatus 1223;
BA_ "SPN" SG_ 2566835966 OxygenSensorHeaterMonStatus 1223;
BA_ "SPN" SG_ 2566835966 OxygenSensorMonStatus 1223;
BA_ "SPN" SG_ 2566835966 EGRSystemMonitoringStatus 1223;
BA_ "SPN" SG_ 2566835966 CatalystMonStatus 1223;
BA_ "SPN" SG_ 2566835966 ColdStartAidSystemMonStatus 1223;
BA_ "SPN" SG_ 2566835966 HeatedCatalystMonStatus 1223;
BA_ "SPN" SG_ 2566835966 CatalystMonSupp 1222;
BA_ "SPN" SG_ 2566835966 ColdStartAidSystemMonSupp 1222;
BA_ "SPN" SG_ 2566835966 HeatedCatalystMonSupp 1222;
BA_ "SPN" SG_ 2566835966 EvaporativeSystemMonSupp 1222;
BA_ "SPN" SG_ 2566835966 SecondAirSystemMonSupp 1222;
BA_ "SPN" SG_ 2566835966 ACSystemRefrigerantMonSupp 1222;
BA_ "SPN" SG_ 2566835966 OxygenSensorMonSupp 1222;
BA_ "SPN" SG_ 2566835966 OxygenSensorHeaterMonSupp 1222;
BA_ "SPN" SG_ 2566835966 EGRSystemMonitoringSupp 1222;
BA_ "SPN" SG_ 2566835966 MisfireMonitoringStatus 1221;
BA_ "SPN" SG_ 2566835966 ComprehensiveCompMonStatus 1221;
BA_ "SPN" SG_ 2566835966 FuelSystemMonitoringStatus 1221;
BA_ "SPN" SG_ 2566835966 ComprehensiveComponentMonSupp 1221;
BA_ "SPN" SG_ 2566835966 FuelSystemMonitoringSupport 1221;
BA_ "SPN" SG_ 2566835710 OccurenceCount1 1216;
BA_ "SigType" SG_ 2566835710 OccurenceCount1 "RANGE";
BA_ "SPN" SG_ 2566835710 SPNConversionMethod1 1706;
BA_ "SPN" SG_ 2566835710 FailureModeIdentifier1 1215;
BA_ "SPN" SG_ 2566835710 SPN1 1214;
BA_ "SPN" SG_ 2566835710 FreezeFrameLength 1217;
BA_ "SPN" SG_ 2566835710 EngSpeed 190;
BA_ "SigType" SG_ 2566835710 EngSpeed "RANGE";
BA_ "SPN" SG_ 2566835710 EngTorqueMode 899;
BA_ "SigType" SG_ 2566835710 EngTorqueMode "DISCRETE";
BA_ "SPN" SG_ 2566835710 EngTurboBoostPress 102;
BA_ "SigType" SG_ 2566835710 EngTurboBoostPress "RANGE";
BA_ "SPN" SG_ 2566835710 WheelBasedVehicleSpeed 84;
BA_ "SigType" SG_ 2566835710 WheelBasedVehicleSpeed "RANGE";
BA_ "SPN" SG_ 2566835710 EngPercentLoadAtCurrentSpeed 92;
BA_ "SigType" SG_ 2566835710 EngPercentLoadAtCurrentSpeed "RANGE";
BA_ "SPN" SG_ 2566835710 EngineCoolantTemperature 110;
BA_ "SigType" SG_ 2566835710 EngineCoolantTemperature "RANGE";
BA_ "SPN" SG_ 2566835710 SPN1High 1214;
BA_ "SPN" SG_ 2566764542 OccurenceCount1 1216;
BA_ "SigType" SG_ 2566764542 OccurenceCount1 "RANGE";
BA_ "SPN" SG_ 2566764542 SPNConversionMethod1 1706;
BA_ "SPN" SG_ 2566764542 FailureModeIdentifier1 1215;
BA_ "SPN" SG_ 2566764542 SPN1 1214;
BA_ "SPN" SG_ 2566764542 ExpandedFreezeFrameLength 3149;
BA_ "SPN" SG_ 2566764542 SPN1High 1214;
BA_ "SPN" SG_ 2566764286 SPNSupported1High 3146;
BA_ "SPN" SG_ 2566764286 SPNSupported3High 3146;
BA_ "SPN" SG_ 2566764286 SPNSupported2High 3146;
BA_ "SPN" SG_ 2566764286 SPNSupported3 3146;
BA_ "SPN" SG_ 2566764286 SPNSupported2 3146;
BA_ "SPN" SG_ 2566764286 SPNDataLength3 3148;
BA_ "SPN" SG_ 2566764286 SPNDataLength2 3148;
BA_ "SPN" SG_ 2566764286 SPNDataLength1 3148;
BA_ "SPN" SG_ 2566764286 SPNSupported1 3146;
BA_ "SPN" SG_ 2555576062 FlashRedStopLamp 3039;
BA_ "SPN" SG_ 2555576062 FlashProtectLamp 3041;
BA_ "SPN" SG_ 2555576062 FlashMalfuncIndicatorLamp 3038;
BA_ "SigType" SG_ 2555576062 FlashMalfuncIndicatorLamp "DISCRETE";
BA_ "SPN" SG_ 2555576062 FlashAmberWarningLamp 3040;
BA_ "SPN" SG_ 2555576062 OccurenceCount1 1216;
BA_ "SigType" SG_ 2555576062 OccurenceCount1 "RANGE";
BA_ "SPN" SG_ 2555576062 SPNConversionMethod1 1706;
BA_ "SPN" SG_ 2555576062 FailureModeIdentifier1 1215;
BA_ "SPN" SG_ 2555576062 SPN1 1214;
BA_ "SPN" SG_ 2555576062 MalfunctionIndicatorLampStatus 1213;
BA_ "SigType" SG_ 2555576062 MalfunctionIndicatorLampStatus "DISCRETE";
BA_ "SPN" SG_ 2555576062 RedStopLampState 623;
BA_ "SigType" SG_ 2555576062 RedStopLampState "DISCRETE";
BA_ "SPN" SG_ 2555576062 AmberWarningLampStatus 624;
BA_ "SigType" SG_ 2555576062 AmberWarningLampStatus "DISCRETE";
BA_ "SPN" SG_ 2555576062 ProtectLampStatus 987;
BA_ "SigType" SG_ 2555576062 ProtectLampStatus "DISCRETE";
BA_ "SigType" SG_ 2555576062 OccurenceCount5 "RANGE";
BA_ "SigType" SG_ 2555576062 OccurenceCount4 "RANGE";
BA_ "SigType" SG_ 2555576062 OccurenceCount3 "RANGE";
BA_ "SigType" SG_ 2555576062 OccurenceCount2 "RANGE";
BA_ "SPN" SG_ 2555576062 SPN1High 1214;
BA_ "SPN" SG_ 2562981630 IndividualDTCClearControlByte 3034;
BA_ "SPN" SG_ 2562981630 CtrlByteIndicIndividualDTCClear 3035;
BA_ "SPN" SG_ 2562981630 SPN1 1214;
BA_ "SPN" SG_ 2562981630 SPN1High 1214;
BA_ "SPN" SG_ 2562981630 FailureModeIdentifier1 1215;
BA_ "SPN" SG_ 2562850558 TimeSinceDTCsCleared 3145;
BA_ "SigType" SG_ 2562850558 TimeSinceDTCsCleared "RANGE";
BA_ "SPN" SG_ 2562850558 MinutesRunByEngineMILActivated 3144;
BA_ "SigType" SG_ 2562850558 MinutesRunByEngineMILActivated "RANGE";
BA_ "SPN" SG_ 2562850558 DistanceSinceDTCsCleared 3143;
BA_ "SigType" SG_ 2562850558 DistanceSinceDTCsCleared "RANGE";
BA_ "SPN" SG_ 2562850558 DistanceWhileMILisActivated 3069;
BA_ "SigType" SG_ 2562850558 DistanceWhileMILisActivated "RANGE";
BA_ "SPN" SG_ 2562916094 ApplSysMonitorDenominator 3068;
BA_ "SigType" SG_ 2562916094 ApplSysMonitorDenominator "RANGE";
BA_ "SPN" SG_ 2562916094 ApplSysMonitorNumerator 3067;
BA_ "SigType" SG_ 2562916094 ApplSysMonitorNumerator "RANGE";
BA_ "SPN" SG_ 2562916094 SPNofApplSysMonitor 3066;
BA_ "SigType" SG_ 2562916094 SPNofApplSysMonitor "RANGE";
BA_ "SPN" SG_ 2562916094 OBDMonitoringCondEncountered 3049;
BA_ "SigType" SG_ 2562916094 OBDMonitoringCondEncountered "RANGE";
BA_ "SPN" SG_ 2562916094 IgnitionCycleCounter 3048;
BA_ "SigType" SG_ 2562916094 IgnitionCycleCounter "RANGE";
BA_ "SPN" SG_ 2566835198 OccurenceCount1 1216;
BA_ "SigType" SG_ 2566835198 OccurenceCount1 "RANGE";
BA_ "SPN" SG_ 2566835198 SPNConversionMethod1 1706;
BA_ "SPN" SG_ 2566835198 FailureModeIdentifier1 1215;
BA_ "SPN" SG_ 2566835198 SPN1 1214;
BA_ "SPN" SG_ 2566835198 MalfunctionIndicatorLampStatus 1213;
BA_ "SigType" SG_ 2566835198 MalfunctionIndicatorLampStatus "DISCRETE";
BA_ "SPN" SG_ 2566835198 RedStopLampState 623;
BA_ "SigType" SG_ 2566835198 RedStopLampState "DISCRETE";
BA_ "SPN" SG_ 2566835198 AmberWarningLampStatus 624;
BA_ "SigType" SG_ 2566835198 AmberWarningLampStatus "DISCRETE";
BA_ "SPN" SG_ 2566835198 ProtectLampStatus 987;
BA_ "SigType" SG_ 2566835198 ProtectLampStatus "DISCRETE";
BA_ "SPN" SG_ 2566835198 FlashRedStopLamp 3039;
BA_ "SPN" SG_ 2566835198 FlashProtectLamp 3041;
BA_ "SPN" SG_ 2566835198 FlashMalfuncIndicatorLamp 3038;
BA_ "SigType" SG_ 2566835198 FlashMalfuncIndicatorLamp "DISCRETE";
BA_ "SPN" SG_ 2566835198 FlashAmberWarningLamp 3040;
BA_ "SigType" SG_ 2566835198 OccurenceCount5 "RANGE";
BA_ "SigType" SG_ 2566835198 OccurenceCount4 "RANGE";
BA_ "SigType" SG_ 2566835198 OccurenceCount3 "RANGE";
BA_ "SigType" SG_ 2566835198 OccurenceCount2 "RANGE";
BA_ "SPN" SG_ 2566835198 SPN1High 1214;
BA_ "SPN" SG_ 2564030206 CalibrationID4 1635;
BA_ "SPN" SG_ 2564030206 CalibrationID3 1635;
BA_ "SPN" SG_ 2564030206 CalibrationID2 1635;
BA_ "SPN" SG_ 2564030206 CalibrationID1 1635;
BA_ "SPN" SG_ 2564030206 CalibrationVerificationNumber 1634;
BA_ "SigType" SG_ 2564030206 CalibrationVerificationNumber "RANGE";
BA_ "SPN" SG_ 2564423422 KeyOrUserLevel 1645;
BA_ "SPN" SG_ 2564423422 PointerExtension 1643;
BA_ "SPN" SG_ 2564423422 Pointer 1644;
BA_ "SPN" SG_ 2564423422 Command 1642;
BA_ "SPN" SG_ 2564423422 PointerType 1641;
BA_ "SPN" SG_ 2564423422 NumberRequested 1640;
BA_ "SPN" SG_ 2564423422 NumberRequestedHigh 1640;
BA_ "SPN" SG_ 2564816638 HoldSignal 1236;
BA_ "SigType" SG_ 2564816638 HoldSignal "DISCRETE";
BA_ "SPN" SG_ 2564816638 J1939Network3 1235;
BA_ "SigType" SG_ 2564816638 J1939Network3 "DISCRETE";
BA_ "SPN" SG_ 2564816638 J1939Network2 1231;
BA_ "SigType" SG_ 2564816638 J1939Network2 "DISCRETE";
BA_ "SPN" SG_ 2564816638 ISO9141 1232;
BA_ "SigType" SG_ 2564816638 ISO9141 "DISCRETE";
BA_ "SPN" SG_ 2564816638 SAE_J1850 1233;
BA_ "SigType" SG_ 2564816638 SAE_J1850 "DISCRETE";
BA_ "SPN" SG_ 2564816638 ManufacturerSpecificPort 1234;
BA_ "SigType" SG_ 2564816638 ManufacturerSpecificPort "DISCRETE";
BA_ "SPN" SG_ 2564816638 CurrentDataLink 1230;
BA_ "SigType" SG_ 2564816638 CurrentDataLink "DISCRETE";
BA_ "SPN" SG_ 2564816638 SAE_J1587 608;
BA_ "SigType" SG_ 2564816638 SAE_J1587 "DISCRETE";
BA_ "SPN" SG_ 2564816638 SAE_J1922 622;
BA_ "SigType" SG_ 2564816638 SAE_J1922 "DISCRETE";
BA_ "SPN" SG_ 2564816638 J1939Network1 639;
BA_ "SigType" SG_ 2564816638 J1939Network1 "DISCRETE";
BA_ "SPN" SG_ 2564816638 SuspendSignal 2618;
BA_ "SPN" SG_ 2564816638 SuspendDuration 2619;
BA_ "SPN" SG_ 2566837502 FlashRedStopLamp 3039;
BA_ "SPN" SG_ 2566837502 FlashProtectLamp 3041;
BA_ "SPN" SG_ 2566837502 OccurenceCount1 1216;
BA_ "SigType" SG_ 2566837502 OccurenceCount1 "RANGE";
BA_ "SPN" SG_ 2566837502 SPNConversionMethod1 1706;
BA_ "SPN" SG_ 2566837502 FailureModeIdentifier1 1215;
BA_ "SPN" SG_ 2566837502 SPN1 1214;
BA_ "SPN" SG_ 2566837502 MalfunctionIndicatorLampStatus 1213;
BA_ "SigType" SG_ 2566837502 MalfunctionIndicatorLampStatus "DISCRETE";
BA_ "SPN" SG_ 2566837502 RedStopLampState 623;
BA_ "SigType" SG_ 2566837502 RedStopLampState "DISCRETE";
BA_ "SPN" SG_ 2566837502 AmberWarningLampStatus 624;
BA_ "SigType" SG_ 2566837502 AmberWarningLampStatus "DISCRETE";
BA_ "SPN" SG_ 2566837502 ProtectLampStatus 987;
BA_ "SigType" SG_ 2566837502 ProtectLampStatus "DISCRETE";
BA_ "SPN" SG_ 2566837502 FlashMalfuncIndicatorLamp 3038;
BA_ "SigType" SG_ 2566837502 FlashMalfuncIndicatorLamp "DISCRETE";
BA_ "SPN" SG_ 2566837502 FlashAmberWarningLamp 3040;
BA_ "SigType" SG_ 2566837502 OccurenceCount5 "RANGE";
BA_ "SigType" SG_ 2566837502 OccurenceCount4 "RANGE";
BA_ "SigType" SG_ 2566837502 OccurenceCount3 "RANGE";
BA_ "SigType" SG_ 2566837502 OccurenceCount2 "RANGE";
BA_ "SPN" SG_ 2566837502 SPN1High 1214;
BA_ "SPN" SG_ 2566836990 TestIdentifierSupported 1229;
BA_ "SigType" SG_ 2566836990 TestIdentifierSupported "RANGE";
BA_ "SPN" SG_ 2566834942 FlashRedStopLamp 3039;
BA_ "SPN" SG_ 2566834942 FlashProtectLamp 3041;
BA_ "SPN" SG_ 2566834942 FlashMalfuncIndicatorLamp 3038;
BA_ "SigType" SG_ 2566834942 FlashMalfuncIndicatorLamp "DISCRETE";
BA_ "SPN" SG_ 2566834942 FlashAmberWarningLamp 3040;
BA_ "SPN" SG_ 2566834942 MalfunctionIndicatorLampStatus 1213;
BA_ "SigType" SG_ 2566834942 MalfunctionIndicatorLampStatus "DISCRETE";
BA_ "SPN" SG_ 2566834942 AmberWarningLampStatus 624;
BA_ "SigType" SG_ 2566834942 AmberWarningLampStatus "DISCRETE";
BA_ "SPN" SG_ 2566834942 OccurenceCount1 1216;
BA_ "SigType" SG_ 2566834942 OccurenceCount1 "RANGE";
BA_ "SPN" SG_ 2566834942 SPNConversionMethod1 1706;
BA_ "SPN" SG_ 2566834942 FailureModeIdentifier1 1215;
BA_ "SPN" SG_ 2566834942 SPN1 1214;
BA_ "SPN" SG_ 2566834942 RedStopLampState 623;
BA_ "SigType" SG_ 2566834942 RedStopLampState "DISCRETE";
BA_ "SPN" SG_ 2566834942 ProtectLampStatus 987;
BA_ "SigType" SG_ 2566834942 ProtectLampStatus "DISCRETE";
BA_ "SigType" SG_ 2566834942 OccurenceCount5 "RANGE";
BA_ "SigType" SG_ 2566834942 OccurenceCount4 "RANGE";
BA_ "SigType" SG_ 2566834942 OccurenceCount3 "RANGE";
BA_ "SigType" SG_ 2566834942 OccurenceCount2 "RANGE";
BA_ "SPN" SG_ 2566834942 SPN1High 1214;
BA_ "SPN" SG_ 2566780926 UtlityOverallPowerFactorLagging 2522;
BA_ "SigType" SG_ 2566780926 UtlityOverallPowerFactorLagging "DISCRETE";
BA_ "SPN" SG_ 2566780926 UtilityOverallPowerFactor 2498;
BA_ "SigType" SG_ 2566780926 UtilityOverallPowerFactor "RANGE";
BA_ "SPN" SG_ 2566780926 UtilityTotalReactivePower 2490;
BA_ "SigType" SG_ 2566780926 UtilityTotalReactivePower "RANGE";
BA_ "SPN" SG_ 2566781182 UtilityTotalApparentPower 2494;
BA_ "SigType" SG_ 2566781182 UtilityTotalApparentPower "RANGE";
BA_ "SPN" SG_ 2566781182 UtilityTotalRealPower 2486;
BA_ "SigType" SG_ 2566781182 UtilityTotalRealPower "RANGE";
BA_ "SPN" SG_ 2566778366 UtilityTotalKWHoursImport 2503;
BA_ "SigType" SG_ 2566778366 UtilityTotalKWHoursImport "DISCRETE";
BA_ "SPN" SG_ 2566778366 UtilityTotalKWHoursExport 2502;
BA_ "SigType" SG_ 2566778366 UtilityTotalKWHoursExport "DISCRETE";
BA_ "SPN" SG_ 2566778622 UtilityPhaseCPowerFactorLagging 2525;
BA_ "SigType" SG_ 2566778622 UtilityPhaseCPowerFactorLagging "DISCRETE";
BA_ "SPN" SG_ 2566778622 UtilityPhaseCPowerFactor 2501;
BA_ "SigType" SG_ 2566778622 UtilityPhaseCPowerFactor "RANGE";
BA_ "SPN" SG_ 2566778622 UtilityPhaseCReactivePower 2493;
BA_ "SigType" SG_ 2566778622 UtilityPhaseCReactivePower "RANGE";
BA_ "SPN" SG_ 2566778878 UtilityPhaseCApparentPower 2497;
BA_ "SigType" SG_ 2566778878 UtilityPhaseCApparentPower "RANGE";
BA_ "SPN" SG_ 2566778878 UtilityPhaseCRealPower 2489;
BA_ "SigType" SG_ 2566778878 UtilityPhaseCRealPower "RANGE";
BA_ "SPN" SG_ 2566779134 UtilityPhaseCACRMSCurrent 2485;
BA_ "SigType" SG_ 2566779134 UtilityPhaseCACRMSCurrent "RANGE";
BA_ "SPN" SG_ 2566779134 UtilityPhaseCACFrequency 2473;
BA_ "SigType" SG_ 2566779134 UtilityPhaseCACFrequency "RANGE";
BA_ "SPN" SG_ 2566779134 UtltyPhsCLneNeutralACRMSVoltage 2481;
BA_ "SigType" SG_ 2566779134 UtltyPhsCLneNeutralACRMSVoltage "RANGE";
BA_ "SPN" SG_ 2566779134 UtltyPhseCALineLineACRMSVoltage 2477;
BA_ "SigType" SG_ 2566779134 UtltyPhseCALineLineACRMSVoltage "RANGE";
BA_ "SPN" SG_ 2566779390 UtilityPhaseBPowerFactorLagging 2524;
BA_ "SigType" SG_ 2566779390 UtilityPhaseBPowerFactorLagging "DISCRETE";
BA_ "SPN" SG_ 2566779390 UtilityPhaseBPowerFactor 2500;
BA_ "SigType" SG_ 2566779390 UtilityPhaseBPowerFactor "RANGE";
BA_ "SPN" SG_ 2566779390 UtilityPhaseBReactivePower 2492;
BA_ "SigType" SG_ 2566779390 UtilityPhaseBReactivePower "RANGE";
BA_ "SPN" SG_ 2566779646 UtilityPhaseBApparentPower 2496;
BA_ "SigType" SG_ 2566779646 UtilityPhaseBApparentPower "RANGE";
BA_ "SPN" SG_ 2566779646 UtilityPhaseBRealPower 2488;
BA_ "SigType" SG_ 2566779646 UtilityPhaseBRealPower "RANGE";
BA_ "SPN" SG_ 2566779902 UtilityPhaseBACRMSCurrent 2484;
BA_ "SigType" SG_ 2566779902 UtilityPhaseBACRMSCurrent "RANGE";
BA_ "SPN" SG_ 2566779902 UtilityPhaseBACFrequency 2472;
BA_ "SigType" SG_ 2566779902 UtilityPhaseBACFrequency "RANGE";
BA_ "SPN" SG_ 2566779902 UtltyPhsBLneNeutralACRMSVoltage 2480;
BA_ "SigType" SG_ 2566779902 UtltyPhsBLneNeutralACRMSVoltage "RANGE";
BA_ "SPN" SG_ 2566779902 UtltyPhseBCLineLineACRMSVoltage 2476;
BA_ "SigType" SG_ 2566779902 UtltyPhseBCLineLineACRMSVoltage "RANGE";
BA_ "SPN" SG_ 2566780158 UtilityPhaseAPowerFactorLagging 2523;
BA_ "SigType" SG_ 2566780158 UtilityPhaseAPowerFactorLagging "DISCRETE";
BA_ "SPN" SG_ 2566780158 UtilityPhaseAPowerFactor 2499;
BA_ "SigType" SG_ 2566780158 UtilityPhaseAPowerFactor "RANGE";
BA_ "SPN" SG_ 2566780158 UtilityPhaseAReactivePower 2491;
BA_ "SigType" SG_ 2566780158 UtilityPhaseAReactivePower "RANGE";
BA_ "SPN" SG_ 2566780414 UtilityPhaseAApparentPower 2495;
BA_ "SigType" SG_ 2566780414 UtilityPhaseAApparentPower "RANGE";
BA_ "SPN" SG_ 2566780414 UtilityPhaseARealPower 2487;
BA_ "SigType" SG_ 2566780414 UtilityPhaseARealPower "RANGE";
BA_ "SPN" SG_ 2566780670 UtilityPhaseAACRMSCurrent 2483;
BA_ "SigType" SG_ 2566780670 UtilityPhaseAACRMSCurrent "RANGE";
BA_ "SPN" SG_ 2566780670 UtilityPhaseAACFrequency 2471;
BA_ "SigType" SG_ 2566780670 UtilityPhaseAACFrequency "RANGE";
BA_ "SPN" SG_ 2566780670 UtltyPhsALneNeutralACRMSVoltage 2479;
BA_ "SigType" SG_ 2566780670 UtltyPhsALneNeutralACRMSVoltage "RANGE";
BA_ "SPN" SG_ 2566780670 UtltyPhseABLineLineACRMSVoltage 2475;
BA_ "SigType" SG_ 2566780670 UtltyPhseABLineLineACRMSVoltage "RANGE";
BA_ "SPN" SG_ 2566781438 UtilityAverageACRMSCurrent 2482;
BA_ "SigType" SG_ 2566781438 UtilityAverageACRMSCurrent "RANGE";
BA_ "SPN" SG_ 2566781438 UtilityAverageACFrequency 2470;
BA_ "SigType" SG_ 2566781438 UtilityAverageACFrequency "RANGE";
BA_ "SPN" SG_ 2566781438 UtltyAvrgLneNeutralACRMSVoltage 2478;
BA_ "SigType" SG_ 2566781438 UtltyAvrgLneNeutralACRMSVoltage "RANGE";
BA_ "SPN" SG_ 2566781438 UtltyAvrageLineLineACRMSVoltage 2474;
BA_ "SigType" SG_ 2566781438 UtltyAvrageLineLineACRMSVoltage "RANGE";
BA_ "SPN" SG_ 2566784254 GnrtorOverallPowerFactorLagging 2518;
BA_ "SigType" SG_ 2566784254 GnrtorOverallPowerFactorLagging "DISCRETE";
BA_ "SPN" SG_ 2566784254 GeneratorOverallPowerFactor 2464;
BA_ "SigType" SG_ 2566784254 GeneratorOverallPowerFactor "RANGE";
BA_ "SPN" SG_ 2566784254 GeneratorTotalReactivePower 2456;
BA_ "SigType" SG_ 2566784254 GeneratorTotalReactivePower "RANGE";
BA_ "SPN" SG_ 2566784510 GeneratorTotalApparentPower 2460;
BA_ "SigType" SG_ 2566784510 GeneratorTotalApparentPower "RANGE";
BA_ "SPN" SG_ 2566784510 GeneratorTotalRealPower 2452;
BA_ "SigType" SG_ 2566784510 GeneratorTotalRealPower "RANGE";
VAL_ 2566844926 ParkBrakeReleaseInhibitRq 3 "Unavailable" 2 "SAEReserved" 1 "ParkBrakeReleaseInhibitRqed" 0 "ParkBrakeReleaseInhibitNotRqed" ;
VAL_ 2566844926 EngShutdownOverrideSwitch 3 "NotAvailable" 2 "Error" 1 "On" 0 "Off" ;
VAL_ 2566844926 EngTestModeSwitch 3 "NotAvailable" 2 "Error" 1 "On" 0 "Off" ;
VAL_ 2566844926 EngIdleDecrementSwitch 3 "NotAvailable" 2 "Error" 1 "On" 0 "Off" ;
VAL_ 2566844926 EngIdleIncrementSwitch 3 "NotAvailable" 2 "Error" 1 "On" 0 "Off" ;
VAL_ 2566844926 CruiseCtrlAccelerateSwitch 3 "NotAvailable" 2 "Error" 1 "CrsCtrlActivatorInPosAccelerate" 0 "CrsCtrlActvtrNotInPosAccelerate" ;
VAL_ 2566844926 CruiseCtrlResumeSwitch 3 "NotAvailable" 2 "Error" 1 "CruiseCtrlActivatorInPosResume" 0 "CrseCtrlActivatorNotInPosResume" ;
VAL_ 2566844926 CruiseCtrlCoastSwitch 3 "NotAvailable" 2 "Error" 1 "CruiseCtrlActivatorInPosCoast" 0 "CriseCtrlActivatorNotInPosCoast" ;
VAL_ 2566844926 CruiseCtrlSetSwitch 3 "NotAvailable" 2 "Error" 1 "CruiseCtrlActivatorInPosSet" 0 "CruiseCtrlActivatorNotInPosSet" ;
VAL_ 2566844926 ClutchSwitch 3 "NotAvailable" 2 "Error" 1 "ClutchPedalDepressed" 0 "ClutchPedalReleased" ;
VAL_ 2566844926 BrakeSwitch 3 "NotAvailable" 2 "Error" 1 "BrakePedalDepressed" 0 "BrakePedalReleased" ;
VAL_ 2566844926 CruiseCtrlEnableSwitch 3 "NotAvailable" 2 "Error" 1 "CruiseCtrlEnabled" 0 "CruiseCtrlDisabled" ;
VAL_ 2566844926 CruiseCtrlActive 3 "NotAvailable" 2 "Error" 1 "CruiseCtrlSwitchedOn" 0 "CruiseCtrlSwitchedOff" ;
VAL_ 2566844926 CruiseCtrlPauseSwitch 3 "TakeNoAction" 2 "ErrorIndicator" 1 "On" 0 "Off" ;
VAL_ 2566844926 ParkingBrakeSwitch 3 "NotAvailable" 2 "Error" 1 "ParkingBrakeSet" 0 "ParkingBrakeNotSet" ;
VAL_ 2566844926 TwoSpeedAxleSwitch 3 "NotAvailable" 2 "Error" 1 "HighSpeedRange" 0 "LowSpeedRange" ;
VAL_ 2566809342 BatteryMainSwitchHoldState 3 "DontCare_TakeNoAction" 2 "Reserved" 1 "BatteryMainSwitchHeld" 0 "BatteryMainSwitchNotHeld" ;
VAL_ 2365446910 Joystick3XAxisDetentPosStatus 3 "NotAvailable" 2 "ErrorIndicator" 1 "InDetentPos" 0 "NotInDetentPos" ;
VAL_ 2365446910 Joystick3Button9PressedStatus 3 "NotAvailable" 2 "ErrorIndicator" 1 "ButtonPressed" 0 "ButtonNotPressed" ;
VAL_ 2365446910 Joystick3Button10PressedStatus 3 "NotAvailable" 2 "ErrorIndicator" 1 "ButtonPressed" 0 "ButtonNotPressed" ;
VAL_ 2365446910 Joystick3Button11PressedStatus 3 "NotAvailable" 2 "ErrorIndicator" 1 "ButtonPressed" 0 "ButtonNotPressed" ;
VAL_ 2365446910 Joystick3Button12PressedStatus 3 "NotAvailable" 2 "ErrorIndicator" 1 "ButtonPressed" 0 "ButtonNotPressed" ;
VAL_ 2365446910 Joystick3YAxisDetentPosStatus 3 "NotAvailable" 2 "ErrorIndicator" 1 "InDetentPos" 0 "NotInDetentPos" ;
VAL_ 2365446910 Jystck3YAxsLvrFrwrdPstvPsStatus 3 "NotAvailable" 2 "ErrorIndicator" 1 "OnPositiveSideOfNeutral" 0 "NotOnPositiveSideOfNeutral" ;
VAL_ 2365446910 Jystck3YAxsLvrBckNgtvePosStatus 3 "NotAvailable" 2 "ErrorIndicator" 1 "OnNegativeSideOfNeutral" 0 "NotOnNegativeSideOfNeutral" ;
VAL_ 2365446910 Joystick3YAxisNeutralPosStatus 3 "NotAvailable" 2 "ErrorIndicator" 1 "InNeutralPos" 0 "NotInNeutralPos" ;
VAL_ 2365446910 Jystck3XAxsLvrRghtPstvPosStatus 3 "NotAvailable" 2 "ErrorIndicator" 1 "OnPositiveSideOfNeutral" 0 "NotOnPositiveSideOfNeutral" ;
VAL_ 2365446910 Jystck3XAxsLvrLftNgtvePosStatus 2 "ErrorIndicator" 1 "OnNegativeSideOfNeutral" 0 "NotOnNegativeSideOfNeutral" 3 "NotAvailable" ;
VAL_ 2365446910 Joystick3XAxisNeutralPosStatus 3 "NotAvailable" 2 "ErrorIndicator" 1 "InNeutralPos" 0 "NotInNeutralPos" ;
VAL_ 2365446910 Joystick3Button5PressedStatus 3 "NotAvailable" 2 "ErrorIndicator" 1 "ButtonPressed" 0 "ButtonNotPressed" ;
VAL_ 2365446910 Joystick3Button6PressedStatus 3 "NotAvailable" 2 "ErrorIndicator" 1 "ButtonPressed" 0 "ButtonNotPressed" ;
VAL_ 2365446910 Joystick3Button7PressedStatus 3 "NotAvailable" 2 "ErrorIndicator" 1 "ButtonPressed" 0 "ButtonNotPressed" ;
VAL_ 2365446910 Joystick3Button8PressedStatus 3 "NotAvailable" 2 "ErrorIndicator" 1 "ButtonPressed" 0 "ButtonNotPressed" ;
VAL_ 2365446910 Joystick3Button1PressedStatus 3 "NotAvailable" 2 "ErrorIndicator" 1 "ButtonPressed" 0 "ButtonNotPressed" ;
VAL_ 2365446910 Joystick3Button2PressedStatus 3 "NotAvailable" 2 "ErrorIndicator" 1 "ButtonPressed" 0 "ButtonNotPressed" ;
VAL_ 2365446910 Joystick3Button3PressedStatus 3 "NotAvailable" 2 "ErrorIndicator" 1 "ButtonPressed" 0 "ButtonNotPressed" ;
VAL_ 2365446910 Joystick3Button4PressedStatus 3 "NotAvailable" 2 "ErrorIndicator" 1 "ButtonPressed" 0 "ButtonNotPressed" ;
VAL_ 2365446398 Joystick2XAxisDetentPosStatus 3 "NotAvailable" 2 "ErrorIndicator" 1 "InDetentPos" 0 "NotInDetentPos" ;
VAL_ 2365446398 Joystick2YAxisDetentPosStatus 3 "NotAvailable" 2 "ErrorIndicator" 1 "InDetentPos" 0 "NotInDetentPos" ;
VAL_ 2365446398 Jystck2YAxsLvrFrwrdPstvPsStatus 3 "NotAvailable" 2 "ErrorIndicator" 1 "OnPositiveSideOfNeutral" 0 "NotOnPositiveSideOfNeutral" ;
VAL_ 2365446398 Jystck2YAxsLvrBckNgtvePosStatus 3 "NotAvailable" 2 "ErrorIndicator" 1 "OnNegativeSideOfNeutral" 0 "NotOnNegativeSideOfNeutral" ;
VAL_ 2365446398 Joystick2YAxisNeutralPosStatus 3 "NotAvailable" 2 "ErrorIndicator" 1 "InNeutralPos" 0 "NotInNeutralPos" ;
VAL_ 2365446398 Jystck2XAxsLvrRghtPstvPosStatus 3 "NotAvailable" 2 "ErrorIndicator" 1 "OnPositiveSideOfNeutral" 0 "NotOnPositiveSideOfNeutral" ;
VAL_ 2365446398 Jystck2XAxsLvrLftNgtvePosStatus 3 "NotAvailable" 2 "ErrorIndicator" 1 "OnNegativeSideOfNeutral" 0 "NotOnNegativeSideOfNeutral" ;
VAL_ 2365446398 Joystick2XAxisNeutralPosStatus 3 "NotAvailable" 2 "ErrorIndicator" 1 "InNeutralPos" 0 "NotInNeutralPos" ;
VAL_ 2365446398 Joystick2Button9PressedStatus 3 "NotAvailable" 2 "ErrorIndicator" 1 "ButtonPressed" 0 "ButtonNotPressed" ;
VAL_ 2365446398 Joystick2Button10PressedStatus 3 "NotAvailable" 2 "ErrorIndicator" 1 "ButtonPressed" 0 "ButtonNotPressed" ;
VAL_ 2365446398 Joystick2Button11PressedStatus 3 "NotAvailable" 2 "ErrorIndicator" 1 "ButtonPressed" 0 "ButtonNotPressed" ;
VAL_ 2365446398 Joystick2Button12PressedStatus 3 "NotAvailable" 2 "ErrorIndicator" 1 "ButtonPressed" 0 "ButtonNotPressed" ;
VAL_ 2365446398 Joystick2Button5PressedStatus 3 "NotAvailable" 2 "ErrorIndicator" 1 "ButtonPressed" 0 "ButtonNotPressed" ;
VAL_ 2365446398 Joystick2Button6PressedStatus 3 "NotAvailable" 2 "ErrorIndicator" 1 "ButtonPressed" 0 "ButtonNotPressed" ;
VAL_ 2365446398 Joystick2Button7PressedStatus 3 "NotAvailable" 2 "ErrorIndicator" 1 "ButtonPressed" 0 "ButtonNotPressed" ;
VAL_ 2365446398 Joystick2Button8PressedStatus 3 "NotAvailable" 2 "ErrorIndicator" 1 "ButtonPressed" 0 "ButtonNotPressed" ;
VAL_ 2365446398 Joystick2Button1PressedStatus 3 "NotAvailable" 2 "ErrorIndicator" 1 "ButtonPressed" 0 "ButtonNotPressed" ;
VAL_ 2365446398 Joystick2Button2PressedStatus 3 "NotAvailable" 2 "ErrorIndicator" 1 "ButtonPressed" 0 "ButtonNotPressed" ;
VAL_ 2365446398 Joystick2Button3PressedStatus 3 "NotAvailable" 2 "ErrorIndicator" 1 "ButtonPressed" 0 "ButtonNotPressed" ;
VAL_ 2365446398 Joystick2Button4PressedStatus 3 "NotAvailable" 2 "ErrorIndicator" 1 "ButtonPressed" 0 "ButtonNotPressed" ;
VAL_ 2365445886 Joystick1XAxisDetentPosStatus 3 "NotAvailable" 2 "ErrorIndicator" 1 "InDetentPos" 0 "NotInDetentPos" ;
VAL_ 2365445886 Joystick1YAxisDetentPosStatus 3 "NotAvailable" 2 "ErrorIndicator" 1 "InDetentPos" 0 "NotInDetentPos" ;
VAL_ 2365445886 Jystck1YAxsLvrFrwrdPstvPsStatus 1 "OnPositiveSideOfNeutral" 0 "NotOnPositiveSideOfNeutral" 3 "NotAvailable" 2 "ErrorIndicator" ;
VAL_ 2365445886 Jystck1YAxsLvrBckNgtvePosStatus 3 "NotAvailable" 2 "ErrorIndicator" 1 "OnNegativeSideOfNeutral" 0 "NotOnNegativeSideOfNeutral" ;
VAL_ 2365445886 Joystick1YAxisNeutralPosStatus 3 "NotAvailable" 2 "ErrorIndicator" 1 "InNeutralPos" 0 "NotInNeutralPos" ;
VAL_ 2365445886 Joystick1Button9PressedStatus 3 "NotAvailable" 2 "ErrorIndicator" 1 "ButtonPressed" 0 "ButtonNotPressed" ;
VAL_ 2365445886 Joystick1Button10PressedStatus 3 "NotAvailable" 2 "ErrorIndicator" 1 "ButtonPressed" 0 "ButtonNotPressed" ;
VAL_ 2365445886 Joystick1Button11PressedStatus 3 "NotAvailable" 2 "ErrorIndicator" 1 "ButtonPressed" 0 "ButtonNotPressed" ;
VAL_ 2365445886 Joystick1Button12PressedStatus 3 "NotAvailable" 2 "ErrorIndicator" 1 "ButtonPressed" 0 "ButtonNotPressed" ;
VAL_ 2365445886 Joystick1Button5PressedStatus 3 "NotAvailable" 2 "ErrorIndicator" 1 "ButtonPressed" 0 "ButtonNotPressed" ;
VAL_ 2365445886 Joystick1Button6PressedStatus 3 "NotAvailable" 2 "ErrorIndicator" 1 "ButtonPressed" 0 "ButtonNotPressed" ;
VAL_ 2365445886 Joystick1Button7PressedStatus 3 "NotAvailable" 2 "ErrorIndicator" 1 "ButtonPressed" 0 "ButtonNotPressed" ;
VAL_ 2365445886 Joystick1Button8PressedStatus 3 "NotAvailable" 2 "ErrorIndicator" 1 "ButtonPressed" 0 "ButtonNotPressed" ;
VAL_ 2365445886 Joystick1Button1PressedStatus 3 "NotAvailable" 2 "ErrorIndicator" 1 "ButtonPressed" 0 "ButtonNotPressed" ;
VAL_ 2365445886 Joystick1Button2PressedStatus 3 "NotAvailable" 2 "ErrorIndicator" 1 "ButtonPressed" 0 "ButtonNotPressed" ;
VAL_ 2365445886 Joystick1Button3PressedStatus 3 "NotAvailable" 2 "ErrorIndicator" 1 "ButtonPressed" 0 "ButtonNotPressed" ;
VAL_ 2365445886 Joystick1Button4PressedStatus 3 "NotAvailable" 2 "ErrorIndicator" 1 "ButtonPressed" 0 "ButtonNotPressed" ;
VAL_ 2365445886 Jystck1XAxsLvrRghtPstvPosStatus 3 "NotAvailable" 2 "ErrorIndicator" 1 "OnPositiveSideOfNeutral" 0 "NotOnPositiveSideOfNeutral" ;
VAL_ 2365445886 Jystck1XAxsLvrLftNgtvePosStatus 3 "NotAvailable" 2 "ErrorIndicator" 1 "OnNegativeSideOfNeutral" 0 "NotOnNegativeSideOfNeutral" ;
VAL_ 2365445886 Joystick1XAxisNeutralPosStatus 3 "NotAvailable" 2 "ErrorIndicator" 1 "InNeutralPos" 0 "NotInNeutralPos" ;
VAL_ 2566847230 ParkingBrakeRedWarningSignal 3 "TakeNoAction" 2 "Reserved" 1 "On" 0 "Off" ;
VAL_ 2566847230 ParkBrakeReleaseInhibitStatus 3 "Unavailable" 2 "Error" 1 "ParkBrakeReleaseIsInhibited" 0 "ParkBrakeReleaseIsNotInhibited" ;
VAL_ 2566847230 ParkingBrakeActuator 3 "NotAvailable" 2 "Error" 1 "ParkingBrakeActuatorActive" 0 "ParkingBrakeActuatorInactive" ;
VAL_ 2631728894 AntitheftComponentStatusStates 3 "NotDefined" 2 "BlckdThsSttIndctsThtALckUnlckCm" 1 "Locked" 0 "UnlckdThsSttIndctsThtCmpnntCnBS" ;
VAL_ 2631728894 AntthftEncryptnSdPrsntIndicator 3 "NotAvailable" 2 "Error" 1 "RandomNumberIsPresent" 0 "RandomNumberIsNotPresent" ;
VAL_ 2631728894 AntitheftModifyPwdStates 3 "Notvalid" 2 "EmptyOfPwdsThsSttIndctsThtCmpnn" 1 "FullofPwds" 0 "OkThsSttIndctsThtRqWsSccssfllyP" ;
VAL_ 2631728894 AntitheftPwdValidIndicator 3 "NotAvailable" 2 "Error" 1 "PwdIsAValidatedPassword" 0 "PwdIsNotAValidatedPassword" ;
VAL_ 2631794430 AntitheftCmdStates 6 "111NotDefined" 5 "Login" 4 "ChckSttsThsSttRprsntsARqTChckTS" 3 "LockorUnlock" 2 "ChngPwdThsSttRprsntsARqTCmpnntT" 1 "DeletePwd" 0 "AddPwdThsSttRprsntsARqTCmpnntTA" ;
VAL_ 2631794430 AntitheftDesiredExitModeStates 3 "NotAvailable" 2 "NotDefined" 1 "LockWhenKeyOff" 0 "LckUpnOprtrRqThsSttIsUsdTIndctT" ;
VAL_ 2631794430 AntthftEncryptonIndicatorStates 3 "NotAvailable" 2 "NotDefined" 1 "EncryptedCodePresent" 0 "EncryptnSdRqThsSttRprsntsARqstT" ;
VAL_ 2365478910 ElctrncShckAbsrbrCtrlMdLft_TgAxl 3 "NotAvailable" 2 "Error" 1 "NormalOperationDampersActive" 0 "NormalOperationDampersPassive" ;
VAL_ 2365478910 ElctrncShckAbsrbrCtrlMdRearAxle 3 "NotAvailable" 2 "Error" 1 "NormalOperationDampersActive" 0 "NormalOperationDampersPassive" ;
VAL_ 2365478910 ElctrncShckAbsrbrCtrlMdFrntAxle 3 "NotAvailable" 2 "Error" 1 "NormalOperationDampersActive" 0 "NormalOperationDampersPassive" ;
VAL_ 2362638078 ProhibitAirSuspensionCtrl 3 "NotAvailable" 2 "ErrorIndicator" 1 "RqProhibitAirSuspensionCtrl" 0 "NoRq" ;
VAL_ 2362638078 KneelingCmdRearAxle 3 "DontCare_TakeNoAction" 2 "Reserved" 1 "ActivateKneeling" 0 "DeactivateKneeling" ;
VAL_ 2362638078 KneelingCmdFrontAxle 3 "DontCare_TakeNoAction" 2 "Reserved" 1 "ActivateKneeling" 0 "DeactivateKneeling" ;
VAL_ 2362638078 LevelCtrlModeRq 15 "DontCare_TakeNoAction" 14 "Reserved" 9 "1101NotDefined" 8 "ExhaustBellows" 7 "TractionHelpLoadReduce" 6 "OptmmTrctn2IPrssAtThDrvnAxlIsCt" 5 "OptmmTrctn1IPrssAtThDrvnAxlIsCt" 4 "PrssRt2IRtBtwnThPrssrsAtThDrvnA" 3 "PrssRt1IRtBtwnThPrssrsAtThDrvnA" 2 "LdFxngIDrvnAxlnIsLddTAVlDfndByT" 1 "TrctnHlpIDrvnAxlIsLddTAMxVlGvnB" 0 "NrmlOprtnISystmPrfrmsAPrCtrlOfT" ;
VAL_ 2362638078 NominalLevelRqRearAxle 15 "DontCare_TakeNoAction" 14 "Reserved" 9 "1101NotDefined" 8 "StopLevelChange" 7 "LowerLevel" 6 "UpperLevel" 5 "CustomerLevel" 4 "PresetLevel" 3 "NormalLevel3" 2 "NormalLevel2" 1 "NormalLevel1" 0 "NoLevelRq" ;
VAL_ 2362638078 NominalLevelRqFrontAxle 15 "DontCare_TakeNoAction" 14 "Reserved" 9 "1101NotDefined" 8 "StopLevelChange" 7 "LowerLevel" 6 "UpperLevel" 5 "CustomerLevel" 4 "PresetLevel" 3 "NormalLevel3" 2 "NormalLevel2" 1 "NormalLevel1" 0 "NoLevelRq" ;
VAL_ 2362638078 KneelingCtrlModeRq 3 "DontCare_TakeNoAction" 2 "Reserved" 1 "ManuallyActuated" 0 "AutomaticallyActuated" ;
VAL_ 2362638078 KneelingRqRightSide 3 "DontCare_TakeNoAction" 2 "Reserved" 1 "KneelingRq" 0 "NoKneelingRq" ;
VAL_ 2362638078 KneelingRqLeftSide 3 "DontCare_TakeNoAction" 2 "Reserved" 1 "KneelingRq" 0 "NoKneelingRq" ;
VAL_ 2362638078 AutomaticTractionHelp 3 "DontCare" 2 "Reserved" 1 "EnableAutomaticTractionHelp" 0 "DisableAutomaticTractionHelp" ;
VAL_ 2362638078 LiftAxle2PosCmd 3 "DontCare_TakeNoAction" 2 "Reserved" 1 "LiftAxlePosUp_TagAxleUnladen" 0 "LiftAxlePosDown_TagAxleLaden" ;
VAL_ 2362638078 LiftAxle1PosCmd 3 "DontCare_TakeNoAction" 2 "Reserved" 1 "LiftAxlePosUp_TagAxleUnladen" 0 "LiftAxlePosDown_TagAxleLaden" ;
VAL_ 2365479678 SspensionCtrlRefusalInformation 7 "1101NotDefined" 15 "NotAvailable" 14 "Error" 6 "GnrlRjctINSpcifiedReasonApplies" 5 "BelowSpeedLimit" 4 "AboveSpeedLimit" 3 "BogieDiffNotLocked" 2 "WouldExceedAxleLoadLimit" 1 "AxleLoadLimitReached" 0 "ActualRqNotRefused" ;
VAL_ 2365479678 SuspensionRemoteCtrl2 3 "NotAvailable" 2 "Error" 1 "Active" 0 "NotActive" ;
VAL_ 2365479678 SuspensionRemoteCtrl1 3 "NotAvailable" 2 "Error" 1 "Active" 0 "NotActive" ;
VAL_ 2365479678 RearAxleInBumperRange 3 "NotAvailable" 2 "Error" 1 "ActualLevelWithinBumperRange" 0 "ActualLevelOutOfBumperRange" ;
VAL_ 2365479678 FrontAxleInBumperRange 3 "NotAvailable" 2 "Error" 1 "ActualLevelWithinBumperRange" 0 "ActualLevelOutOfBumperRange" ;
VAL_ 2365479678 DoorRelease 3 "NotAvailable" 2 "Error" 1 "DoorsMayBeOpened" 0 "DoorsMayNotBeOpened" ;
VAL_ 2365479678 VehicleMotionInhibit 3 "NotAvailable" 2 "Error" 1 "VehicleMotionIsInhibited" 0 "VehicleMayBeMoved" ;
VAL_ 2365479678 SecurityDevice 3 "NotAvailable" 2 "Error" 1 "Active" 0 "NotActive" ;
VAL_ 2365479678 LevelCtrlMode 10 "1101NotDefined" 15 "NotAvailable" 14 "Error" 9 "AirSuspensionCtrlProhibited" 8 "ExhstngBllwFnctnIBllwsArExhstdT" 7 "TractionHelpLoadReduce" 6 "OptmmTrctn2IPrssAtThDrvnAxlIsCt" 5 "OptmmTrctn1IPrssAtThDrvnAxlIsCt" 4 "PrssRt2IRtBtwnThPrssrsAtThDrvnA" 3 "PrssRt1IRtBtwnThPrssrsAtThDrvnA" 2 "LdFxngIDrvnAxlnIsLddTAVlDfndByT" 1 "TrctnHlpIDrvnAxlIsLddTAMxVlGvnB" 0 "NrmlOprtnISystmPrfrmsAPrCtrlOfT" ;
VAL_ 2365479678 KneelingInformation 15 "NotAvailable" 14 "Error" 5 "1101NotDefined" 4 "KneelingAborted" 3 "LiftingActive" 2 "KneelingLevelReached" 0 "NotActive" ;
VAL_ 2365479678 LiftingCtrlModeRearAxle 3 "NotAvailable" 2 "Error" 1 "LiftingActive" 0 "LiftingNotActive" ;
VAL_ 2365479678 LiftingCtrlModeFrontAxle 3 "NotAvailable" 2 "Error" 1 "LiftingActive" 0 "LiftingNotActive" ;
VAL_ 2365479678 LoweringCtrlModeRearAxle 3 "NotAvailable" 2 "Error" 1 "LoweringActive" 0 "LoweringNotActive" ;
VAL_ 2365479678 LoweringCtrlModeFrontAxle 3 "NotAvailable" 2 "Error" 1 "LoweringActive" 0 "LoweringNotActive" ;
VAL_ 2365479678 AboveNominalLevelRearAxle 3 "NotAvailable" 2 "Error" 1 "Above" 0 "NotAbove" ;
VAL_ 2365479678 AboveNominalLevelFrontAxle 3 "NotAvailable" 2 "Error" 1 "Above" 0 "NotAbove" ;
VAL_ 2365479678 BelowNominalLevelRearAxle 3 "NotAvailable" 2 "Error" 1 "Below" 0 "NotBelow" ;
VAL_ 2365479678 BelowNominalLevelFrontAxle 3 "NotAvailable" 2 "Error" 1 "Below" 0 "NotBelow" ;
VAL_ 2365479678 NominalLevelRearAxle 15 "NotAvailable" 14 "Error" 8 "1101NotDefined" 7 "LowerLevel" 6 "UpperLevel" 5 "CustomerLevel" 4 "PresetLevel" 3 "NormalLevel3" 2 "NormalLevel2" 1 "NormalLevel1" 0 "LevelNotSpecified" ;
VAL_ 2365479678 NominalLevelFrontAxle 15 "NotAvailable" 14 "Error" 8 "1101NotDefined" 7 "LowerLevel" 6 "UpperLevel" 5 "CustomerLevel" 4 "PresetLevel" 3 "NormalLevel3" 2 "NormalLevel2" 1 "NormalLevel1" 0 "LevelNotSpecified" ;
VAL_ 2365479678 LiftAxle2Pos 3 "NotAvailable" 2 "Error" 1 "LiftAxlePosUp_TagAxleUnladen" 0 "LiftAxlePosDown_TagAxleLaden" ;
VAL_ 2365479678 LiftAxle1Pos 3 "NotAvailable" 2 "Error" 1 "LiftAxlePosUp_TagAxleUnladen" 0 "LiftAxlePosDown_TagAxleLaden" ;
VAL_ 2566837758 Alt4Status 3 "notAvailable" 2 "error" 1 "Alt4Charging" 0 "Alt4NotCharging" ;
VAL_ 2566837758 Alt3Status 3 "notAvailable" 2 "error" 1 "Alt3Charging" 0 "Alt3NotCharging" ;
VAL_ 2566837758 Alt2Status 3 "notAvailable" 2 "error" 1 "Alt2Charging" 0 "Alt2NotCharging" ;
VAL_ 2566837758 Alt1Status 3 "notAvailable" 2 "error" 1 "Alt1Charging" 0 "Alt1NotCharging" ;
VAL_ 2633895166 IndustryGroup 7 "Reserve for SAE" 5 "IndustrialProcessCtrlStationary" 4 "Marine" 3 "Construction" 2 "Agricultural and Forestry" 1 "On-Highway" 0 "Global" ;
VAL_ 2566836222 FailureModeIdentifier5 31 "Not available" 19 "Received network data in error" 18 "Below normal (moderatels severe)" 17 "Below normal (least severe)" 16 "Above normal (moderately severe)" 15 "Above normal (least severe)" 14 "Special intstructions" 13 "Out of calibration" 12 "Bad intelligent device" 11 "Root cause not known" 10 "Abnormal rate of change" 9 "Abnormal update rate" 8 "Abnormal frequency" 7 "Mechanical system not responding" 6 "Current above normal" 5 "Current below normal" 4 "Voltage below normal" 3 "Voltage above normal" 2 "Data erratic" 1 "Below normal (most severe)" 0 "Above normal (most severe)" ;
VAL_ 2566836222 FailureModeIdentifier4 31 "Not available" 19 "Received network data in error" 18 "Below normal (moderatels severe)" 17 "Below normal (least severe)" 16 "Above normal (moderately severe)" 15 "Above normal (least severe)" 14 "Special intstructions" 13 "Out of calibration" 12 "Bad intelligent device" 11 "Root cause not known" 10 "Abnormal rate of change" 9 "Abnormal update rate" 8 "Abnormal frequency" 7 "Mechanical system not responding" 6 "Current above normal" 5 "Current below normal" 4 "Voltage below normal" 3 "Voltage above normal" 2 "Data erratic" 1 "Below normal (most severe)" 0 "Above normal (most severe)" ;
VAL_ 2566836222 FlashRedStopLamp 3 "Unavailable / Do Not Flash" 2 "Reserved" 1 "Fast Flash" 0 "Slow Flash" ;
VAL_ 2566836222 FlashProtectLamp 3 "Unavailable / Do Not Flash" 2 "Reserved" 1 "Fast Flash" 0 "Slow Flash" ;
VAL_ 2566836222 FlashMalfuncIndicatorLamp 3 "Unavailable / Do Not Flash" 2 "Reserved" 1 "Fast Flash" 0 "Slow Flash" ;
VAL_ 2566836222 FlashAmberWarningLamp 3 "Unavailable / Do Not Flash" 2 "Reserved" 1 "Fast Flash" 0 "Slow Flash" ;
VAL_ 2566836222 FailureModeIdentifier3 31 "Not available" 19 "Received network data in error" 18 "Below normal (moderatels severe)" 17 "Below normal (least severe)" 16 "Above normal (moderately severe)" 15 "Above normal (least severe)" 14 "Special intstructions" 13 "Out of calibration" 12 "Bad intelligent device" 11 "Root cause not known" 10 "Abnormal rate of change" 9 "Abnormal update rate" 8 "Abnormal frequency" 7 "Mechanical system not responding" 6 "Current above normal" 5 "Current below normal" 4 "Voltage below normal" 3 "Voltage above normal" 2 "Data erratic" 1 "Below normal (most severe)" 0 "Above normal (most severe)" ;
VAL_ 2566836222 FailureModeIdentifier2 31 "Not available" 19 "Received network data in error" 18 "Below normal (moderatels severe)" 17 "Below normal (least severe)" 16 "Above normal (moderately severe)" 15 "Above normal (least severe)" 14 "Special intstructions" 13 "Out of calibration" 12 "Bad intelligent device" 11 "Root cause not known" 10 "Abnormal rate of change" 9 "Abnormal update rate" 8 "Abnormal frequency" 7 "Mechanical system not responding" 6 "Current above normal" 5 "Current below normal" 4 "Voltage below normal" 3 "Voltage above normal" 2 "Data erratic" 1 "Below normal (most severe)" 0 "Above normal (most severe)" ;
VAL_ 2566836222 FailureModeIdentifier1 31 "Not available" 19 "Received network data in error" 18 "Below normal (moderatels severe)" 17 "Below normal (least severe)" 16 "Above normal (moderately severe)" 15 "Above normal (least severe)" 14 "Special intstructions" 13 "Out of calibration" 12 "Bad intelligent device" 11 "Root cause not known" 10 "Abnormal rate of change" 9 "Abnormal update rate" 8 "Abnormal frequency" 7 "Mechanical system not responding" 6 "Current above normal" 5 "Current below normal" 4 "Voltage below normal" 3 "Voltage above normal" 2 "Data erratic" 1 "Below normal (most severe)" 0 "Above normal (most severe)" ;
VAL_ 2566836222 MalfunctionIndicatorLampStatus 3 "Not available" 2 "Reserved" 1 "Lamp on" 0 "Lamp off" ;
VAL_ 2566836222 RedStopLampState 3 "Not available" 2 "Reserved" 1 "Lamp on" 0 "Lamp off" ;
VAL_ 2566836222 AmberWarningLampStatus 3 "Not available" 2 "Reserved" 1 "Lamp on" 0 "Lamp off" ;
VAL_ 2566836222 ProtectLampStatus 3 "Not available" 2 "Reserved" 1 "Lamp on" 0 "Lamp off" ;
VAL_ 2566835966 MisfireMonitoringSupport 3 "Not available" 2 "Reserved" 1 "test supported" 0 "test not supported" ;
VAL_ 2566835966 OBDCompliance 5 "Not intended to meet OBD II requ" 4 "OBD I" 3 "OBD and OBD II" 2 "OBD (Federal, EPA)" 1 "OBD II (California, ARB)" 0 "Reserver for assignment by SAE" ;
VAL_ 2566835966 SecondAirSystemMonStatus 1 "TestNotComplete" 0 "TestComplete" ;
VAL_ 2566835966 EvaporativeSystemMonStatus 1 "TestNotComplete" 0 "TestComplete" ;
VAL_ 2566835966 ACSystemRefrigerantMonStatus 1 "TestNotComplete" 0 "TestComplete" ;
VAL_ 2566835966 OxygenSensorHeaterMonStatus 1 "TestNotComplete" 0 "TestComplete" ;
VAL_ 2566835966 OxygenSensorMonStatus 1 "test not complete" 0 "test complete" ;
VAL_ 2566835966 EGRSystemMonitoringStatus 1 "TestNotComplete" 0 "TestComplete" ;
VAL_ 2566835966 CatalystMonStatus 0 "TestComplete" 1 "TestNotComplete" ;
VAL_ 2566835966 ColdStartAidSystemMonStatus 1 "TestNotComplete" 0 "TestComplete" ;
VAL_ 2566835966 HeatedCatalystMonStatus 1 "TestNotComplete" 0 "TestComplete" ;
VAL_ 2566835966 CatalystMonSupp 1 "TestSupported" 0 "TestNotSupported" ;
VAL_ 2566835966 ColdStartAidSystemMonSupp 1 "TestSupported" 0 "TestNotSupported" ;
VAL_ 2566835966 HeatedCatalystMonSupp 1 "TestSupported" 0 "TestNotSupported" ;
VAL_ 2566835966 EvaporativeSystemMonSupp 1 "TestSupported" 0 "TestNotSupported" ;
VAL_ 2566835966 SecondAirSystemMonSupp 1 "TestSupported" 0 "TestNotSupported" ;
VAL_ 2566835966 ACSystemRefrigerantMonSupp 1 "TestSupported" 0 "TestNotSupported" ;
VAL_ 2566835966 OxygenSensorMonSupp 1 "TestSupported" 0 "TestNotSupported" ;
VAL_ 2566835966 OxygenSensorHeaterMonSupp 1 "TestSupported" 0 "TestNotSupported" ;
VAL_ 2566835966 EGRSystemMonitoringSupp 1 "TestSupported" 0 "TestNotSupported" ;
VAL_ 2566835966 MisfireMonitoringStatus 1 "test not complete" 0 "test complete" ;
VAL_ 2566835966 ComprehensiveCompMonStatus 1 "test not complete" 0 "test complete" ;
VAL_ 2566835966 FuelSystemMonitoringStatus 1 "test not complete" 0 "test complete" ;
VAL_ 2566835966 ComprehensiveComponentMonSupp 3 "Not available" 2 "Reserved" 1 "test supported" 0 "test not supported" ;
VAL_ 2566835966 FuelSystemMonitoringSupport 1 "test supported" 0 "test not supported" ;
VAL_ 2566835710 FailureModeIdentifier1 31 "Not available" 19 "Received network data in error" 18 "Below normal (moderatels severe)" 17 "Below normal (least severe)" 16 "Above normal (moderately severe)" 15 "Above normal (least severe)" 14 "Special intstructions" 13 "Out of calibration" 12 "Bad intelligent device" 11 "Root cause not known" 10 "Abnormal rate of change" 9 "Abnormal update rate" 8 "Abnormal frequency" 7 "Mechanical system not responding" 6 "Current above normal" 5 "Current below normal" 4 "Voltage below normal" 3 "Voltage above normal" 2 "Data erratic" 1 "Below normal (most severe)" 0 "Above normal (most severe)" ;
VAL_ 2566835710 EngTorqueMode 15 "Not available" 11 "Remote accelerator" 10 "Braking system" 9 "High speed governor" 8 "Torque limiting" 7 "ABS control" 6 "Transmission control" 5 "ASR control" 4 "Road speed governor" 3 "PTO governor" 2 "Cruise control" 1 "Accelerator pedal/operator selec" 0 "Low idle governor/no request (de" ;
VAL_ 2566764542 FailureModeIdentifier1 31 "Not available" 19 "Received network data in error" 18 "Below normal (moderatels severe)" 17 "Below normal (least severe)" 16 "Above normal (moderately severe)" 15 "Above normal (least severe)" 14 "Special intstructions" 13 "Out of calibration" 12 "Bad intelligent device" 11 "Root cause not known" 10 "Abnormal rate of change" 9 "Abnormal update rate" 8 "Abnormal frequency" 7 "Mechanical system not responding" 6 "Current above normal" 5 "Current below normal" 4 "Voltage below normal" 3 "Voltage above normal" 2 "Data erratic" 1 "Below normal (most severe)" 0 "Above normal (most severe)" ;
VAL_ 2566764286 SPNSupportTypeSTR3 1 "SupportedInScaledTestResults" 0 "NotSupportedInScaledTestResults" ;
VAL_ 2566764286 SPNSupportTypeSTR2 1 "SupportedInScaledTestResults" 0 "NotSupportedInScaledTestResults" ;
VAL_ 2566764286 SPNSupportTypeEFF3 1 "SupportedInExFreezeFrame" 0 "NotSupportedInExFreezeFrame" ;
VAL_ 2566764286 SPNSupportTypeEFF2 1 "SupportedInExFreezeFrame" 0 "NotSupportedInExFreezeFrame" ;
VAL_ 2566764286 SPNSupportTypeDS3 1 "SupportedInDataStream" 0 "NotSupportedInDataStream" ;
VAL_ 2566764286 SPNSupportTypeDS2 1 "SupportedInDataStream" 0 "NotSupportedInDataStream" ;
VAL_ 2566764286 SPNSupportTypeSTR1 1 "SupportedInScaledTestResults" 0 "NotSupportedInScaledTestResults" ;
VAL_ 2566764286 SPNSupportTypeDS1 1 "SupportedInDataStream" 0 "NotSupportedInDataStream" ;
VAL_ 2566764286 SPNSupportTypeEFF1 1 "SupportedInExFreezeFrame" 0 "NotSupportedInExFreezeFrame" ;
VAL_ 2555576062 FlashRedStopLamp 3 "Unavailable / Do Not Flash" 2 "Reserved" 1 "Fast Flash" 0 "Slow Flash" ;
VAL_ 2555576062 FlashProtectLamp 3 "Unavailable / Do Not Flash" 2 "Reserved" 1 "Fast Flash" 0 "Slow Flash" ;
VAL_ 2555576062 FlashMalfuncIndicatorLamp 3 "Unavailable / Do Not Flash" 2 "Reserved" 1 "Fast Flash" 0 "Slow Flash" ;
VAL_ 2555576062 FlashAmberWarningLamp 3 "Unavailable / Do Not Flash" 2 "Reserved" 1 "Fast Flash" 0 "Slow Flash" ;
VAL_ 2555576062 FailureModeIdentifier5 31 "Not available" 19 "Received network data in error" 18 "Below normal (moderatels severe)" 17 "Below normal (least severe)" 16 "Above normal (moderately severe)" 15 "Above normal (least severe)" 14 "Special intstructions" 13 "Out of calibration" 12 "Bad intelligent device" 11 "Root cause not known" 10 "Abnormal rate of change" 9 "Abnormal update rate" 8 "Abnormal frequency" 7 "Mechanical system not responding" 6 "Current above normal" 5 "Current below normal" 4 "Voltage below normal" 3 "Voltage above normal" 2 "Data erratic" 1 "Below normal (most severe)" 0 "Above normal (most severe)" ;
VAL_ 2555576062 FailureModeIdentifier4 31 "Not available" 19 "Received network data in error" 18 "Below normal (moderatels severe)" 17 "Below normal (least severe)" 16 "Above normal (moderately severe)" 15 "Above normal (least severe)" 14 "Special intstructions" 13 "Out of calibration" 12 "Bad intelligent device" 11 "Root cause not known" 10 "Abnormal rate of change" 9 "Abnormal update rate" 8 "Abnormal frequency" 7 "Mechanical system not responding" 6 "Current above normal" 5 "Current below normal" 4 "Voltage below normal" 3 "Voltage above normal" 2 "Data erratic" 1 "Below normal (most severe)" 0 "Above normal (most severe)" ;
VAL_ 2555576062 FailureModeIdentifier1 31 "Not available" 19 "Received network data in error" 18 "Below normal (moderatels severe)" 17 "Below normal (least severe)" 16 "Above normal (moderately severe)" 15 "Above normal (least severe)" 14 "Special intstructions" 13 "Out of calibration" 12 "Bad intelligent device" 11 "Root cause not known" 10 "Abnormal rate of change" 9 "Abnormal update rate" 8 "Abnormal frequency" 7 "Mechanical system not responding" 6 "Current above normal" 5 "Current below normal" 4 "Voltage below normal" 3 "Voltage above normal" 2 "Data erratic" 1 "Below normal (most severe)" 0 "Above normal (most severe)" ;
VAL_ 2555576062 MalfunctionIndicatorLampStatus 3 "Not available" 2 "Reserved" 1 "Lamp on" 0 "Lamp off" ;
VAL_ 2555576062 RedStopLampState 3 "Not available" 2 "Reserved" 1 "Lamp on" 0 "Lamp off" ;
VAL_ 2555576062 AmberWarningLampStatus 3 "Not available" 2 "Reserved" 1 "Lamp on" 0 "Lamp off" ;
VAL_ 2555576062 ProtectLampStatus 3 "Not available" 2 "Reserved" 1 "Lamp on" 0 "Lamp off" ;
VAL_ 2555576062 FailureModeIdentifier3 31 "Not available" 19 "Received network data in error" 18 "Below normal (moderatels severe)" 17 "Below normal (least severe)" 16 "Above normal (moderately severe)" 15 "Above normal (least severe)" 14 "Special intstructions" 13 "Out of calibration" 12 "Bad intelligent device" 11 "Root cause not known" 10 "Abnormal rate of change" 9 "Abnormal update rate" 8 "Abnormal frequency" 7 "Mechanical system not responding" 6 "Current above normal" 5 "Current below normal" 4 "Voltage below normal" 3 "Voltage above normal" 2 "Data erratic" 1 "Below normal (most severe)" 0 "Above normal (most severe)" ;
VAL_ 2555576062 FailureModeIdentifier2 31 "Not available" 19 "Received network data in error" 18 "Below normal (moderatels severe)" 17 "Below normal (least severe)" 16 "Above normal (moderately severe)" 15 "Above normal (least severe)" 14 "Special intstructions" 13 "Out of calibration" 12 "Bad intelligent device" 11 "Root cause not known" 10 "Abnormal rate of change" 9 "Abnormal update rate" 8 "Abnormal frequency" 7 "Mechanical system not responding" 6 "Current above normal" 5 "Current below normal" 4 "Voltage below normal" 3 "Voltage above normal" 2 "Data erratic" 1 "Below normal (most severe)" 0 "Above normal (most severe)" ;
VAL_ 2562981630 FailureModeIdentifier1 31 "Not available" 19 "Received network data in error" 18 "Below normal (moderatels severe)" 17 "Below normal (least severe)" 16 "Above normal (moderately severe)" 15 "Above normal (least severe)" 14 "Special intstructions" 13 "Out of calibration" 12 "Bad intelligent device" 11 "Root cause not known" 10 "Abnormal rate of change" 9 "Abnormal update rate" 8 "Abnormal frequency" 7 "Mechanical system not responding" 6 "Current above normal" 5 "Current below normal" 4 "Voltage below normal" 3 "Voltage above normal" 2 "Data erratic" 1 "Below normal (most severe)" 0 "Above normal (most severe)" ;
VAL_ 2566835198 FailureModeIdentifier5 31 "Not available" 19 "Received network data in error" 18 "Below normal (moderatels severe)" 17 "Below normal (least severe)" 16 "Above normal (moderately severe)" 15 "Above normal (least severe)" 14 "Special intstructions" 13 "Out of calibration" 12 "Bad intelligent device" 11 "Root cause not known" 10 "Abnormal rate of change" 9 "Abnormal update rate" 8 "Abnormal frequency" 7 "Mechanical system not responding" 6 "Current above normal" 5 "Current below normal" 4 "Voltage below normal" 3 "Voltage above normal" 2 "Data erratic" 1 "Below normal (most severe)" 0 "Above normal (most severe)" ;
VAL_ 2566835198 FailureModeIdentifier4 31 "Not available" 19 "Received network data in error" 18 "Below normal (moderatels severe)" 17 "Below normal (least severe)" 16 "Above normal (moderately severe)" 15 "Above normal (least severe)" 14 "Special intstructions" 13 "Out of calibration" 12 "Bad intelligent device" 11 "Root cause not known" 10 "Abnormal rate of change" 9 "Abnormal update rate" 8 "Abnormal frequency" 7 "Mechanical system not responding" 6 "Current above normal" 5 "Current below normal" 4 "Voltage below normal" 3 "Voltage above normal" 2 "Data erratic" 1 "Below normal (most severe)" 0 "Above normal (most severe)" ;
VAL_ 2566835198 FailureModeIdentifier1 31 "Not available" 19 "Received network data in error" 18 "Below normal (moderatels severe)" 17 "Below normal (least severe)" 16 "Above normal (moderately severe)" 15 "Above normal (least severe)" 14 "Special intstructions" 13 "Out of calibration" 12 "Bad intelligent device" 11 "Root cause not known" 10 "Abnormal rate of change" 9 "Abnormal update rate" 8 "Abnormal frequency" 7 "Mechanical system not responding" 6 "Current above normal" 5 "Current below normal" 4 "Voltage below normal" 3 "Voltage above normal" 2 "Data erratic" 1 "Below normal (most severe)" 0 "Above normal (most severe)" ;
VAL_ 2566835198 MalfunctionIndicatorLampStatus 3 "Not available" 2 "Reserved" 1 "Lamp on" 0 "Lamp off" ;
VAL_ 2566835198 RedStopLampState 3 "Not available" 2 "Reserved" 1 "Lamp on" 0 "Lamp off" ;
VAL_ 2566835198 AmberWarningLampStatus 3 "Not available" 2 "Reserved" 1 "Lamp on" 0 "Lamp off" ;
VAL_ 2566835198 ProtectLampStatus 3 "Not available" 2 "Reserved" 1 "Lamp on" 0 "Lamp off" ;
VAL_ 2566835198 FailureModeIdentifier3 31 "Not available" 19 "Received network data in error" 18 "Below normal (moderatels severe)" 17 "Below normal (least severe)" 16 "Above normal (moderately severe)" 15 "Above normal (least severe)" 14 "Special intstructions" 13 "Out of calibration" 12 "Bad intelligent device" 11 "Root cause not known" 10 "Abnormal rate of change" 9 "Abnormal update rate" 8 "Abnormal frequency" 7 "Mechanical system not responding" 6 "Current above normal" 5 "Current below normal" 4 "Voltage below normal" 3 "Voltage above normal" 2 "Data erratic" 1 "Below normal (most severe)" 0 "Above normal (most severe)" ;
VAL_ 2566835198 FlashRedStopLamp 3 "Unavailable / Do Not Flash" 2 "Reserved" 1 "Fast Flash" 0 "Slow Flash" ;
VAL_ 2566835198 FlashProtectLamp 3 "Unavailable / Do Not Flash" 2 "Reserved" 1 "Fast Flash" 0 "Slow Flash" ;
VAL_ 2566835198 FlashMalfuncIndicatorLamp 3 "Unavailable / Do Not Flash" 2 "Reserved" 1 "Fast Flash" 0 "Slow Flash" ;
VAL_ 2566835198 FlashAmberWarningLamp 3 "Unavailable / Do Not Flash" 2 "Reserved" 1 "Fast Flash" 0 "Slow Flash" ;
VAL_ 2566835198 FailureModeIdentifier2 31 "Not available" 19 "Received network data in error" 18 "Below normal (moderatels severe)" 17 "Below normal (least severe)" 16 "Above normal (moderately severe)" 15 "Above normal (least severe)" 14 "Special intstructions" 13 "Out of calibration" 12 "Bad intelligent device" 11 "Root cause not known" 10 "Abnormal rate of change" 9 "Abnormal update rate" 8 "Abnormal frequency" 7 "Mechanical system not responding" 6 "Current above normal" 5 "Current below normal" 4 "Voltage below normal" 3 "Voltage above normal" 2 "Data erratic" 1 "Below normal (most severe)" 0 "Above normal (most severe)" ;
VAL_ 2564357886 Seed 255 "NoFurtherKeyRequiredOfTool" 1 "UseLongSeedOrKeyFromDataSecMsg" 0 "SeedCompleted_BeginSendingKey" ;
VAL_ 2564357886 EDCP_Extension 9 "DataInErrIndAndDataInSeedIsTime" 6 "DataInErrorIndicator" 3 "ConcatenateDataAsLowerEDCParam" 2 "ConcatenateDataAsHigherEDCParam" 0 "Completed" 255 "NoErrIndicator/EDCParamAvailable" ;
VAL_ 2564357886 ErrorIndicator 16777215 "NoErrorIndicatorAvailable" 65540 "TransprtNotComplWithinTimeAllowd" 65539 "TransportNotInitWithinTimeAllowd" 65538 "NoResponseInTheTimeAllowed" 65537 "ModuleExceedingNumberOfRetries" 65536 "AbortFromExtToNormalSoftwareProc" 4103 "VehicleNotInParkOrNotStationary" 4102 "EngineRunning" 4101 "NotInEngineeringOrDevelopmentMode" 4100 "NotInDiagnosticMode" 4099 "InvalidKey" 4098 "InvalidUserLevel" 4097 "InvalidPassword" 4096 "SecurityErrorGeneral" 266 "NameDoesNotConformToExpectdValue" 265 "DataDoesNotConformToValueRanges" 264 "AddrForBootLoadExeInvalidBoundary" 263 "AddrForBootLoadExeOutsideExeMem" 262 "OpReqExeTransfAndEraseOfProgMem" 261 "OpRequiresPriorEraseOfProgramMem" 260 "OpRequiresPriorEraseOfDataMem" 259 "ReqMemoryExceededAvailableMemory" 258 "LengthNotValidForMemStructAndOp" 257 "AddressNotOnValidBoundary" 256 "AddressingOrDataGeneralError" 36 "InternalFailurePreventingReq" 35 "PROMDidNotVerifyOnWrite" 34 "FLASHDidNotVerifyOnWrite" 33 "RAMDidNotVerifyOnWrite" 32 "EDCParaNotCorrectForDataStream" 31 "ProcessUnspecReqFromThisAddress" 23 "ProcessingEDCPGenerationReq" 22 "ProcessingBootLoadReq" 19 "ProcessingStatusReq" 18 "ProcessingWriteReq" 17 "ProcessingReadReq" 16 "ProcessingEraseReq" 2 "ProcessingForSomeoneElse" 1 "ErrorNotIdentified" 0 "NoError" ;
VAL_ 2564357886 Status 7 "Reserved4" 6 "Reserved3" 5 "OperationFailed" 4 "OperationCompleted" 3 "Reserved2" 2 "Reserved1" 1 "Busy" 0 "Proceed" ;
VAL_ 2564423422 KeyOrUserLevel 65535 "NoKeyAvailable" 0 "UseLongSeedOrKey" ;
VAL_ 2564423422 PointerExtension 0 "SPN_SPACE" ;
VAL_ 2564423422 Command 7 "EDCP_Generation" 6 "BootLoad" 5 "OperationFailed" 4 "OperationCompleted" 3 "StatusRequest" 2 "Write" 1 "Read" 0 "Erase" ;
VAL_ 2564423422 PointerType 1 "DirectedSpatialAddressing" 0 "DirectMemoryAddressing" ;
VAL_ 2564816638 HoldSignal 15 "Not available" 1 "Devices whose broadcast state ha" 0 "All devices" ;
VAL_ 2564816638 J1939Network3 3 "Don't care" 2 "Reserved" 1 "Start broadcast" 0 "Stop broadcast" ;
VAL_ 2564816638 J1939Network2 3 "Don't care" 2 "Reserved" 1 "Start broadcast" 0 "Stop broadcast" ;
VAL_ 2564816638 ISO9141 3 "Don't care" 2 "Reserved" 1 "Start broadcast" 0 "Stop broadcast" ;
VAL_ 2564816638 SAE_J1850 3 "Don't care" 2 "Reserved" 1 "Start broadcast" 0 "Stop broadcast" ;
VAL_ 2564816638 ManufacturerSpecificPort 3 "Don't care" 2 "Reserved" 1 "Start broadcast" 0 "Stop broadcast" ;
VAL_ 2564816638 CurrentDataLink 3 "Don't care" 2 "Reserved" 1 "Start broadcast" 0 "Stop broadcast" ;
VAL_ 2564816638 SAE_J1587 3 "Don't care" 2 "Reserved" 1 "Start broadcast" 0 "Stop broadcast" ;
VAL_ 2564816638 SAE_J1922 3 "Don't care" 2 "Reserved" 1 "Start broadcast" 0 "Stop broadcast" ;
VAL_ 2564816638 J1939Network1 3 "Don't care" 2 "Reserved" 1 "Start broadcast" 0 "Stop broadcast" ;
VAL_ 2564816638 SuspendSignal 15 "NotAvailable" 14 "ResumingNormalBroadcastPattern" 3 "TemporarySuspensionOfSomeMessages" 2 "TemporarySuspensionOfAllBroadcasts" 1 "IndefiniteSuspensionOfSomeMessages" 0 "IndefiniteSuspensionOfAllBroadcasts" ;
VAL_ 2566837502 FlashRedStopLamp 3 "Unavailable / Do Not Flash" 2 "Reserved" 1 "Fast Flash" 0 "Slow Flash" ;
VAL_ 2566837502 FlashProtectLamp 3 "Unavailable / Do Not Flash" 2 "Reserved" 1 "Fast Flash" 0 "Slow Flash" ;
VAL_ 2566837502 FailureModeIdentifier5 31 "Not available" 19 "Received network data in error" 18 "Below normal (moderatels severe)" 17 "Below normal (least severe)" 16 "Above normal (moderately severe)" 15 "Above normal (least severe)" 14 "Special intstructions" 13 "Out of calibration" 12 "Bad intelligent device" 11 "Root cause not known" 10 "Abnormal rate of change" 9 "Abnormal update rate" 8 "Abnormal frequency" 7 "Mechanical system not responding" 6 "Current above normal" 5 "Current below normal" 4 "Voltage below normal" 3 "Voltage above normal" 2 "Data erratic" 1 "Below normal (most severe)" 0 "Above normal (most severe)" ;
VAL_ 2566837502 FailureModeIdentifier4 31 "Not available" 19 "Received network data in error" 18 "Below normal (moderatels severe)" 17 "Below normal (least severe)" 16 "Above normal (moderately severe)" 15 "Above normal (least severe)" 14 "Special intstructions" 13 "Out of calibration" 12 "Bad intelligent device" 11 "Root cause not known" 10 "Abnormal rate of change" 9 "Abnormal update rate" 8 "Abnormal frequency" 7 "Mechanical system not responding" 6 "Current above normal" 5 "Current below normal" 4 "Voltage below normal" 3 "Voltage above normal" 2 "Data erratic" 1 "Below normal (most severe)" 0 "Above normal (most severe)" ;
VAL_ 2566837502 FailureModeIdentifier3 31 "Not available" 19 "Received network data in error" 18 "Below normal (moderatels severe)" 17 "Below normal (least severe)" 16 "Above normal (moderately severe)" 15 "Above normal (least severe)" 14 "Special intstructions" 13 "Out of calibration" 12 "Bad intelligent device" 11 "Root cause not known" 10 "Abnormal rate of change" 9 "Abnormal update rate" 8 "Abnormal frequency" 7 "Mechanical system not responding" 6 "Current above normal" 5 "Current below normal" 4 "Voltage below normal" 3 "Voltage above normal" 2 "Data erratic" 1 "Below normal (most severe)" 0 "Above normal (most severe)" ;
VAL_ 2566837502 FailureModeIdentifier1 31 "Not available" 19 "Received network data in error" 18 "Below normal (moderatels severe)" 17 "Below normal (least severe)" 16 "Above normal (moderately severe)" 15 "Above normal (least severe)" 14 "Special intstructions" 13 "Out of calibration" 12 "Bad intelligent device" 11 "Root cause not known" 10 "Abnormal rate of change" 9 "Abnormal update rate" 8 "Abnormal frequency" 7 "Mechanical system not responding" 6 "Current above normal" 5 "Current below normal" 4 "Voltage below normal" 3 "Voltage above normal" 2 "Data erratic" 1 "Below normal (most severe)" 0 "Above normal (most severe)" ;
VAL_ 2566837502 MalfunctionIndicatorLampStatus 3 "Not available" 2 "Reserved" 1 "Lamp on" 0 "Lamp off" ;
VAL_ 2566837502 RedStopLampState 3 "Not available" 2 "Reserved" 1 "Lamp on" 0 "Lamp off" ;
VAL_ 2566837502 AmberWarningLampStatus 3 "Not available" 2 "Reserved" 1 "Lamp on" 0 "Lamp off" ;
VAL_ 2566837502 ProtectLampStatus 3 "Not available" 2 "Reserved" 1 "Lamp on" 0 "Lamp off" ;
VAL_ 2566837502 FlashMalfuncIndicatorLamp 3 "Unavailable / Do Not Flash" 2 "Reserved" 1 "Fast Flash" 0 "Slow Flash" ;
VAL_ 2566837502 FlashAmberWarningLamp 3 "Unavailable / Do Not Flash" 2 "Reserved" 1 "Fast Flash" 0 "Slow Flash" ;
VAL_ 2566837502 FailureModeIdentifier2 31 "Not available" 19 "Received network data in error" 18 "Below normal (moderatels severe)" 17 "Below normal (least severe)" 16 "Above normal (moderately severe)" 15 "Above normal (least severe)" 14 "Special intstructions" 13 "Out of calibration" 12 "Bad intelligent device" 11 "Root cause not known" 10 "Abnormal rate of change" 9 "Abnormal update rate" 8 "Abnormal frequency" 7 "Mechanical system not responding" 6 "Current above normal" 5 "Current below normal" 4 "Voltage below normal" 3 "Voltage above normal" 2 "Data erratic" 1 "Below normal (most severe)" 0 "Above normal (most severe)" ;
VAL_ 2566834942 FailureModeIdentifier5 31 "Not available" 19 "Received network data in error" 18 "Below normal (moderatels severe)" 17 "Below normal (least severe)" 16 "Above normal (moderately severe)" 15 "Above normal (least severe)" 14 "Special intstructions" 13 "Out of calibration" 12 "Bad intelligent device" 11 "Root cause not known" 10 "Abnormal rate of change" 9 "Abnormal update rate" 8 "Abnormal frequency" 7 "Mechanical system not responding" 6 "Current above normal" 5 "Current below normal" 4 "Voltage below normal" 3 "Voltage above normal" 2 "Data erratic" 1 "Below normal (most severe)" 0 "Above normal (most severe)" ;
VAL_ 2566834942 FailureModeIdentifier4 31 "Not available" 19 "Received network data in error" 18 "Below normal (moderatels severe)" 17 "Below normal (least severe)" 16 "Above normal (moderately severe)" 15 "Above normal (least severe)" 14 "Special intstructions" 13 "Out of calibration" 12 "Bad intelligent device" 11 "Root cause not known" 10 "Abnormal rate of change" 9 "Abnormal update rate" 8 "Abnormal frequency" 7 "Mechanical system not responding" 6 "Current above normal" 5 "Current below normal" 4 "Voltage below normal" 3 "Voltage above normal" 2 "Data erratic" 1 "Below normal (most severe)" 0 "Above normal (most severe)" ;
VAL_ 2566834942 FailureModeIdentifier3 31 "Not available" 19 "Received network data in error" 18 "Below normal (moderatels severe)" 17 "Below normal (least severe)" 16 "Above normal (moderately severe)" 15 "Above normal (least severe)" 14 "Special intstructions" 13 "Out of calibration" 12 "Bad intelligent device" 11 "Root cause not known" 10 "Abnormal rate of change" 9 "Abnormal update rate" 8 "Abnormal frequency" 7 "Mechanical system not responding" 6 "Current above normal" 5 "Current below normal" 4 "Voltage below normal" 3 "Voltage above normal" 2 "Data erratic" 1 "Below normal (most severe)" 0 "Above normal (most severe)" ;
VAL_ 2566834942 FlashRedStopLamp 3 "Unavailable / Do Not Flash" 2 "Reserved" 1 "Fast Flash" 0 "Slow Flash" ;
VAL_ 2566834942 FlashProtectLamp 3 "Unavailable / Do Not Flash" 2 "Reserved" 1 "Fast Flash" 0 "Slow Flash" ;
VAL_ 2566834942 FlashMalfuncIndicatorLamp 3 "Unavailable / Do Not Flash" 2 "Reserved" 1 "Fast Flash" 0 "Slow Flash" ;
VAL_ 2566834942 FlashAmberWarningLamp 3 "Unavailable / Do Not Flash" 2 "Reserved" 1 "Fast Flash" 0 "Slow Flash" ;
VAL_ 2566834942 MalfunctionIndicatorLampStatus 3 "Not available" 2 "Reserved" 1 "Lamp on" 0 "Lamp off" ;
VAL_ 2566834942 AmberWarningLampStatus 3 "Not available" 2 "Reserved" 1 "Lamp on" 0 "Lamp off" ;
VAL_ 2566834942 FailureModeIdentifier1 31 "Not available" 19 "Received network data in error" 18 "Below normal (moderatels severe)" 17 "Below normal (least severe)" 16 "Above normal (moderately severe)" 15 "Above normal (least severe)" 14 "Special intstructions" 13 "Out of calibration" 12 "Bad intelligent device" 11 "Root cause not known" 10 "Abnormal rate of change" 9 "Abnormal update rate" 8 "Abnormal frequency" 7 "Mechanical system not responding" 6 "Current above normal" 5 "Current below normal" 4 "Voltage below normal" 3 "Voltage above normal" 2 "Data erratic" 1 "Below normal (most severe)" 0 "Above normal (most severe)" ;
VAL_ 2566834942 RedStopLampState 3 "Not available" 2 "Reserved" 1 "Lamp on" 0 "Lamp off" ;
VAL_ 2566834942 ProtectLampStatus 3 "Not available" 2 "Reserved" 1 "Lamp on" 0 "Lamp off" ;
VAL_ 2566834942 FailureModeIdentifier2 31 "Not available" 19 "Received network data in error" 18 "Below normal (moderatels severe)" 17 "Below normal (least severe)" 16 "Above normal (moderately severe)" 15 "Above normal (least severe)" 14 "Special intstructions" 13 "Out of calibration" 12 "Bad intelligent device" 11 "Root cause not known" 10 "Abnormal rate of change" 9 "Abnormal update rate" 8 "Abnormal frequency" 7 "Mechanical system not responding" 6 "Current above normal" 5 "Current below normal" 4 "Voltage below normal" 3 "Voltage above normal" 2 "Data erratic" 1 "Below normal (most severe)" 0 "Above normal (most severe)" ;
